VERSION ""

NS_ :

BS_:

BU_: CVC_B BCM_FL BCM_FR DUMMY_ECU DKCU BCM_R

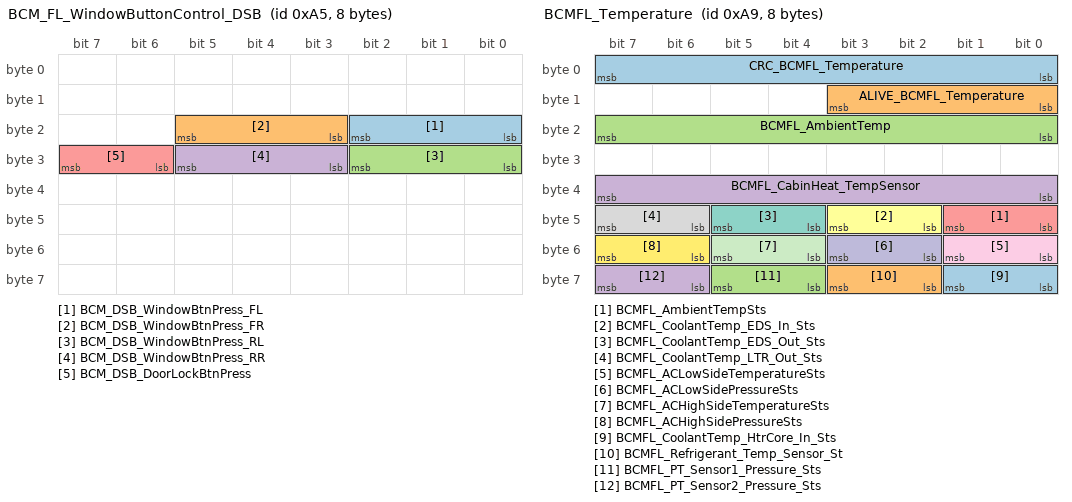
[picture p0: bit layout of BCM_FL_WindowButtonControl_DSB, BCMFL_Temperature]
BO_ 165 BCM_FL_WindowButtonControl_DSB: 8 BCM_FL
 SG_ BCM_DSB_WindowBtnPress_FL : 18|3@0+ (1,0) [0|7] ""  CVC_B
 SG_ BCM_DSB_WindowBtnPress_FR : 21|3@0+ (1,0) [0|7] ""  CVC_B
 SG_ BCM_DSB_WindowBtnPress_RL : 26|3@0+ (1,0) [0|7] ""  CVC_B
 SG_ BCM_DSB_WindowBtnPress_RR : 29|3@0+ (1,0) [0|7] ""  CVC_B
 SG_ BCM_DSB_DoorLockBtnPress : 31|2@0+ (1,0) [0|3] ""  CVC_B

BO_ 169 BCMFL_Temperature: 8 BCM_FL
 SG_ CRC_BCMFL_Temperature : 7|8@0+ (1,0) [0|255] ""  CVC_B,BCM_FR,DKCU,BCM_R
 SG_ ALIVE_BCMFL_Temperature : 11|4@0+ (1,0) [0|15] ""  CVC_B,BCM_FR,DKCU,BCM_R
 SG_ BCMFL_AmbientTemp : 23|8@0+ (0.5,-40) [-40|85] "Degree C"  CVC_B,BCM_FR,DKCU,BCM_R
 SG_ BCMFL_CabinHeat_TempSensor : 39|8@0+ (0.5,-40) [-40|85] "Degree C"  CVC_B,BCM_FR,DKCU,BCM_R
 SG_ BCMFL_AmbientTempSts : 41|2@0+ (1,0) [0|3] ""  CVC_B
 SG_ BCMFL_CoolantTemp_EDS_In_Sts : 43|2@0+ (1,0) [0|3] ""  CVC_B
 SG_ BCMFL_CoolantTemp_EDS_Out_Sts : 45|2@0+ (1,0) [0|3] ""  CVC_B
 SG_ BCMFL_CoolantTemp_LTR_Out_Sts : 47|2@0+ (1,0) [0|3] ""  CVC_B
 SG_ BCMFL_ACLowSideTemperatureSts : 49|2@0+ (1,0) [0|3] ""  CVC_B
 SG_ BCMFL_ACLowSidePressureSts : 51|2@0+ (1,0) [0|3] ""  CVC_B
 SG_ BCMFL_ACHighSideTemperatureSts : 53|2@0+ (1,0) [0|3] ""  CVC_B
 SG_ BCMFL_ACHighSidePressureSts : 55|2@0+ (1,0) [0|3] ""  CVC_B
 SG_ BCMFL_CoolantTemp_HtrCore_In_Sts : 57|2@0+ (1,0) [0|3] ""  CVC_B
 SG_ BCMFL_Refrigerant_Temp_Sensor_St : 59|2@0+ (1,0) [0|3] ""  CVC_B
 SG_ BCMFL_PT_Sensor1_Pressure_Sts : 61|2@0+ (1,0) [0|3] ""  CVC_B
 SG_ BCMFL_PT_Sensor2_Pressure_Sts : 63|2@0+ (1,0) [0|3] ""  CVC_B

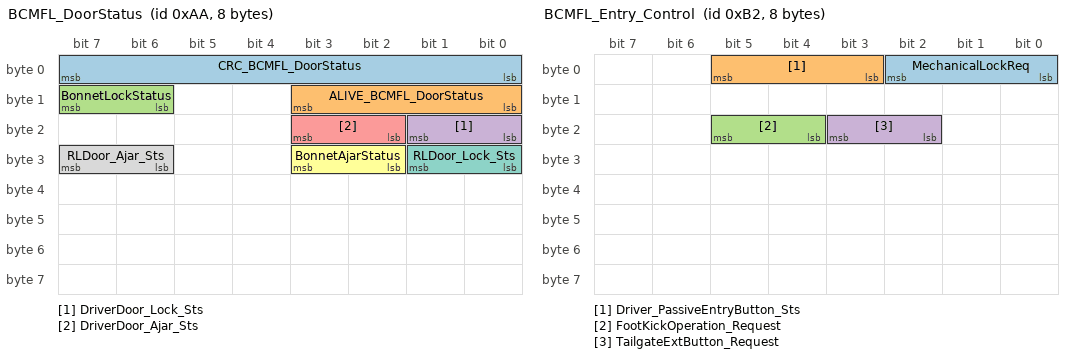
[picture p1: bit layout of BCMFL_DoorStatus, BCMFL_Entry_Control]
BO_ 170 BCMFL_DoorStatus: 8 BCM_FL
 SG_ CRC_BCMFL_DoorStatus : 7|8@0+ (1,0) [0|255] ""  CVC_B,DKCU
 SG_ ALIVE_BCMFL_DoorStatus : 11|4@0+ (1,0) [0|15] ""  CVC_B,DKCU
 SG_ BonnetLockStatus : 15|2@0+ (1,0) [0|3] ""  CVC_B,DKCU
 SG_ DriverDoor_Lock_Sts : 17|2@0+ (1,0) [0|3] ""  CVC_B,DKCU
 SG_ DriverDoor_Ajar_Sts : 19|2@0+ (1,0) [0|3] ""  CVC_B,DKCU
 SG_ BonnetAjarStatus : 27|2@0+ (1,0) [0|3] ""  CVC_B,DKCU
 SG_ RLDoor_Lock_Sts : 25|2@0+ (1,0) [0|3] ""  CVC_B,DKCU
 SG_ RLDoor_Ajar_Sts : 31|2@0+ (1,0) [0|3] ""  CVC_B,DKCU

BO_ 178 BCMFL_Entry_Control: 8 BCM_FL
 SG_ MechanicalLockReq : 2|3@0+ (1,0) [0|4] ""  CVC_B,DKCU
 SG_ Driver_PassiveEntryButton_Sts : 5|3@0+ (1,0) [0|4] ""  CVC_B,DKCU
 SG_ FootKickOperation_Request : 21|2@0+ (1,0) [0|3] ""  CVC_B,DKCU
 SG_ TailgateExtButton_Request : 19|2@0+ (1,0) [0|2] ""  CVC_B,DKCU

BO_ 180 BCM_WindowsFL_Status: 8 BCM_R
 SG_ CRC_BCM_WindowsFL_Status : 7|8@0+ (1,0) [0|255] ""  CVC_B
 SG_ ALIVE_BCM_WindowsFL_Status : 11|4@0+ (1,0) [0|15] ""  CVC_B
 SG_ BCMFL_WindowsFL_AntiPinch_Warn : 19|2@0+ (1,0) [0|3] ""  CVC_B
 SG_ BCMFL_WindowFL_Learning_Sts : 23|2@0+ (1,0) [0|3] ""  CVC_B
 SG_ BCMFL_WindowFL_Suppression_Warn : 25|2@0+ (1,0) [0|2] ""  CVC_B
 SG_ BCMFL_WindowFL_LockActive : 26|1@0+ (1,0) [0|1] ""  CVC_B
 SG_ BCMFL_WindowFL_ThermalProtect : 29|2@0+ (1,0) [0|2] ""  CVC_B
 SG_ BCMFL_WindowFL_Error : 27|1@0+ (1,0) [0|1] ""  CVC_B
 SG_ BCMFL_WindowsRL_AntiPinch_Warn : 33|2@0+ (1,0) [0|3] ""  CVC_B
 SG_ BCMFL_WindowRL_LockActive : 35|1@0+ (1,0) [0|1] ""  CVC_B
 SG_ BCMFL_WindowRL_Error : 34|1@0+ (1,0) [0|1] ""  CVC_B
 SG_ BCMFL_WindowRL_Learning_Sts : 37|2@0+ (1,0) [0|3] ""  CVC_B
 SG_ BCMFL_WindowRL_Suppression_Warn : 39|2@0+ (1,0) [0|2] ""  CVC_B
 SG_ BCMFL_WindowRL_ThermalProtect : 41|2@0+ (1,0) [0|2] ""  CVC_B
 SG_ Window_Position_FL : 51|4@0+ (1,0) [0|15] ""  CVC_B
 SG_ Window_Position_RL : 55|4@0+ (1,0) [0|15] ""  CVC_B
 SG_ BCMFL_WindowBtnPress_RL : 44|3@0+ (1,0) [0|4] ""  CVC_B
 SG_ BCMFL_WindowBtnPress_FL : 47|3@0+ (1,0) [0|4] ""  CVC_B
 SG_ BCMFL_WindowFL_Malfunction_Warn : 63|2@0+ (1,0) [0|3] ""  CVC_B
 SG_ BCMFL_WindowRL_Malfunction_Warn : 61|2@0+ (1,0) [0|3] ""  CVC_B

BO_ 198 BCMFL_ThermalComponents_Status_1: 32 BCM_FL
 SG_ CRC_BCMFL_ThermalComponents_Stat : 7|8@0+ (1,0) [0|255] ""  CVC_B
 SG_ ALIVE_BCMFL_ThermalComponents_St : 11|4@0+ (1,0) [0|15] ""  CVC_B
 SG_ BCMFL_CoolantLevel : 13|2@0+ (1,0) [0|3] ""  CVC_B
 SG_ BCMFL_CoolingFan_Status : 15|2@0+ (1,0) [0|3] ""  CVC_B
 SG_ BCMFL_FEDSPump_Status : 17|2@0+ (1,0) [0|3] ""  CVC_B
 SG_ BCMFL_BMSPump_Status : 19|2@0+ (1,0) [0|3] ""  CVC_B
 SG_ BCMFL_REDSPump_Status : 21|2@0+ (1,0) [0|3] ""  CVC_B
 SG_ BCMFL_HVMainRelay_Status : 23|2@0+ (1,0) [0|3] ""  CVC_B
 SG_ BCMFL_ACLowSidePressure : 31|7@0+ (0.1,0) [0|10.86] "Bar"  CVC_B
 SG_ BCMFL_ACHighSidePressure : 24|9@0+ (0.1,0) [0|37.27] "Bar"  CVC_B
 SG_ BCMFL_CoolantTemp_LTR_Out : 207|11@0+ (1,-40) [-40|130] "Degree C"  CVC_B
 SG_ BCMFL_CoolantTemp_EDS_In : 159|11@0+ (1,-40) [-40|130] "Degree C"  CVC_B
 SG_ BCMFL_CoolantTemp_EDS_Out : 191|11@0+ (1,-40) [-40|130] "Degree C"  CVC_B
 SG_ BCMFL_ACLowSideTemperature : 239|11@0+ (0.1,-40) [-40|150] "Degree C"  CVC_B
 SG_ BCMFL_ACHighSideTemperature : 223|11@0+ (0.1,-40) [-40|150] "Degree C"  CVC_B
 SG_ BCMFL_CoolantTemp_HtrCore_In : 175|11@0+ (1,-40) [-40|130] "Degree C"  CVC_B
 SG_ BCMFL_FEDSPump_Fault : 108|3@0+ (1,0) [0|7] ""  CVC_B
 SG_ BCMFL_BMSPump_Fault : 111|3@0+ (1,0) [0|7] ""  CVC_B
 SG_ BCMFL_SOV_Fault : 113|2@0+ (1,0) [0|3] ""  CVC_B
 SG_ BCMFL_CoolingFan_Fault : 116|3@0+ (1,0) [0|7] ""  CVC_B
 SG_ BCMFL_CoolantLevel2 : 118|2@0+ (1,0) [0|3] ""  CVC_B
 SG_ BCMFL_Refrigerant_Temp_Sensor : 55|8@0+ (1,-40) [-40|130] "Degree C"  CVC_B
 SG_ BCMFL_PT_Sensor1_Pressure : 151|8@0+ (1,0) [0|37.27] "Bar"  CVC_B
 SG_ BCMFL_PT_Sensor1_Temp : 135|8@0+ (1,-40) [-40|150] "Degree C"  CVC_B
 SG_ BCMFL_PT_Sensor2_Pressure : 143|8@0+ (1,0) [0|37.27] "Bar"  CVC_B
 SG_ BCMFL_PT_Sensor2_Temp : 127|8@0+ (1,-40) [-40|150] "Degree C"  CVC_B
 SG_ BCMFL_RearACLowSidePressureSts : 101|2@0+ (1,0) [0|3] ""  CVC_B
 SG_ BCMFL_RearACLowSideTemperatureSt : 99|2@0+ (1,0) [0|3] ""  CVC_B
 SG_ BCMFL_REDSPump_Fault : 105|3@0+ (1,0) [0|7] ""  CVC_B
 SG_ BCMFL_RearACLowSidePressure : 63|7@0+ (0.1,0) [0|10.86] "Bar"  CVC_B
 SG_ BCMFL_RearACLowSideTemperature : 56|11@0+ (0.1,-40) [-40|150] "Degree C"  CVC_B

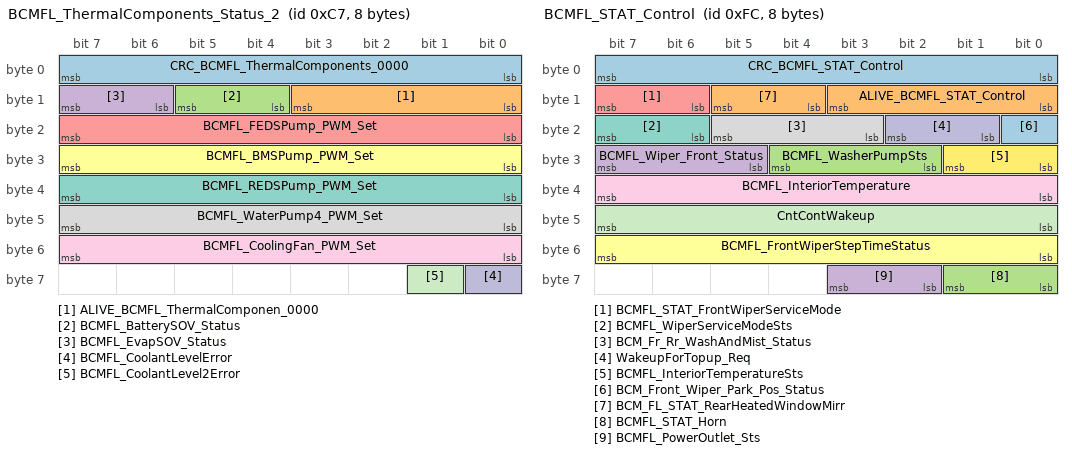
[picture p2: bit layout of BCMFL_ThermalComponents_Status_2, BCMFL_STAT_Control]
BO_ 199 BCMFL_ThermalComponents_Status_2: 8 BCM_FL
 SG_ CRC_BCMFL_ThermalComponents_0000 : 7|8@0+ (1,0) [0|255] ""  CVC_B
 SG_ ALIVE_BCMFL_ThermalComponen_0000 : 11|4@0+ (1,0) [0|15] ""  CVC_B
 SG_ BCMFL_BatterySOV_Status : 13|2@0+ (1,0) [0|3] ""  CVC_B
 SG_ BCMFL_EvapSOV_Status : 15|2@0+ (1,0) [0|3] ""  CVC_B
 SG_ BCMFL_FEDSPump_PWM_Set : 23|8@0+ (1,0) [0|100] "%"  CVC_B
 SG_ BCMFL_BMSPump_PWM_Set : 31|8@0+ (1,0) [0|100] "%"  CVC_B
 SG_ BCMFL_REDSPump_PWM_Set : 39|8@0+ (1,0) [0|100] "%"  CVC_B
 SG_ BCMFL_WaterPump4_PWM_Set : 47|8@0+ (1,0) [0|100] "%"  CVC_B
 SG_ BCMFL_CoolingFan_PWM_Set : 55|8@0+ (1,0) [0|100] "%"  CVC_B
 SG_ BCMFL_CoolantLevelError : 56|1@0+ (1,0) [0|1] ""  CVC_B
 SG_ BCMFL_CoolantLevel2Error : 57|1@0+ (1,0) [0|1] ""  CVC_B

BO_ 252 BCMFL_STAT_Control: 8 BCM_FL
 SG_ CRC_BCMFL_STAT_Control : 7|8@0+ (1,0) [0|255] ""  CVC_B
 SG_ ALIVE_BCMFL_STAT_Control : 11|4@0+ (1,0) [0|15] ""  CVC_B
 SG_ BCMFL_WasherPumpSts : 28|3@0+ (1,0) [0|3] ""  CVC_B
 SG_ BCMFL_Wiper_Front_Status : 31|3@0+ (1,0) [0|4] ""  CVC_B
 SG_ BCMFL_STAT_FrontWiperServiceMode : 15|2@0+ (1,0) [0|3] ""  CVC_B
 SG_ BCMFL_FrontWiperStepTimeStatus : 55|8@0+ (1,0) [0|255] "second"  CVC_B
 SG_ BCMFL_WiperServiceModeSts : 23|2@0+ (1,0) [0|2] ""  CVC_B
 SG_ BCM_Fr_Rr_WashAndMist_Status : 21|3@0+ (1,0) [0|7] ""  CVC_B
 SG_ BCMFL_InteriorTemperature : 39|8@0+ (1,-40) [-40|85] "Degree C"  CVC_B
 SG_ WakeupForTopup_Req : 18|2@0+ (1,0) [0|3] ""  CVC_B
 SG_ CntContWakeup : 47|8@0+ (1,0) [0|255] ""  CVC_B
 SG_ BCMFL_InteriorTemperatureSts : 25|2@0+ (1,0) [0|3] ""  CVC_B
 SG_ BCM_Front_Wiper_Park_Pos_Status : 16|1@0+ (1,0) [0|1] ""  CVC_B
 SG_ BCM_FL_STAT_RearHeatedWindowMirr : 13|2@0+ (1,0) [0|3] ""  CVC_B
 SG_ BCMFL_STAT_Horn : 57|2@0+ (1,0) [0|3] ""  CVC_B
 SG_ BCMFL_PowerOutlet_Sts : 59|2@0+ (1,0) [0|3] ""  CVC_B

BO_ 260 BCM_FL_Measured_Data: 12 BCM_FL
 SG_ CRC_BCM_FL_Measured_Data : 7|8@0+ (1,0) [0|255] ""  CVC_B
 SG_ ALIVE_BCM_FL_Measured_Data : 11|4@0+ (1,0) [0|15] ""  CVC_B
 SG_ SOH_SUL : 23|8@0+ (1,0) [0|100] "%"  CVC_B
 SG_ SOH_SUL_STATE : 29|2@0+ (1,0) [0|3] ""  CVC_B
 SG_ SOC_STATE : 31|2@0+ (1,0) [0|3] ""  CVC_B
 SG_ Resp_Error : 35|1@0+ (1,0) [0|1] ""  CVC_B
 SG_ FLAG_INCONSTENCY : 36|1@0+ (1,0) [0|1] ""  CVC_B
 SG_ EBS_error : 37|1@0+ (1,0) [0|1] ""  CVC_B
 SG_ FLAG_DISCONNECT : 38|1@0+ (1,0) [0|1] ""  CVC_B
 SG_ IBATT_QUIESCENT : 47|8@0+ (0.00390625,0) [0|0.984375] ""  CVC_B
 SG_ LV_TargetCurrent : 55|10@0+ (0.25,-128) [-128|127] "A"  CVC_B
 SG_ LV_TargetVoltage : 61|6@0+ (0.112903,9) [9|16] "V"  CVC_B
 SG_ LV_ContinuousWakeUpCnt : 71|8@0+ (1,0) [0|255] ""  CVC_B

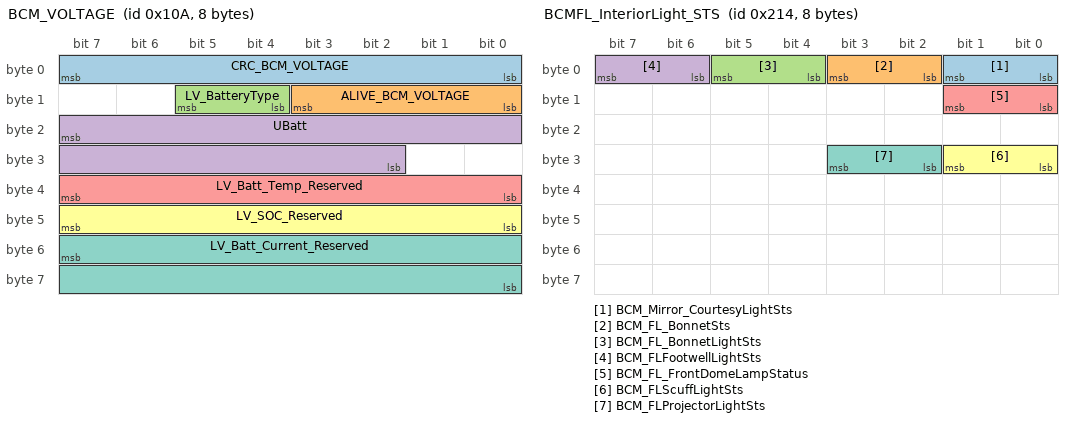
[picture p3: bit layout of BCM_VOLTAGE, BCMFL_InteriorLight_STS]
BO_ 266 BCM_VOLTAGE: 8 BCM_FL
 SG_ CRC_BCM_VOLTAGE : 7|8@0+ (1,0) [0|255] ""  CVC_B,BCM_FR,BCM_R
 SG_ ALIVE_BCM_VOLTAGE : 11|4@0+ (1,0) [0|15] ""  CVC_B,BCM_FR,BCM_R
 SG_ LV_BatteryType : 13|2@0+ (1,0) [0|3] ""  CVC_B,BCM_FR,BCM_R
 SG_ UBatt : 23|14@0+ (0.0009777,3) [3|18] "V"  CVC_B,BCM_FR,BCM_R
 SG_ LV_Batt_Temp_Reserved : 39|8@0+ (1,-40) [-40|105] "Degree C"  CVC_B,BCM_FR,BCM_R
 SG_ LV_SOC_Reserved : 47|8@0+ (1,0) [0|100] "%"  CVC_B,BCM_FR,BCM_R
 SG_ LV_Batt_Current_Reserved : 55|16@0+ (0.03125,-1536) [-1536|511.90625] "A"  CVC_B,BCM_FR,BCM_R

BO_ 277 BCM_Childlock: 8 BCM_FL
 SG_ BCM_ChildLock_Feedback : 7|2@0+ (1,0) [0|3] ""  CVC_B

BO_ 280 BCM_MHU_Ctrl_Fbk: 8 BCM_FL
 SG_ CRC_BCM_MHU_Ctrl_Fbk : 7|8@0+ (1,0) [0|255] ""  CVC_B
 SG_ ALIVE_BCM_MHU_Ctrl_Fbk : 11|4@0+ (1,0) [0|15] ""  CVC_B
 SG_ BCM_DrvInhibitStsFbk : 13|2@0+ (1,0) [0|3] ""  CVC_B

BO_ 529 BCMFL_ExteriorLight_STS: 16 BCM_FL
 SG_ CRC_BCMFL_ExteriorLight_STS : 7|8@0+ (1,0) [0|255] ""  CVC_B
 SG_ ALIVE_BCMFL_ExteriorLight_STS : 11|4@0+ (1,0) [0|15] ""  CVC_B
 SG_ BCM_LowBeam_FL_Sts : 102|3@0+ (1,0) [0|4] ""  CVC_B
 SG_ BCM_HighBeam_FL_Sts : 98|3@0+ (1,0) [0|4] ""  CVC_B
 SG_ BCM_TurnIndicator_FL_STS : 18|3@0+ (1,0) [0|4] ""  CVC_B
 SG_ BCM_PositionLight_FL_STS : 34|3@0+ (1,0) [0|4] ""  CVC_B
 SG_ BCM_RearFogLamp_FL_STS : 46|3@0+ (1,0) [0|4] ""  CVC_B
 SG_ BCM_HeightSensorSTS_Front : 71|2@0+ (1,0) [0|3] ""  CVC_B
 SG_ BCM_HeightSensorValue_Front : 69|14@0+ (0.5,0) [0|8191.5] ""  CVC_B
 SG_ BCM_MirrorLED_FL_STS : 82|3@0+ (1,0) [0|4] ""  CVC_B
 SG_ BCM_HazardButton_FL_STS : 86|3@0+ (1,0) [0|4] ""  CVC_B
 SG_ BCM_DaytimeRunningLight_FL_Sts : 90|3@0+ (1,0) [0|4] ""  CVC_B
 SG_ BCM_FrontFogLamp_FL_STS : 94|3@0+ (1,0) [0|4] ""  CVC_B

BO_ 532 BCMFL_InteriorLight_STS: 8 BCM_FL
 SG_ BCM_Mirror_CourtesyLightSts : 1|2@0+ (1,0) [0|3] ""  CVC_B
 SG_ BCM_FL_BonnetSts : 3|2@0+ (1,0) [0|3] ""  CVC_B
 SG_ BCM_FL_BonnetLightSts : 5|2@0+ (1,0) [0|3] ""  CVC_B
 SG_ BCM_FLFootwellLightSts : 7|2@0+ (1,0) [0|3] ""  CVC_B
 SG_ BCM_FL_FrontDomeLampStatus : 9|2@0+ (1,0) [0|3] ""  CVC_B
 SG_ BCM_FLScuffLightSts : 25|2@0+ (1,0) [0|3] ""  CVC_B
 SG_ BCM_FLProjectorLightSts : 27|2@0+ (1,0) [0|3] ""  CVC_B

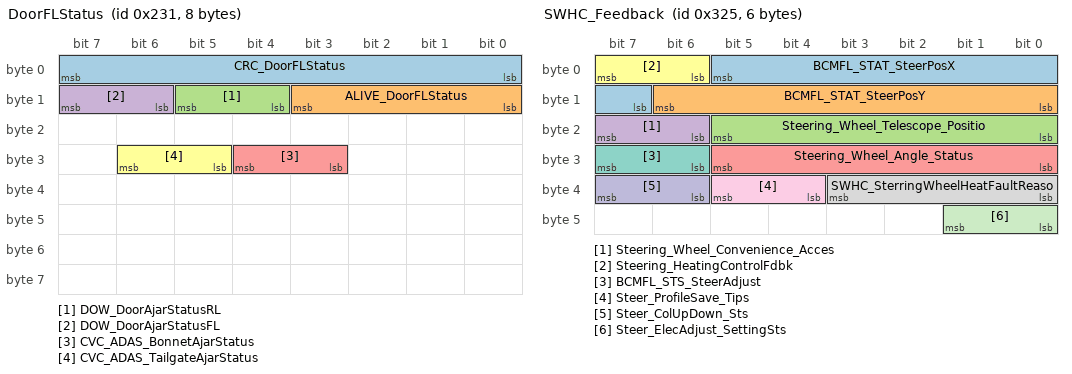
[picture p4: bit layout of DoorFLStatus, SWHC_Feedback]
BO_ 561 DoorFLStatus: 8 BCM_FL
 SG_ CRC_DoorFLStatus : 7|8@0+ (1,0) [0|255] ""  CVC_B
 SG_ ALIVE_DoorFLStatus : 11|4@0+ (1,0) [0|15] ""  CVC_B
 SG_ DOW_DoorAjarStatusRL : 13|2@0+ (1,0) [0|3] ""  CVC_B
 SG_ DOW_DoorAjarStatusFL : 15|2@0+ (1,0) [0|3] ""  CVC_B
 SG_ CVC_ADAS_BonnetAjarStatus : 28|2@0+ (1,0) [0|3] ""  CVC_B
 SG_ CVC_ADAS_TailgateAjarStatus : 30|2@0+ (1,0) [0|3] ""  CVC_B

BO_ 805 SWHC_Feedback: 6 BCM_FL
 SG_ BCMFL_STAT_SteerPosX : 5|7@0+ (1,-50) [-50|50] "mm"  CVC_B
 SG_ BCMFL_STAT_SteerPosY : 14|7@0+ (1,-50) [-50|50] "mm"  CVC_B
 SG_ Steering_Wheel_Telescope_Positio : 21|6@0+ (1,-20) [-20|20] "mm"  CVC_B
 SG_ Steering_Wheel_Convenience_Acces : 23|2@0+ (1,0) [0|3] ""  CVC_B
 SG_ Steering_Wheel_Angle_Status : 29|6@0+ (0.1,-2.1) [-2.1|2.1] "Degree"  CVC_B
 SG_ Steering_HeatingControlFdbk : 7|2@0+ (1,0) [0|3] ""  CVC_B
 SG_ BCMFL_STS_SteerAdjust : 31|2@0+ (1,0) [0|3] ""  CVC_B
 SG_ SWHC_SterringWheelHeatFaultReaso : 35|4@0+ (1,0) [0|15] ""  CVC_B
 SG_ Steer_ProfileSave_Tips : 37|2@0+ (1,0) [0|3] ""  CVC_B
 SG_ Steer_ColUpDown_Sts : 39|2@0+ (1,0) [0|3] ""  CVC_B
 SG_ Steer_ElecAdjust_SettingSts : 41|2@0+ (1,0) [0|3] ""  CVC_B

BO_ 1049 SHVU_FL_Confirm_Sts: 8 BCM_FL
 SG_ SHVU_STAT_SeatHeatingFrontL : 2|3@0+ (1,0) [0|7] ""  CVC_B
 SG_ SHVU_STAT_SeatCoolingFrontL : 10|3@0+ (1,0) [0|7] ""  CVC_B
 SG_ SHVU_STAT_FrontSeatVentSts : 15|2@0+ (1,0) [0|3] ""  CVC_B

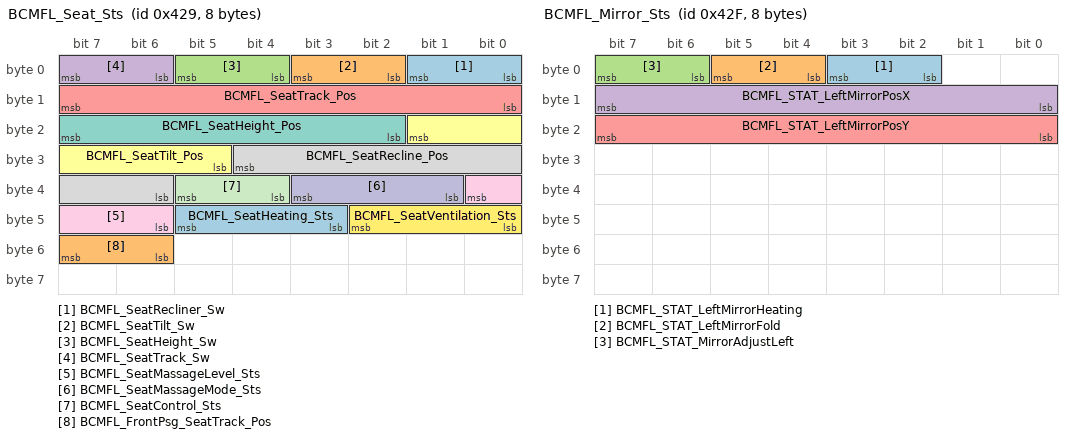
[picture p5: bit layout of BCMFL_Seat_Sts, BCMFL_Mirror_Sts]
BO_ 1065 BCMFL_Seat_Sts: 8 BCM_FL
 SG_ BCMFL_SeatRecliner_Sw : 1|2@0+ (1,0) [0|3] ""  CVC_B
 SG_ BCMFL_SeatTilt_Sw : 3|2@0+ (1,0) [0|3] ""  CVC_B
 SG_ BCMFL_SeatHeight_Sw : 5|2@0+ (1,0) [0|3] ""  CVC_B
 SG_ BCMFL_SeatTrack_Sw : 7|2@0+ (1,0) [0|3] ""  CVC_B
 SG_ BCMFL_SeatTrack_Pos : 15|8@0+ (1,0) [0|240] "mm"  CVC_B
 SG_ BCMFL_SeatTilt_Pos : 17|5@0+ (1,0) [0|18] "mm"  CVC_B
 SG_ BCMFL_SeatHeight_Pos : 23|6@0+ (1,0) [0|52] "mm"  CVC_B
 SG_ BCMFL_SeatRecline_Pos : 28|7@0+ (1,0) [0|70] "Degree"  CVC_B
 SG_ BCMFL_SeatMassageLevel_Sts : 32|3@0+ (1,0) [0|7] ""  CVC_B
 SG_ BCMFL_SeatMassageMode_Sts : 35|3@0+ (1,0) [0|7] ""  CVC_B
 SG_ BCMFL_SeatControl_Sts : 37|2@0+ (1,0) [0|3] ""  CVC_B
 SG_ BCMFL_SeatVentilation_Sts : 42|3@0+ (1,0) [0|7] ""  CVC_B
 SG_ BCMFL_SeatHeating_Sts : 45|3@0+ (1,0) [0|7] ""  CVC_B
 SG_ BCMFL_FrontPsg_SeatTrack_Pos : 55|2@0+ (1,0) [0|3] ""  CVC_B

BO_ 1071 BCMFL_Mirror_Sts: 8 BCM_FL
 SG_ BCMFL_STAT_LeftMirrorHeating : 3|2@0+ (1,0) [0|3] ""  CVC_B
 SG_ BCMFL_STAT_LeftMirrorFold : 5|2@0+ (1,0) [0|3] ""  CVC_B
 SG_ BCMFL_STAT_MirrorAdjustLeft : 7|2@0+ (1,0) [0|3] ""  CVC_B
 SG_ BCMFL_STAT_LeftMirrorPosX : 15|8@0+ (1,-15) [-15|15] "Degree"  CVC_B
 SG_ BCMFL_STAT_LeftMirrorPosY : 23|8@0+ (1,-15) [-15|15] "Degree"  CVC_B

BO_ 1111 BCM_FL_ALM_warning: 8 BCM_FL
 SG_ AmbLight_Error_Z3 : 0|1@0+ (1,0) [0|1] ""  CVC_B
 SG_ AmbLight_Linerror_Z3 : 1|1@0+ (1,0) [0|1] ""  CVC_B
 SG_ AmbLight_Error_Z3B : 2|1@0+ (1,0) [0|1] ""  CVC_B
 SG_ AmbLight_Linerror_Z3B : 3|1@0+ (1,0) [0|1] ""  CVC_B

BO_ 1118 BCM_Heater_Feedback: 4 BCM_FL
 SG_ CRC_BCM_Heater_Feedback : 7|8@0+ (1,0) [0|255] ""  CVC_B
 SG_ ALIVE_BCM_Heater_Feedback : 11|4@0+ (1,0) [0|15] ""  CVC_B
 SG_ BCM_HeaterActivation_Feedback : 16|1@0+ (1,0) [0|1] ""  CVC_B

BO_ 1153 BCM_FL_WarnMsg_FL: 8 BCM_FL
 SG_ CRC_BCM_FL_WarnMsg_FL : 7|8@0+ (1,0) [0|255] ""  CVC_B
 SG_ ALIVE_BCM_FL_WarnMsg_FL : 11|4@0+ (1,0) [0|15] ""  CVC_B
 SG_ BCM_FL_TurnOffPosLightRemindr : 17|1@0+ (1,0) [0|1] ""  CVC_B
 SG_ BCM_FL_StopLightDefect : 19|1@0+ (1,0) [0|1] ""  CVC_B
 SG_ BCM_FL_LowBeamDefect : 20|1@0+ (1,0) [0|1] ""  CVC_B
 SG_ BCM_FL_HighBeamDefect : 21|1@0+ (1,0) [0|1] ""  CVC_B
 SG_ BCM_FL_PositionLightDefect : 22|1@0+ (1,0) [0|1] ""  CVC_B
 SG_ BCM_FL_CHMLS_Defect : 23|1@0+ (1,0) [0|1] ""  CVC_B
 SG_ BCM_FL_LicencePlateLight_Defect : 24|1@0+ (1,0) [0|1] ""  CVC_B
 SG_ BCM_FL_FrontFog_Defect : 25|1@0+ (1,0) [0|1] ""  CVC_B
 SG_ BCM_FL_RearLeftDoorLockDefect : 26|1@0+ (1,0) [0|1] ""  CVC_B
 SG_ BCM_FL_ReverseLightDefect : 27|1@0+ (1,0) [0|1] ""  CVC_B
 SG_ BCM_FL_12VBattery_LowLevel : 29|1@0+ (1,0) [0|1] ""  CVC_B
 SG_ BCM_FL_12VBattery_Discharging : 31|1@0+ (1,0) [0|1] ""  CVC_B
 SG_ BCM_FL_TurnIndicatorDefect : 32|1@0+ (1,0) [0|1] ""  CVC_B
 SG_ BCM_FL_IDB_Brakelight_Malfunctio : 41|1@0+ (1,0) [0|1] ""  CVC_B
 SG_ BCM_FL_CVC_Brakelight_Malfunctio : 42|1@0+ (1,0) [0|1] ""  CVC_B
 SG_ BCM_FL_ADAS_Turnlight_Malfunctio : 43|1@0+ (1,0) [0|1] ""  CVC_B
 SG_ BCM_FL_ADAS_Highbeam_Malfunction : 44|1@0+ (1,0) [0|1] ""  CVC_B
 SG_ BCM_FL_ADAS_LowBeam_Malfunction : 45|1@0+ (1,0) [0|1] ""  CVC_B
 SG_ BCM_FL_CVC_B_Malfunction : 46|1@0+ (1,0) [0|1] ""  CVC_B
 SG_ BCM_FL_BCM_Malfunction : 47|1@0+ (1,0) [0|1] ""  CVC_B
 SG_ BCM_FL_CrashSignalDefect : 49|1@0+ (1,0) [0|1] ""  CVC_B
 SG_ BCM_FL_RearFog_Defect : 50|1@0+ (1,0) [0|1] ""  CVC_B
 SG_ BCM_FL_FrontWiperDefect : 51|1@0+ (1,0) [0|1] ""  CVC_B
 SG_ BCM_FL_FrontLeftDoorLockDefect : 55|1@0+ (1,0) [0|1] ""  CVC_B
 SG_ BCM_FL_RLT_Malfunction : 60|1@0+ (1,0) [0|1] ""  CVC_B
 SG_ BCM_FL_BCM_POWER_Malfunction : 61|1@0+ (1,0) [0|1] ""  CVC_B
 SG_ BCM_FL_LossCommGearStatus : 63|1@0+ (1,0) [0|1] ""  CVC_B

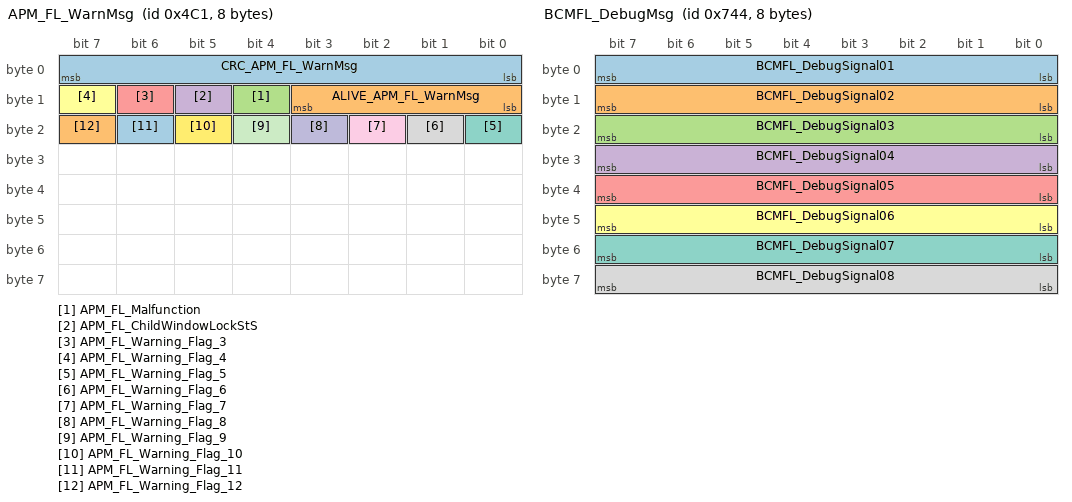
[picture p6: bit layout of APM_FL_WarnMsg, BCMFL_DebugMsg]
BO_ 1217 APM_FL_WarnMsg: 8 BCM_FL
 SG_ CRC_APM_FL_WarnMsg : 7|8@0+ (1,0) [0|255] ""  CVC_B
 SG_ ALIVE_APM_FL_WarnMsg : 11|4@0+ (1,0) [0|15] ""  CVC_B
 SG_ APM_FL_Malfunction : 12|1@0+ (1,0) [0|1] ""  CVC_B
 SG_ APM_FL_ChildWindowLockStS : 13|1@0+ (1,0) [0|1] ""  CVC_B
 SG_ APM_FL_Warning_Flag_3 : 14|1@0+ (1,0) [0|1] ""  CVC_B
 SG_ APM_FL_Warning_Flag_4 : 15|1@0+ (1,0) [0|1] ""  CVC_B
 SG_ APM_FL_Warning_Flag_5 : 16|1@0+ (1,0) [0|1] ""  CVC_B
 SG_ APM_FL_Warning_Flag_6 : 17|1@0+ (1,0) [0|1] ""  CVC_B
 SG_ APM_FL_Warning_Flag_7 : 18|1@0+ (1,0) [0|1] ""  CVC_B
 SG_ APM_FL_Warning_Flag_8 : 19|1@0+ (1,0) [0|1] ""  CVC_B
 SG_ APM_FL_Warning_Flag_9 : 20|1@0+ (1,0) [0|1] ""  CVC_B
 SG_ APM_FL_Warning_Flag_10 : 21|1@0+ (1,0) [0|1] ""  CVC_B
 SG_ APM_FL_Warning_Flag_11 : 22|1@0+ (1,0) [0|1] ""  CVC_B
 SG_ APM_FL_Warning_Flag_12 : 23|1@0+ (1,0) [0|1] ""  CVC_B

BO_ 1860 BCMFL_DebugMsg: 8 BCM_FL
 SG_ BCMFL_DebugSignal01 : 7|8@0+ (1,0) [0|255] ""  CVC_B
 SG_ BCMFL_DebugSignal02 : 15|8@0+ (1,0) [0|255] ""  CVC_B
 SG_ BCMFL_DebugSignal03 : 23|8@0+ (1,0) [0|255] ""  CVC_B
 SG_ BCMFL_DebugSignal04 : 31|8@0+ (1,0) [0|255] ""  CVC_B
 SG_ BCMFL_DebugSignal05 : 39|8@0+ (1,0) [0|255] ""  CVC_B
 SG_ BCMFL_DebugSignal06 : 47|8@0+ (1,0) [0|255] ""  CVC_B
 SG_ BCMFL_DebugSignal07 : 55|8@0+ (1,0) [0|255] ""  CVC_B
 SG_ BCMFL_DebugSignal08 : 63|8@0+ (1,0) [0|255] ""  CVC_B

BO_ 1973 BCM_FL_Synchronization_Req: 8 BCM_FL
 SG_ BCMFL_Req_RandomData : 7|24@0+ (1,0) [0|16777215] ""  CVC_B
 SG_ BCMFL_Req_MAC : 31|40@0+ (1,0) [0|1099511627775] ""  CVC_B

BO_ 160 BCMFR_KeyFOB_Status: 24 BCM_FR
 SG_ CRC_BCMFR_KeyFOB_Status : 7|8@0+ (1,0) [0|255] ""  CVC_B,BCM_FL
 SG_ ALIVE_BCMFR_KeyFOB_Status : 11|4@0+ (1,0) [0|15] ""  CVC_B,BCM_FL
 SG_ KeyFOBAuthenStatus : 19|4@0+ (1,0) [0|15] ""  CVC_B
 SG_ KeyFOBPosition : 23|4@0+ (1,0) [0|15] ""  CVC_B,BCM_FL
 SG_ FobId : 27|4@0+ (1,0) [0|15] ""  CVC_B
 SG_ BCMFR_KeyFob_LowBattery : 29|1@0+ (1,0) [0|1] ""  CVC_B
 SG_ BCMFR_KeyIgnoringStatus : 31|2@0+ (1,0) [0|3] ""  CVC_B
 SG_ KeyFOB_Authen_Process : 33|2@0+ (1,0) [0|3] ""  CVC_B
 SG_ BCM_KeyFob_WindowOpen_Sts : 28|1@0+ (1,0) [0|1] ""  CVC_B
 SG_ Secure_ResetCnt_0x0A0 : 135|16@0+ (1,0) [0|65535] ""  CVC_B
 SG_ Secure_MsgCnt_0x0A0 : 151|16@0+ (1,0) [0|65535] ""  CVC_B
 SG_ Secure_MAC_0x0A0 : 167|32@0+ (1,0) [0|4294967295] ""  CVC_B

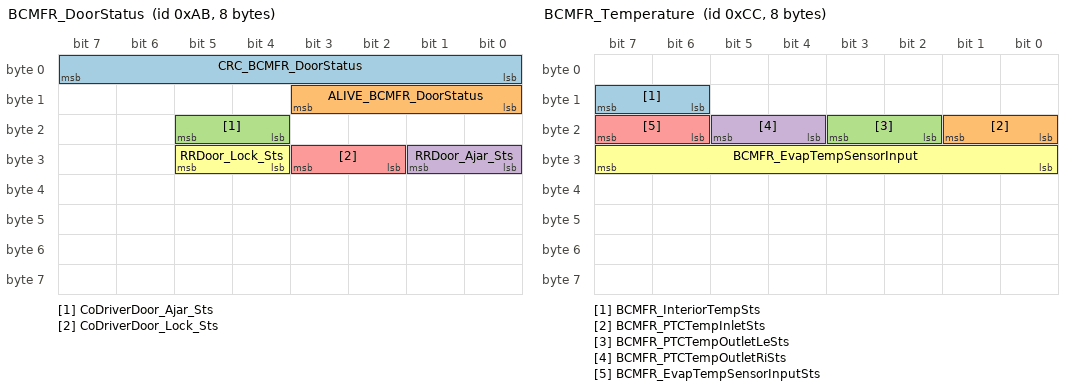
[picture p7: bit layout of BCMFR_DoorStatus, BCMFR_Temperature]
BO_ 171 BCMFR_DoorStatus: 8 BCM_FR
 SG_ CRC_BCMFR_DoorStatus : 7|8@0+ (1,0) [0|255] ""  CVC_B,DKCU
 SG_ ALIVE_BCMFR_DoorStatus : 11|4@0+ (1,0) [0|15] ""  CVC_B,DKCU
 SG_ CoDriverDoor_Ajar_Sts : 21|2@0+ (1,0) [0|3] ""  CVC_B,DKCU
 SG_ RRDoor_Ajar_Sts : 25|2@0+ (1,0) [0|3] ""  CVC_B,DKCU
 SG_ CoDriverDoor_Lock_Sts : 27|2@0+ (1,0) [0|3] ""  CVC_B,DKCU
 SG_ RRDoor_Lock_Sts : 29|2@0+ (1,0) [0|3] ""  CVC_B,DKCU

BO_ 177 BCMFR_Entry_Control: 24 BCM_FR
 SG_ KeyFOB_Request : 19|4@0+ (1,0) [0|15] ""  CVC_B
 SG_ CoDriver_PassiveEntryButton_Sts : 31|3@0+ (1,0) [0|4] ""  CVC_B
 SG_ Secure_ResetCnt_0x0B1 : 135|16@0+ (1,0) [0|65535] ""  CVC_B
 SG_ Secure_MsgCnt_0x0B1 : 151|16@0+ (1,0) [0|65535] ""  CVC_B
 SG_ Secure_MAC_0x0B1 : 167|32@0+ (1,0) [0|4294967295] ""  CVC_B

BO_ 181 BCM_WindowsFR_Status: 8 BCM_FR
 SG_ CRC_BCM_WindowsFR_Status : 7|8@0+ (1,0) [0|255] ""  CVC_B
 SG_ ALIVE_BCM_WindowsFR_Status : 11|4@0+ (1,0) [0|15] ""  CVC_B
 SG_ BCMFR_WindowsFR_AntiPinch_Warn : 19|2@0+ (1,0) [0|3] ""  CVC_B
 SG_ BCMFR_WindowFR_Learning_Sts : 23|2@0+ (1,0) [0|3] ""  CVC_B
 SG_ BCMFR_WindowFR_Suppression_Warn : 25|2@0+ (1,0) [0|2] ""  CVC_B
 SG_ BCMFR_WindowFR_LockActive : 26|1@0+ (1,0) [0|1] ""  CVC_B
 SG_ BCMFR_WindowFR_ThermalProtect : 29|2@0+ (1,0) [0|2] ""  CVC_B
 SG_ BCMFR_WindowFR_Error : 27|1@0+ (1,0) [0|1] ""  CVC_B
 SG_ BCMFR_WindowsRR_AntiPinch_Warn : 33|2@0+ (1,0) [0|3] ""  CVC_B
 SG_ BCMFR_WindowRR_LockActive : 35|1@0+ (1,0) [0|1] ""  CVC_B
 SG_ BCMFR_WindowRR_Error : 34|1@0+ (1,0) [0|1] ""  CVC_B
 SG_ BCMFR_WindowRR_Learning_Sts : 37|2@0+ (1,0) [0|3] ""  CVC_B
 SG_ BCMFR_WindowRR_Suppression_Warn : 39|2@0+ (1,0) [0|2] ""  CVC_B
 SG_ BCMFR_WindowRR_ThermalProtect : 41|2@0+ (1,0) [0|2] ""  CVC_B
 SG_ BCMFR_WindowBtnPress_FrontPass : 44|3@0+ (1,0) [0|4] ""  CVC_B
 SG_ Window_Position_FR : 51|4@0+ (1,0) [0|15] ""  CVC_B
 SG_ Window_Position_RR : 55|4@0+ (1,0) [0|15] ""  CVC_B
 SG_ BCMFR_WindowBtnPress_RR : 47|3@0+ (1,0) [0|4] ""  CVC_B
 SG_ BCMFR_WindowFR_Malfunction_Warn : 63|2@0+ (1,0) [0|3] ""  CVC_B
 SG_ BCMFR_WindowRR_Malfunction_Warn : 61|2@0+ (1,0) [0|3] ""  CVC_B

BO_ 194 BCMFR_AQS_Input: 8 BCM_FR
 SG_ BCMFR_AQS_NOx_Input : 23|9@0+ (0.1,55) [55|95] "%"  CVC_B
 SG_ BCMFR_AQS_COx_Input : 30|9@0+ (0.1,5) [5|45] "%"  CVC_B
 SG_ BCMFR_AQS_PreHeating_Input : 37|9@0+ (0.01,0) [0|5] "V"  CVC_B

BO_ 195 BCMFR_DuctTemperature: 24 BCM_FR
 SG_ BCMFR_DuctTempRightFace : 7|11@0+ (0.1,-30) [-30|100] "Degree C"  CVC_B
 SG_ BCMFR_DuctTempLeftFace : 12|11@0+ (0.1,-30) [-30|100] "Degree C"  CVC_B
 SG_ BCMFR_DuctTempRightFoot : 148|11@0+ (0.1,-30) [-30|100] "Degree C"  CVC_B
 SG_ BCMFR_DuctTempLeftFoot : 143|11@0+ (0.1,-30) [-30|100] "Degree C"  CVC_B
 SG_ BCMFR_DuctTempSensor5Input : 39|8@0+ (1,-40) [-40|85] "Degree C"  CVC_B
 SG_ BCMFR_DuctTempSensor6Input : 47|8@0+ (1,-40) [-40|85] "Degree C"  CVC_B
 SG_ BCMFR_DuctTempSensor7Input : 55|8@0+ (1,-40) [-40|85] "Degree C"  CVC_B
 SG_ BCMFR_DuctTempSensor8Input : 63|8@0+ (1,-40) [-40|85] "Degree C"  CVC_B
 SG_ BCMFR_PTCTempInlet : 71|8@0+ (1,-40) [-40|100] "Degree C"  CVC_B
 SG_ BCMFR_PTCTempOutletLe : 79|8@0+ (1,-40) [-40|125] "Degree C"  CVC_B
 SG_ BCMFR_PTCTempOutletRi : 87|8@0+ (1,-40) [-40|125] "Degree C"  CVC_B
 SG_ BCMFR_InteriorTemp : 95|8@0+ (1,-40) [-40|85] "Degree C"  CVC_B
 SG_ BCMFR_Humidity : 103|8@0+ (1,0) [0|100] "%"  CVC_B
 SG_ BCMFR_HumiditySts : 117|2@0+ (1,0) [0|3] ""  CVC_B
 SG_ BCMFR_PM25 : 111|10@0+ (1,0) [0|1000] "ug/m3"  CVC_B
 SG_ BCMFR_PM25Sts : 115|2@0+ (1,0) [0|3] ""  CVC_B
 SG_ BCMFR_CO2 : 127|8@0+ (100,0) [0|10000] "ppm"  CVC_B
 SG_ BCMFR_CO2Sts : 113|2@0+ (1,0) [0|3] ""  CVC_B
 SG_ BCMFR_DucTempRightFaceSts : 129|2@0+ (1,0) [0|3] ""  CVC_B
 SG_ BCMFR_DucTempLeftFaceSts : 131|2@0+ (1,0) [0|3] ""  CVC_B
 SG_ BCMFR_DucTempRightFootSts : 133|2@0+ (1,0) [0|3] ""  CVC_B
 SG_ BCMFR_DucTempLeftFootSts : 135|2@0+ (1,0) [0|3] ""  CVC_B
 SG_ BCMFR_RearEvapTempSensorInput : 31|8@0+ (1,-40) [-40|85] "Degree C"  CVC_B
 SG_ BCMFR_RearEvapTempSensorInputSts : 153|2@0+ (1,0) [0|3] ""  CVC_B
 SG_ BCMFR_RearVentDuctTemp : 167|11@0+ (0.1,-30) [-30|100] "Degree C"  CVC_B
 SG_ BCMFR_RearFootDuctTemp : 172|11@0+ (0.1,-30) [-30|100] "Degree C"  CVC_B
 SG_ BCMFR_RearVentDuctTempSts : 177|2@0+ (1,0) [0|3] ""  CVC_B
 SG_ BCMFR_RearFootDuctTempSts : 17|2@0+ (1,0) [0|3] ""  CVC_B

BO_ 200 BCMFR_Climate_Feedback: 12 BCM_FR
 SG_ BCMFR_Climate_IonizerSts : 7|2@0+ (1,0) [0|3] ""  CVC_B
 SG_ BCMFR_Climate_AirDistFlapPos : 23|8@0+ (1,0) [0|100] "%"  CVC_B
 SG_ BCMFR_Climate_RHTempFlapPos : 31|8@0+ (1,0) [0|100] "%"  CVC_B
 SG_ BCMFR_Climate_LHTempFlapPos : 39|8@0+ (1,0) [0|100] "%"  CVC_B
 SG_ BCMFR_Climate_BlowerRelay : 47|2@0+ (1,0) [0|3] ""  CVC_B
 SG_ BCMFR_Climate_BlowerStatus : 52|1@0+ (1,0) [0|1] ""  CVC_B
 SG_ BCMFR_Climate_LHTempFlapSts : 53|1@0+ (1,0) [0|1] ""  CVC_B
 SG_ BCMFR_Climate_RHTempFlapSts : 54|1@0+ (1,0) [0|1] ""  CVC_B
 SG_ BCMFR_Climate_AirDistFlapSts : 55|1@0+ (1,0) [0|1] ""  CVC_B
 SG_ BCMFR_Climate_AirRecirculationPo : 63|8@0+ (1,0) [0|100] "%"  CVC_B
 SG_ BCMFR_Climate_AirDistFlapLHPos : 15|8@0+ (1,0) [0|100] "%"  CVC_B
 SG_ BCMFR_Climate_AirDistFlapLHSts : 51|1@0+ (1,0) [0|1] ""  CVC_B
 SG_ BCMFR_Climate_AirRecirSts : 5|1@0+ (1,0) [0|1] ""  CVC_B

BO_ 204 BCMFR_Temperature: 8 BCM_FR
 SG_ BCMFR_InteriorTempSts : 15|2@0+ (1,0) [0|3] ""  CVC_B
 SG_ BCMFR_PTCTempInletSts : 17|2@0+ (1,0) [0|3] ""  CVC_B
 SG_ BCMFR_PTCTempOutletLeSts : 19|2@0+ (1,0) [0|3] ""  CVC_B
 SG_ BCMFR_PTCTempOutletRiSts : 21|2@0+ (1,0) [0|3] ""  CVC_B
 SG_ BCMFR_EvapTempSensorInputSts : 23|2@0+ (1,0) [0|3] ""  CVC_B
 SG_ BCMFR_EvapTempSensorInput : 31|8@0+ (1,-40) [-40|85] "Degree C"  CVC_B

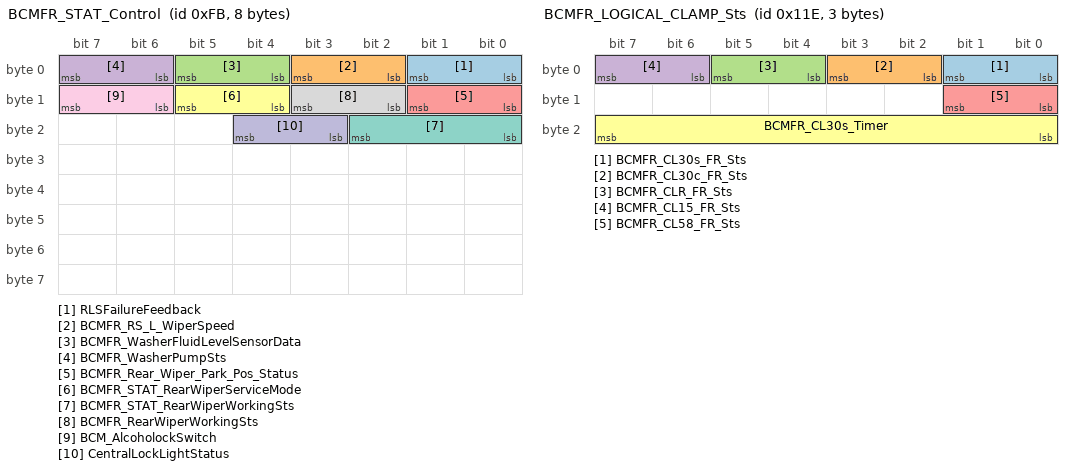
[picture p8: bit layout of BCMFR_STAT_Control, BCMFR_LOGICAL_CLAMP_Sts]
BO_ 251 BCMFR_STAT_Control: 8 BCM_FR
 SG_ RLSFailureFeedback : 1|2@0+ (1,0) [0|3] ""  CVC_B
 SG_ BCMFR_RS_L_WiperSpeed : 3|2@0+ (1,0) [0|3] ""  CVC_B
 SG_ BCMFR_WasherFluidLevelSensorData : 5|2@0+ (1,0) [0|3] ""  CVC_B
 SG_ BCMFR_WasherPumpSts : 7|2@0+ (1,0) [0|3] ""  CVC_B
 SG_ BCMFR_Rear_Wiper_Park_Pos_Status : 9|2@0+ (1,0) [0|3] ""  CVC_B
 SG_ BCMFR_STAT_RearWiperServiceMode : 13|2@0+ (1,0) [0|3] ""  CVC_B
 SG_ BCMFR_STAT_RearWiperWorkingSts : 18|3@0+ (1,0) [0|7] ""  CVC_B
 SG_ BCMFR_RearWiperWorkingSts : 11|2@0+ (1,0) [0|2] ""  CVC_B
 SG_ BCM_AlcoholockSwitch : 15|2@0+ (1,0) [0|3] ""  CVC_B
 SG_ CentralLockLightStatus : 20|2@0+ (1,0) [0|3] ""  CVC_B

BO_ 279 BCM_FR_Stat_SwtLightBrightness: 8 BCM_FR
 SG_ BCM_Stat_SwitchLightBrightness : 7|8@0+ (0.4,0) [0|100] "%"  CVC_B

BO_ 286 BCMFR_LOGICAL_CLAMP_Sts: 3 BCM_FR
 SG_ BCMFR_CL30s_FR_Sts : 1|2@0+ (1,0) [0|3] ""  CVC_B
 SG_ BCMFR_CL30c_FR_Sts : 3|2@0+ (1,0) [0|3] ""  CVC_B
 SG_ BCMFR_CLR_FR_Sts : 5|2@0+ (1,0) [0|3] ""  CVC_B
 SG_ BCMFR_CL15_FR_Sts : 7|2@0+ (1,0) [0|3] ""  CVC_B
 SG_ BCMFR_CL58_FR_Sts : 9|2@0+ (1,0) [0|3] ""  CVC_B
 SG_ BCMFR_CL30s_Timer : 23|8@0+ (1,0) [0|255] "s"  CVC_B

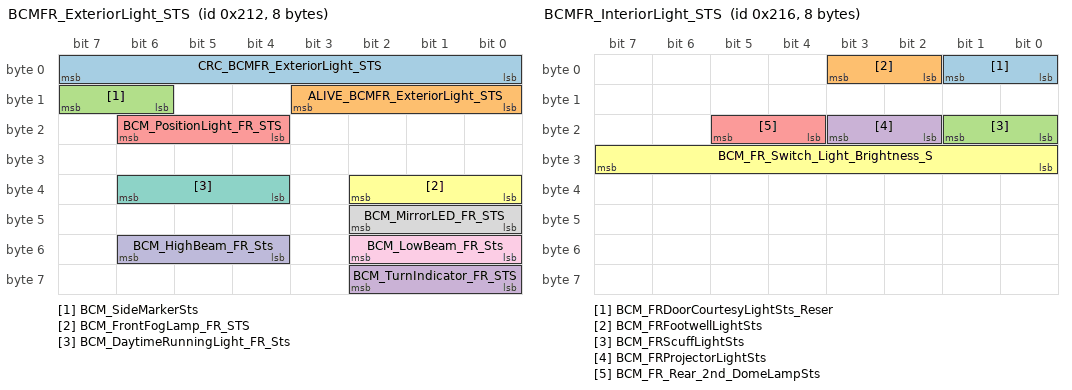
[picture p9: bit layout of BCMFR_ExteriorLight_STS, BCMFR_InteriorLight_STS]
BO_ 530 BCMFR_ExteriorLight_STS: 8 BCM_FR
 SG_ CRC_BCMFR_ExteriorLight_STS : 7|8@0+ (1,0) [0|255] ""  CVC_B
 SG_ ALIVE_BCMFR_ExteriorLight_STS : 11|4@0+ (1,0) [0|15] ""  CVC_B
 SG_ BCM_SideMarkerSts : 15|2@0+ (1,0) [0|3] ""  CVC_B
 SG_ BCM_TurnIndicator_FR_STS : 58|3@0+ (1,0) [0|4] ""  CVC_B
 SG_ BCM_PositionLight_FR_STS : 22|3@0+ (1,0) [0|4] ""  CVC_B
 SG_ BCM_FrontFogLamp_FR_STS : 34|3@0+ (1,0) [0|4] ""  CVC_B
 SG_ BCM_DaytimeRunningLight_FR_Sts : 38|3@0+ (1,0) [0|4] ""  CVC_B
 SG_ BCM_MirrorLED_FR_STS : 42|3@0+ (1,0) [0|4] ""  CVC_B
 SG_ BCM_LowBeam_FR_Sts : 50|3@0+ (1,0) [0|4] ""  CVC_B
 SG_ BCM_HighBeam_FR_Sts : 54|3@0+ (1,0) [0|4] ""  CVC_B

BO_ 534 BCMFR_InteriorLight_STS: 8 BCM_FR
 SG_ BCM_FRDoorCourtesyLightSts_Reser : 1|2@0+ (1,0) [0|3] ""  CVC_B
 SG_ BCM_FRFootwellLightSts : 3|2@0+ (1,0) [0|3] ""  CVC_B
 SG_ BCM_FRScuffLightSts : 17|2@0+ (1,0) [0|3] ""  CVC_B
 SG_ BCM_FRProjectorLightSts : 19|2@0+ (1,0) [0|3] ""  CVC_B
 SG_ BCM_FR_Rear_2nd_DomeLampSts : 21|2@0+ (1,0) [0|3] ""  CVC_B
 SG_ BCM_FR_Switch_Light_Brightness_S : 31|8@0+ (0.4,0) [0|100] "%"  CVC_B

BO_ 584 DoorFRStatus: 8 BCM_FR
 SG_ CRC_DoorFRStatus : 7|8@0+ (1,0) [0|255] ""  CVC_B
 SG_ ALIVE_DoorFRStatus : 11|4@0+ (1,0) [0|15] ""  CVC_B
 SG_ DOW_DoorAjarStatusRR : 13|2@0+ (1,0) [0|3] ""  CVC_B
 SG_ DOW_DoorAjarStatusFR : 15|2@0+ (1,0) [0|3] ""  CVC_B

BO_ 809 BCM_ODO: 8 BCM_FR
 SG_ CRC_BCM_ODO : 7|8@0+ (1,0) [0|255] ""  CVC_B
 SG_ ALIVE_BCM_ODO : 11|4@0+ (1,0) [0|15] ""  CVC_B
 SG_ Odometer_BCM : 23|20@0+ (1,0) [0|999999] "km"  CVC_B

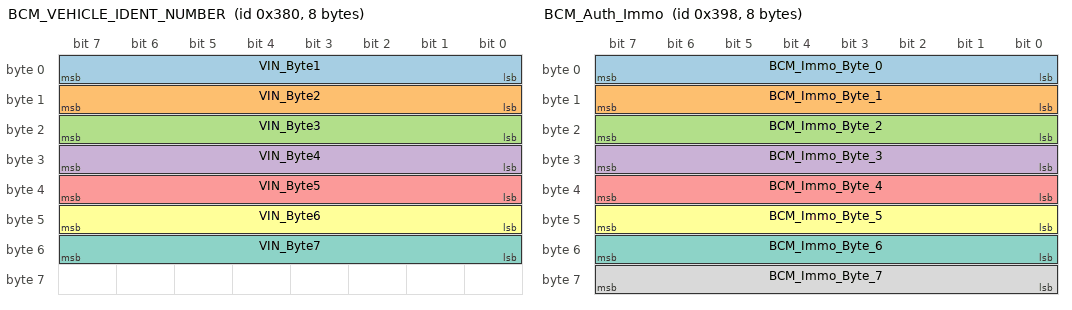
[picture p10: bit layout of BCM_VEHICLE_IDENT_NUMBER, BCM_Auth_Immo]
BO_ 896 BCM_VEHICLE_IDENT_NUMBER: 8 BCM_FR
 SG_ VIN_Byte1 : 7|8@0+ (1,0) [0|255] ""  CVC_B
 SG_ VIN_Byte2 : 15|8@0+ (1,0) [0|255] ""  CVC_B
 SG_ VIN_Byte3 : 23|8@0+ (1,0) [0|255] ""  CVC_B
 SG_ VIN_Byte4 : 31|8@0+ (1,0) [0|255] ""  CVC_B
 SG_ VIN_Byte5 : 39|8@0+ (1,0) [0|255] ""  CVC_B
 SG_ VIN_Byte6 : 47|8@0+ (1,0) [0|255] ""  CVC_B
 SG_ VIN_Byte7 : 55|8@0+ (1,0) [0|255] ""  CVC_B

BO_ 920 BCM_Auth_Immo: 8 BCM_FR
 SG_ BCM_Immo_Byte_0 : 7|8@0+ (1,0) [0|255] ""  CVC_B
 SG_ BCM_Immo_Byte_1 : 15|8@0+ (1,0) [0|255] ""  CVC_B
 SG_ BCM_Immo_Byte_2 : 23|8@0+ (1,0) [0|255] ""  CVC_B
 SG_ BCM_Immo_Byte_3 : 31|8@0+ (1,0) [0|255] ""  CVC_B
 SG_ BCM_Immo_Byte_4 : 39|8@0+ (1,0) [0|255] ""  CVC_B
 SG_ BCM_Immo_Byte_5 : 47|8@0+ (1,0) [0|255] ""  CVC_B
 SG_ BCM_Immo_Byte_6 : 55|8@0+ (1,0) [0|255] ""  CVC_B
 SG_ BCM_Immo_Byte_7 : 63|8@0+ (1,0) [0|255] ""  CVC_B

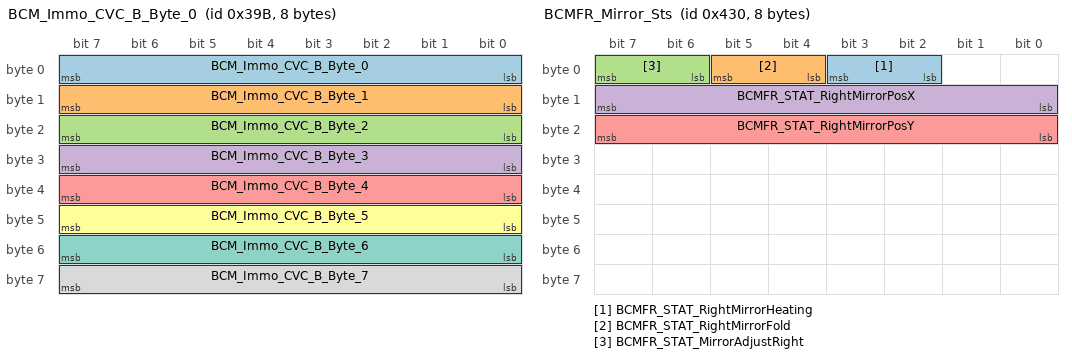
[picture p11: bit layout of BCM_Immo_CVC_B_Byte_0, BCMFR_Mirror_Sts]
BO_ 923 BCM_Immo_CVC_B_Byte_0: 8 BCM_FR
 SG_ BCM_Immo_CVC_B_Byte_0 : 7|8@0+ (1,0) [0|255] ""  CVC_B
 SG_ BCM_Immo_CVC_B_Byte_1 : 15|8@0+ (1,0) [0|255] ""  CVC_B
 SG_ BCM_Immo_CVC_B_Byte_2 : 23|8@0+ (1,0) [0|255] ""  CVC_B
 SG_ BCM_Immo_CVC_B_Byte_3 : 31|8@0+ (1,0) [0|255] ""  CVC_B
 SG_ BCM_Immo_CVC_B_Byte_4 : 39|8@0+ (1,0) [0|255] ""  CVC_B
 SG_ BCM_Immo_CVC_B_Byte_5 : 47|8@0+ (1,0) [0|255] ""  CVC_B
 SG_ BCM_Immo_CVC_B_Byte_6 : 55|8@0+ (1,0) [0|255] ""  CVC_B
 SG_ BCM_Immo_CVC_B_Byte_7 : 63|8@0+ (1,0) [0|255] ""  CVC_B

BO_ 1051 SHVU_FR_Confirm_Sts: 8 BCM_FR
 SG_ SHVU_STAT_SeatHeatingFrontR : 5|3@0+ (1,0) [0|7] ""  CVC_B
 SG_ SHVU_STAT_SeatCoolingFrontR : 13|3@0+ (1,0) [0|7] ""  CVC_B
 SG_ SHVU_STAT_FrontSeatVentSts : 15|2@0+ (1,0) [0|3] ""  CVC_B

BO_ 1072 BCMFR_Mirror_Sts: 8 BCM_FR
 SG_ BCMFR_STAT_RightMirrorHeating : 3|2@0+ (1,0) [0|3] ""  CVC_B
 SG_ BCMFR_STAT_RightMirrorFold : 5|2@0+ (1,0) [0|3] ""  CVC_B
 SG_ BCMFR_STAT_MirrorAdjustRight : 7|2@0+ (1,0) [0|3] ""  CVC_B
 SG_ BCMFR_STAT_RightMirrorPosX : 15|8@0+ (1,-15) [-15|15] "Degree"  CVC_B
 SG_ BCMFR_STAT_RightMirrorPosY : 23|8@0+ (1,-15) [-15|15] "Degree"  CVC_B

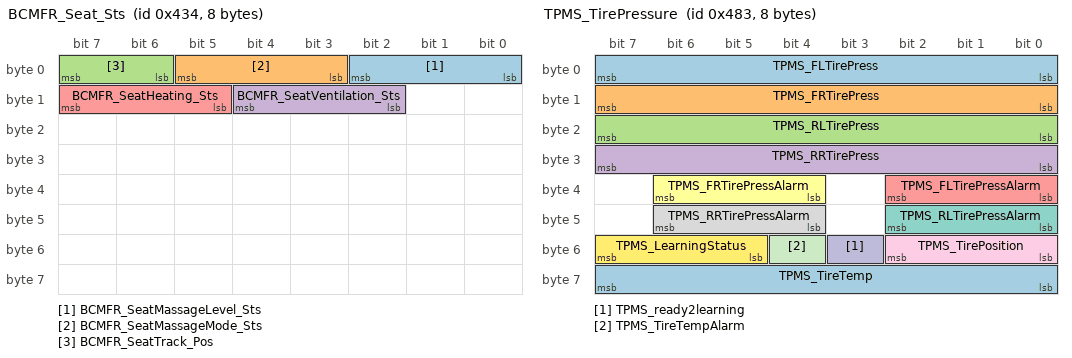
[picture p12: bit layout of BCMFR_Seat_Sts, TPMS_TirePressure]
BO_ 1076 BCMFR_Seat_Sts: 8 BCM_FR
 SG_ BCMFR_SeatMassageLevel_Sts : 2|3@0+ (1,0) [0|7] ""  CVC_B
 SG_ BCMFR_SeatMassageMode_Sts : 5|3@0+ (1,0) [0|7] ""  CVC_B
 SG_ BCMFR_SeatTrack_Pos : 7|2@0+ (1,0) [0|3] ""  CVC_B
 SG_ BCMFR_SeatVentilation_Sts : 12|3@0+ (1,0) [0|7] ""  CVC_B
 SG_ BCMFR_SeatHeating_Sts : 15|3@0+ (1,0) [0|7] ""  CVC_B

BO_ 1151 TPMS_Warning_Sts: 8 BCM_FR
 SG_ TPMS_RRTireSignalLost : 4|1@0+ (1,0) [0|1] ""  CVC_B
 SG_ TPMS_RLTireSignalLost : 5|1@0+ (1,0) [0|1] ""  CVC_B
 SG_ TPMS_FRTireSignalLost : 6|1@0+ (1,0) [0|1] ""  CVC_B
 SG_ TPMS_FLTireSignalLost : 7|1@0+ (1,0) [0|1] ""  CVC_B

BO_ 1155 TPMS_TirePressure: 8 BCM_FR
 SG_ TPMS_FLTirePress : 7|8@0+ (1.373,0) [0|350] "kPa"  CVC_B
 SG_ TPMS_FRTirePress : 15|8@0+ (1.373,0) [0|350] "kPa"  CVC_B
 SG_ TPMS_RLTirePress : 23|8@0+ (1.373,0) [0|350] "kPa"  CVC_B
 SG_ TPMS_RRTirePress : 31|8@0+ (1.373,0) [0|350] "kPa"  CVC_B
 SG_ TPMS_FLTirePressAlarm : 34|3@0+ (1,0) [0|7] ""  CVC_B
 SG_ TPMS_FRTirePressAlarm : 38|3@0+ (1,0) [0|7] ""  CVC_B
 SG_ TPMS_RLTirePressAlarm : 42|3@0+ (1,0) [0|7] ""  CVC_B
 SG_ TPMS_RRTirePressAlarm : 46|3@0+ (1,0) [0|7] ""  CVC_B
 SG_ TPMS_TirePosition : 50|3@0+ (1,0) [0|7] ""  CVC_B
 SG_ TPMS_ready2learning : 51|1@0+ (1,0) [0|1] ""  CVC_B
 SG_ TPMS_TireTempAlarm : 52|1@0+ (1,0) [0|1] ""  CVC_B
 SG_ TPMS_LearningStatus : 55|3@0+ (1,0) [0|7] ""  CVC_B
 SG_ TPMS_TireTemp : 63|8@0+ (1,-40) [-40|215] "Degree C"  CVC_B

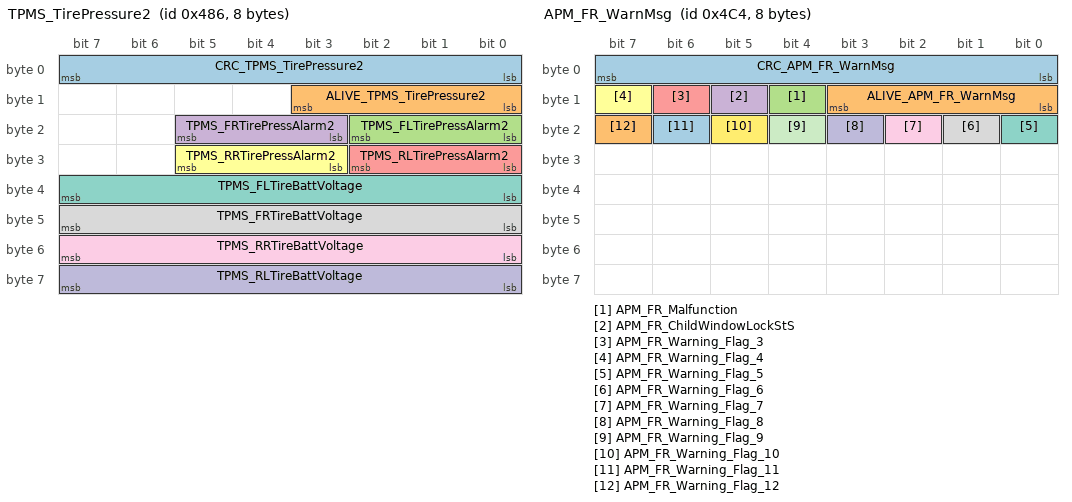
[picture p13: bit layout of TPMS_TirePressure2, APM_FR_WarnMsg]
BO_ 1158 TPMS_TirePressure2: 8 BCM_FR
 SG_ CRC_TPMS_TirePressure2 : 7|8@0+ (1,0) [0|255] ""  CVC_B
 SG_ ALIVE_TPMS_TirePressure2 : 11|4@0+ (1,0) [0|15] ""  CVC_B
 SG_ TPMS_FLTirePressAlarm2 : 18|3@0+ (1,0) [0|7] ""  CVC_B
 SG_ TPMS_FRTirePressAlarm2 : 21|3@0+ (1,0) [0|7] ""  CVC_B
 SG_ TPMS_RLTirePressAlarm2 : 26|3@0+ (1,0) [0|7] ""  CVC_B
 SG_ TPMS_RRTirePressAlarm2 : 29|3@0+ (1,0) [0|7] ""  CVC_B
 SG_ TPMS_FLTireBattVoltage : 39|8@0+ (0.1,0) [0|12] "Voltage"  CVC_B
 SG_ TPMS_FRTireBattVoltage : 47|8@0+ (0.1,0) [0|12] "Voltage"  CVC_B
 SG_ TPMS_RRTireBattVoltage : 55|8@0+ (0.1,0) [0|12] "Voltage"  CVC_B
 SG_ TPMS_RLTireBattVoltage : 63|8@0+ (0.1,0) [0|12] "Voltage"  CVC_B

BO_ 1169 BCM_FR_ALM_warning: 8 BCM_FR
 SG_ AmbLight_Error_Z1 : 0|1@0+ (1,0) [0|1] ""  CVC_B
 SG_ AmbLight_Linerror_Z1 : 1|1@0+ (1,0) [0|1] ""  CVC_B
 SG_ AmbLight_Error_Z2 : 2|1@0+ (1,0) [0|1] ""  CVC_B
 SG_ AmbLight_Linerror_Z2 : 3|1@0+ (1,0) [0|1] ""  CVC_B
 SG_ AmbLight_Error_Z6 : 4|1@0+ (1,0) [0|1] ""  CVC_B
 SG_ AmbLight_LinError_Z6 : 5|1@0+ (1,0) [0|1] ""  CVC_B
 SG_ AmbLight_Error_Z6B : 6|1@0+ (1,0) [0|1] ""  CVC_B
 SG_ AmbLight_LinError_Z6B : 7|1@0+ (1,0) [0|1] ""  CVC_B
 SG_ AmbLight_Error_Z7 : 8|1@0+ (1,0) [0|1] ""  CVC_B
 SG_ AmbLight_LinError_Z7 : 9|1@0+ (1,0) [0|1] ""  CVC_B
 SG_ AmbLight_Error_Z8 : 10|1@0+ (1,0) [0|1] ""  CVC_B
 SG_ AmbLight_LinError_Z8 : 11|1@0+ (1,0) [0|1] ""  CVC_B
 SG_ AmbLight_Error_Z7B : 12|1@0+ (1,0) [0|1] ""  CVC_B
 SG_ AmbLight_LinError_Z7B : 13|1@0+ (1,0) [0|1] ""  CVC_B
 SG_ AmbLight_Error_Z8B : 14|1@0+ (1,0) [0|1] ""  CVC_B
 SG_ AmbLight_LinError_Z8B : 15|1@0+ (1,0) [0|1] ""  CVC_B
 SG_ AmbLight_Error_Z2B : 16|1@0+ (1,0) [0|1] ""  CVC_B
 SG_ AmbLight_LinError_Z2B : 17|1@0+ (1,0) [0|1] ""  CVC_B

BO_ 1220 APM_FR_WarnMsg: 8 BCM_FR
 SG_ CRC_APM_FR_WarnMsg : 7|8@0+ (1,0) [0|255] ""  CVC_B
 SG_ ALIVE_APM_FR_WarnMsg : 11|4@0+ (1,0) [0|15] ""  CVC_B
 SG_ APM_FR_Malfunction : 12|1@0+ (1,0) [0|1] ""  CVC_B
 SG_ APM_FR_ChildWindowLockStS : 13|1@0+ (1,0) [0|1] ""  CVC_B
 SG_ APM_FR_Warning_Flag_3 : 14|1@0+ (1,0) [0|1] ""  CVC_B
 SG_ APM_FR_Warning_Flag_4 : 15|1@0+ (1,0) [0|1] ""  CVC_B
 SG_ APM_FR_Warning_Flag_5 : 16|1@0+ (1,0) [0|1] ""  CVC_B
 SG_ APM_FR_Warning_Flag_6 : 17|1@0+ (1,0) [0|1] ""  CVC_B
 SG_ APM_FR_Warning_Flag_7 : 18|1@0+ (1,0) [0|1] ""  CVC_B
 SG_ APM_FR_Warning_Flag_8 : 19|1@0+ (1,0) [0|1] ""  CVC_B
 SG_ APM_FR_Warning_Flag_9 : 20|1@0+ (1,0) [0|1] ""  CVC_B
 SG_ APM_FR_Warning_Flag_10 : 21|1@0+ (1,0) [0|1] ""  CVC_B
 SG_ APM_FR_Warning_Flag_11 : 22|1@0+ (1,0) [0|1] ""  CVC_B
 SG_ APM_FR_Warning_Flag_12 : 23|1@0+ (1,0) [0|1] ""  CVC_B

BO_ 1241 BCM_FR_WarnMsg_FR: 8 BCM_FR
 SG_ CRC_BCM_FR_WarnMsg_FR : 7|8@0+ (1,0) [0|255] ""  CVC_B
 SG_ ALIVE_BCM_FR_WarnMsg_FR : 11|4@0+ (1,0) [0|15] ""  CVC_B
 SG_ BCM_FR_NoValidKey_1 : 12|1@0+ (1,0) [0|1] ""  CVC_B
 SG_ BCM_FR_NoValidKey_2 : 15|1@0+ (1,0) [0|1] ""  CVC_B
 SG_ BCM_FR_TurnOffPosLightRemindr : 17|1@0+ (1,0) [0|1] ""  CVC_B
 SG_ BCM_FR_KeyFob_LowBattery : 18|1@0+ (1,0) [0|1] ""  CVC_B
 SG_ BCM_FR_StopLightDefect : 19|1@0+ (1,0) [0|1] ""  CVC_B
 SG_ BCM_FR_LowBeamDefect : 20|1@0+ (1,0) [0|1] ""  CVC_B
 SG_ BCM_FR_HighBeamDefect : 21|1@0+ (1,0) [0|1] ""  CVC_B
 SG_ BCM_FR_PositionLightDefect : 22|1@0+ (1,0) [0|1] ""  CVC_B
 SG_ BCM_FR_CHMLS_Defect : 23|1@0+ (1,0) [0|1] ""  CVC_B
 SG_ BCM_FR_LicencePlateLight_Defect : 24|1@0+ (1,0) [0|1] ""  CVC_B
 SG_ BCM_FR_FrontFog_Defect : 25|1@0+ (1,0) [0|1] ""  CVC_B
 SG_ BCM_FR_RearFog_Defect : 26|1@0+ (1,0) [0|1] ""  CVC_B
 SG_ BCM_FR_ReverseLightDefect : 27|1@0+ (1,0) [0|1] ""  CVC_B
 SG_ BCM_FR_ForgetKeyFOBInCar : 30|1@0+ (1,0) [0|1] ""  CVC_B
 SG_ BCM_FR_TurnIndicatorDefect : 32|1@0+ (1,0) [0|1] ""  CVC_B
 SG_ BCM_FR_dTPMS_Malfunc : 33|1@0+ (1,0) [0|1] ""  CVC_B
 SG_ BCM_FR_dTPMS_Malfunc_LostSensor : 34|1@0+ (1,0) [0|1] ""  CVC_B
 SG_ BCM_FR_dTPMS_LowPressure : 35|1@0+ (1,0) [0|1] ""  CVC_B
 SG_ BCM_FR_dTPMS_RapidLeak : 36|1@0+ (1,0) [0|1] ""  CVC_B
 SG_ BCM_FR_dTPMS_HighTemperature : 37|1@0+ (1,0) [0|1] ""  CVC_B
 SG_ BCM_FR_dTPMS_HighPressure : 38|1@0+ (1,0) [0|1] ""  CVC_B
 SG_ BCM_FR_dTPMS_LowBattery : 39|1@0+ (1,0) [0|1] ""  CVC_B
 SG_ BCM_Keyfob_Leftcar : 40|1@0+ (1,0) [0|1] ""  CVC_B
 SG_ BCM_FR_IDB_Brakelight_Malfunctio : 41|1@0+ (1,0) [0|1] ""  CVC_B
 SG_ BCM_FR_CVC_Brakelight_Malfunctio : 42|1@0+ (1,0) [0|1] ""  CVC_B
 SG_ BCM_FR_Turnlight_Malfunction : 43|1@0+ (1,0) [0|1] ""  CVC_B
 SG_ BCM_FR_Highbeam_Malfunction : 44|1@0+ (1,0) [0|1] ""  CVC_B
 SG_ BCM_FR_LowBeam_Malfunction : 45|1@0+ (1,0) [0|1] ""  CVC_B
 SG_ BCM_FR_Malfunction : 46|1@0+ (1,0) [0|1] ""  CVC_B
 SG_ BCM_FR_BCM_Malfunction : 47|1@0+ (1,0) [0|1] ""  CVC_B
 SG_ BCM_FR_SCM_Malfunction : 48|1@0+ (1,0) [0|1] ""  CVC_B
 SG_ BCM_FR_CrashSignalDefect : 49|1@0+ (1,0) [0|1] ""  CVC_B
 SG_ BCM_FR_FrontWiperDefect : 51|1@0+ (1,0) [0|1] ""  CVC_B
 SG_ BCM_FR_Front_RightDoorLockDefect : 54|1@0+ (1,0) [0|1] ""  CVC_B
 SG_ BCM_FR_LossCommGearStatus : 58|1@0+ (1,0) [0|1] ""  CVC_B
 SG_ BCM_FR_RLT_Malfunction : 60|1@0+ (1,0) [0|1] ""  CVC_B
 SG_ BCM_FR_BCM_POWER_Malfunction : 61|1@0+ (1,0) [0|1] ""  CVC_B
 SG_ BCM_FR_RRDoorLockDefect : 63|1@0+ (1,0) [0|1] ""  CVC_B

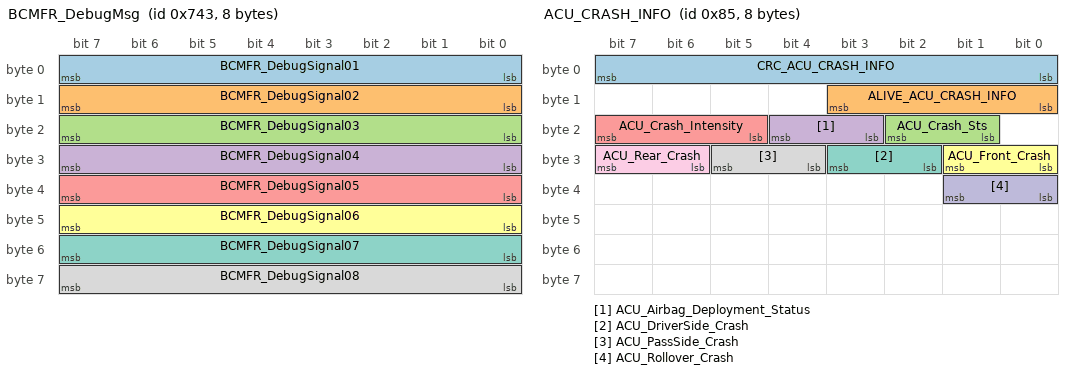
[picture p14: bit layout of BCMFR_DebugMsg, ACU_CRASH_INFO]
BO_ 1859 BCMFR_DebugMsg: 8 BCM_FR
 SG_ BCMFR_DebugSignal01 : 7|8@0+ (1,0) [0|255] ""  CVC_B
 SG_ BCMFR_DebugSignal02 : 15|8@0+ (1,0) [0|255] ""  CVC_B
 SG_ BCMFR_DebugSignal03 : 23|8@0+ (1,0) [0|255] ""  CVC_B
 SG_ BCMFR_DebugSignal04 : 31|8@0+ (1,0) [0|255] ""  CVC_B
 SG_ BCMFR_DebugSignal05 : 39|8@0+ (1,0) [0|255] ""  CVC_B
 SG_ BCMFR_DebugSignal06 : 47|8@0+ (1,0) [0|255] ""  CVC_B
 SG_ BCMFR_DebugSignal07 : 55|8@0+ (1,0) [0|255] ""  CVC_B
 SG_ BCMFR_DebugSignal08 : 63|8@0+ (1,0) [0|255] ""  CVC_B

BO_ 1972 BCM_FR_Synchronization_Req: 8 BCM_FR
 SG_ BCMFR_Req_RandomData : 7|24@0+ (1,0) [0|16777215] ""  CVC_B
 SG_ BCMFR_Req_MAC : 31|40@0+ (1,0) [0|1099511627775] ""  CVC_B

BO_ 133 ACU_CRASH_INFO: 8 CVC_B
 SG_ CRC_ACU_CRASH_INFO : 7|8@0+ (1,0) [0|255] ""  BCM_FL,BCM_FR,BCM_R
 SG_ ALIVE_ACU_CRASH_INFO : 11|4@0+ (1,0) [0|15] ""  BCM_FL,BCM_FR,BCM_R
 SG_ ACU_Crash_Sts : 18|2@0+ (1,0) [0|3] ""  BCM_FL,BCM_FR,BCM_R
 SG_ ACU_Airbag_Deployment_Status : 20|2@0+ (1,0) [0|3] ""  BCM_FL,BCM_FR,BCM_R
 SG_ ACU_Crash_Intensity : 23|3@0+ (1,0) [0|7] ""  BCM_FL,BCM_FR,BCM_R
 SG_ ACU_Front_Crash : 25|2@0+ (1,0) [0|3] ""  BCM_FL,BCM_FR,BCM_R
 SG_ ACU_DriverSide_Crash : 27|2@0+ (1,0) [0|3] ""  BCM_FL,BCM_FR,BCM_R
 SG_ ACU_PassSide_Crash : 29|2@0+ (1,0) [0|3] ""  BCM_FL,BCM_FR,BCM_R
 SG_ ACU_Rear_Crash : 31|2@0+ (1,0) [0|3] ""  BCM_FL,BCM_FR,BCM_R
 SG_ ACU_Rollover_Crash : 33|2@0+ (1,0) [0|3] ""  BCM_FL,BCM_FR,BCM_R

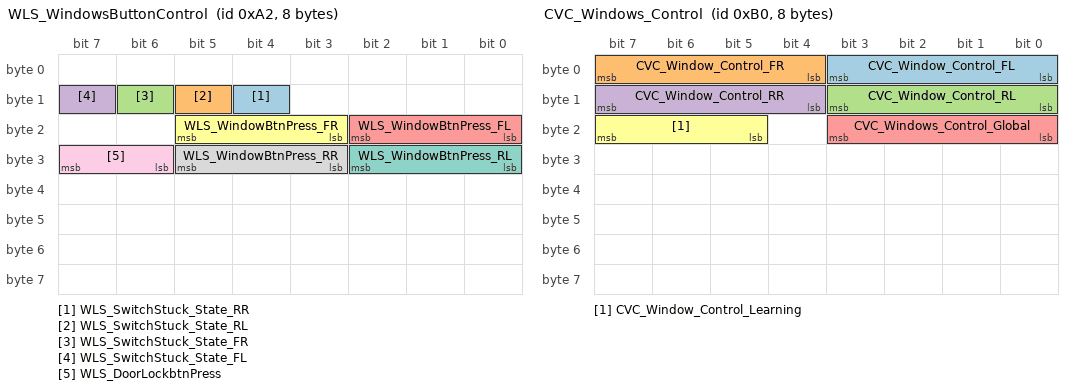
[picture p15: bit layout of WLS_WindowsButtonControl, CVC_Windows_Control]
BO_ 162 WLS_WindowsButtonControl: 8 CVC_B
 SG_ WLS_SwitchStuck_State_RR : 12|1@0+ (1,0) [0|1] ""  DUMMY_ECU
 SG_ WLS_SwitchStuck_State_RL : 13|1@0+ (1,0) [0|1] ""  DUMMY_ECU
 SG_ WLS_SwitchStuck_State_FR : 14|1@0+ (1,0) [0|1] ""  DUMMY_ECU
 SG_ WLS_SwitchStuck_State_FL : 15|1@0+ (1,0) [0|1] ""  DUMMY_ECU
 SG_ WLS_WindowBtnPress_FL : 18|3@0+ (1,0) [0|7] ""  DUMMY_ECU
 SG_ WLS_WindowBtnPress_FR : 21|3@0+ (1,0) [0|7] ""  DUMMY_ECU
 SG_ WLS_WindowBtnPress_RL : 26|3@0+ (1,0) [0|7] ""  DUMMY_ECU
 SG_ WLS_WindowBtnPress_RR : 29|3@0+ (1,0) [0|7] ""  DUMMY_ECU
 SG_ WLS_DoorLockbtnPress : 31|2@0+ (1,0) [0|3] ""  DUMMY_ECU

BO_ 176 CVC_Windows_Control: 8 CVC_B
 SG_ CVC_Window_Control_FL : 3|4@0+ (1,0) [0|15] ""  BCM_R
 SG_ CVC_Window_Control_FR : 7|4@0+ (1,0) [0|15] ""  BCM_FR
 SG_ CVC_Window_Control_RL : 11|4@0+ (1,0) [0|15] ""  BCM_R
 SG_ CVC_Window_Control_RR : 15|4@0+ (1,0) [0|15] ""  BCM_FR
 SG_ CVC_Windows_Control_Global : 19|4@0+ (1,0) [0|15] ""  BCM_FL,BCM_FR
 SG_ CVC_Window_Control_Learning : 23|3@0+ (1,0) [0|6] ""  BCM_FL,BCM_FR

BO_ 193 CVC_FrontHVAC_Control: 12 CVC_B
 SG_ Ionizer_Set : 13|2@0+ (1,0) [0|3] ""  BCM_FL,BCM_FR,BCM_R
 SG_ RecirculationFlap_Set : 23|8@0+ (1,0) [0|100] "%"  BCM_FL,BCM_FR,BCM_R
 SG_ AirDistributionMode_Set : 31|8@0+ (1,0) [0|100] "%"  BCM_FL,BCM_FR,BCM_R
 SG_ RHTempFlap_Set : 39|8@0+ (1,0) [0|100] "%"  BCM_FL,BCM_FR,BCM_R
 SG_ LHTempFlap_Set : 47|8@0+ (1,0) [0|100] "%"  BCM_FL,BCM_FR,BCM_R
 SG_ FrontBlowerRelay_Set : 55|2@0+ (1,0) [0|3] ""  BCM_FL,BCM_FR,BCM_R
 SG_ CVC_EvapTempSet : 63|8@0+ (0.1,-5) [-5|20.5] "Degree C"  BCM_FL,BCM_FR,BCM_R
 SG_ AirDistributionModeLH_Set : 71|8@0+ (1,0) [0|100] "%"  BCM_FR
 SG_ AirDistributionModeRH_Set : 79|8@0+ (1,0) [0|100] "%"  BCM_R
 SG_ BypassFlap_Set : 87|8@0+ (1,0) [0|100] "%"  BCM_R
 SG_ AirDistributionModeRear_Set : 95|8@0+ (1,0) [0|100] "%"  BCM_R

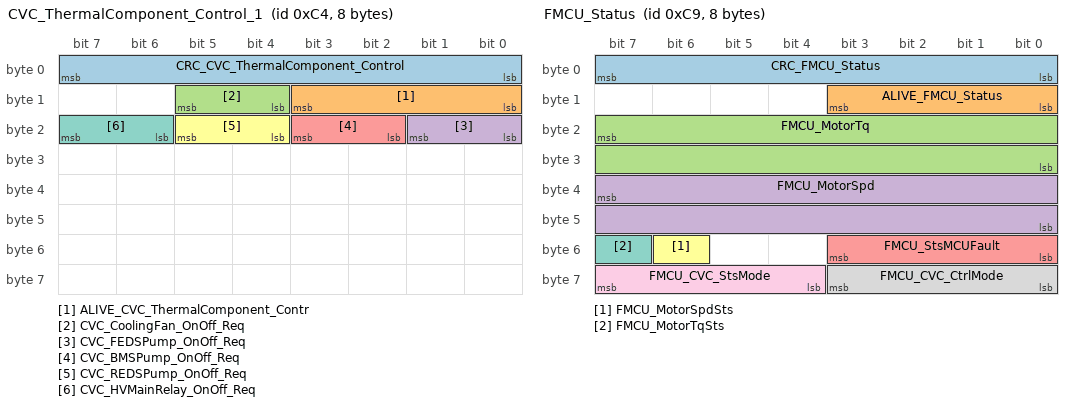
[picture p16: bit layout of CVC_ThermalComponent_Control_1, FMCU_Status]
BO_ 196 CVC_ThermalComponent_Control_1: 8 CVC_B
 SG_ CRC_CVC_ThermalComponent_Control : 7|8@0+ (1,0) [0|255] ""  BCM_FL,BCM_FR,BCM_R
 SG_ ALIVE_CVC_ThermalComponent_Contr : 11|4@0+ (1,0) [0|15] ""  BCM_FL,BCM_FR,BCM_R
 SG_ CVC_CoolingFan_OnOff_Req : 13|2@0+ (1,0) [0|3] ""  BCM_FL,BCM_FR,BCM_R
 SG_ CVC_FEDSPump_OnOff_Req : 17|2@0+ (1,0) [0|3] ""  BCM_FL,BCM_FR,BCM_R
 SG_ CVC_BMSPump_OnOff_Req : 19|2@0+ (1,0) [0|3] ""  BCM_FL,BCM_FR,BCM_R
 SG_ CVC_REDSPump_OnOff_Req : 21|2@0+ (1,0) [0|3] ""  BCM_FL,BCM_FR,BCM_R
 SG_ CVC_HVMainRelay_OnOff_Req : 23|2@0+ (1,0) [0|3] ""  BCM_FL,BCM_FR,BCM_R

BO_ 197 CVC_ThermalComponent_Control_2: 16 CVC_B
 SG_ CRC_CVC_ThermalComponent_Co_0000 : 7|8@0+ (1,0) [0|255] ""  BCM_FL,BCM_FR,BCM_R
 SG_ ALIVE_CVC_ThermalComponent__0000 : 11|4@0+ (1,0) [0|15] ""  BCM_FL,BCM_FR,BCM_R
 SG_ CVC_BatteryChillerSOV_Req : 13|2@0+ (1,0) [0|3] ""  BCM_FL,BCM_FR,BCM_R
 SG_ CVC_EvapSOV_Req : 15|2@0+ (1,0) [0|3] ""  BCM_FL,BCM_FR,BCM_R
 SG_ CVC_CoolingFan_PWM_Req : 23|8@0+ (1,0) [0|100] "%"  BCM_FL,BCM_FR,BCM_R
 SG_ CVC_FEDSPump_PWM_Req : 31|8@0+ (1,0) [0|100] "%"  BCM_FL,BCM_FR,BCM_R
 SG_ CVC_BMSPump_PWM_Req : 39|8@0+ (1,0) [0|100] "%"  BCM_FL,BCM_FR,BCM_R
 SG_ CVC_REDSPump_PWM_Req : 47|8@0+ (1,0) [0|100] "%"  BCM_FL,BCM_FR,BCM_R
 SG_ CVC_WaterPump4_PWM_Req : 55|8@0+ (1,0) [0|100] "%"  BCM_FL,BCM_FR,BCM_R
 SG_ CVC_EvapSOV2_Req : 57|2@0+ (1,0) [0|3] ""  BCM_R
 SG_ RearDuctFlap_Set : 71|7@0+ (1,0) [0|100] "%"  BCM_R
 SG_ CVC_RearBlwSpeed_Req : 79|8@0+ (20,0) [0|5100] "RPM"  BCM_R
 SG_ CVC_RearBlwRamp_Req : 63|4@0+ (100,100) [100|1600] "RPM/s"  BCM_R
 SG_ CVC_RearBlwSafetySpeed_Req : 87|8@0+ (20,0) [0|5100] "RPM"  BCM_R
 SG_ CVC_RearBlwCodeVehicle_Req : 64|1@0+ (1,0) [0|1] ""  BCM_R
 SG_ CVC_RearAPTC_HeatingRequest : 95|8@0+ (1,0) [0|100] "%"  BCM_R
 SG_ CVC_RearAPTC_OnOffRequest : 59|2@0+ (1,0) [0|3] ""  BCM_R
 SG_ CVC_RearEXV_Set_Req : 103|10@0+ (1,0) [0|576] ""  BCM_R
 SG_ CVC_RearEXV_Move_Enbl_Req : 109|1@0+ (1,0) [0|1] ""  BCM_R
 SG_ CVC_RearEXV_Init_Req : 108|3@0+ (1,0) [0|7] ""  BCM_R
 SG_ CVC_RearEvapTempSet : 119|8@0+ (0.1,-5) [-5|20.5] "degC"  BCM_FR

BO_ 201 FMCU_Status: 8 CVC_B
 SG_ CRC_FMCU_Status : 7|8@0+ (1,0) [0|255] ""  BCM_FL,BCM_FR,BCM_R
 SG_ ALIVE_FMCU_Status : 11|4@0+ (1,0) [0|15] ""  BCM_FL,BCM_FR,BCM_R
 SG_ FMCU_MotorTq : 23|16@0+ (0.1,-400) [-400|400] "Nm"  BCM_FL,BCM_FR,BCM_R
 SG_ FMCU_MotorSpd : 39|16@0+ (1,-20000) [-20000|45531] "rpm"  BCM_FL,BCM_FR,BCM_R
 SG_ FMCU_StsMCUFault : 51|4@0+ (1,0) [0|15] ""  BCM_FL,BCM_FR,BCM_R
 SG_ FMCU_MotorSpdSts : 54|1@0+ (1,0) [0|1] ""  BCM_FL,BCM_FR,BCM_R
 SG_ FMCU_MotorTqSts : 55|1@0+ (1,0) [0|1] ""  BCM_FL,BCM_FR,BCM_R
 SG_ FMCU_CVC_CtrlMode : 59|4@0+ (1,0) [0|15] ""  BCM_FL,BCM_FR,BCM_R
 SG_ FMCU_CVC_StsMode : 63|4@0+ (1,0) [0|15] ""  BCM_FL,BCM_FR,BCM_R

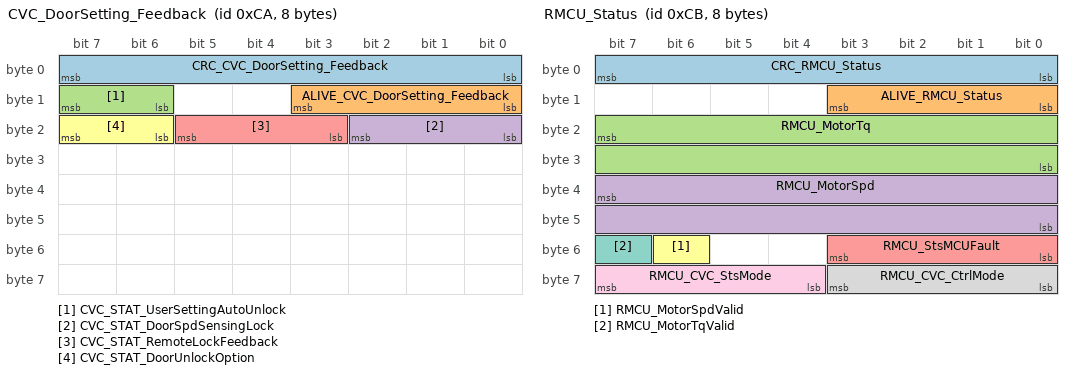
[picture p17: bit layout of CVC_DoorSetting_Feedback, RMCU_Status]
BO_ 202 CVC_DoorSetting_Feedback: 8 CVC_B
 SG_ CRC_CVC_DoorSetting_Feedback : 7|8@0+ (1,0) [0|255] ""  BCM_FL,BCM_FR,BCM_R
 SG_ ALIVE_CVC_DoorSetting_Feedback : 11|4@0+ (1,0) [0|15] ""  BCM_FL,BCM_FR,BCM_R
 SG_ CVC_STAT_UserSettingAutoUnlock : 15|2@0+ (1,0) [0|3] ""  BCM_FL,BCM_FR,BCM_R
 SG_ CVC_STAT_DoorSpdSensingLock : 18|3@0+ (1,0) [0|6] ""  BCM_FL,BCM_FR,BCM_R
 SG_ CVC_STAT_RemoteLockFeedback : 21|3@0+ (1,0) [0|4] ""  BCM_FL,BCM_FR,BCM_R
 SG_ CVC_STAT_DoorUnlockOption : 23|2@0+ (1,0) [0|3] ""  BCM_FL,BCM_FR,BCM_R

BO_ 203 RMCU_Status: 8 CVC_B
 SG_ CRC_RMCU_Status : 7|8@0+ (1,0) [0|255] ""  BCM_FL,BCM_FR,BCM_R
 SG_ ALIVE_RMCU_Status : 11|4@0+ (1,0) [0|15] ""  BCM_FL,BCM_FR,BCM_R
 SG_ RMCU_MotorTq : 23|16@0+ (0.1,-400) [-400|400] "Nm"  BCM_FL,BCM_FR,BCM_R
 SG_ RMCU_MotorSpd : 39|16@0+ (1,-20000) [-20000|45531] "rpm"  BCM_FL,BCM_FR,BCM_R
 SG_ RMCU_StsMCUFault : 51|4@0+ (1,0) [0|15] ""  BCM_FL,BCM_FR,BCM_R
 SG_ RMCU_MotorSpdValid : 54|1@0+ (1,0) [0|1] ""  BCM_FL,BCM_FR,BCM_R
 SG_ RMCU_MotorTqValid : 55|1@0+ (1,0) [0|1] ""  BCM_FL,BCM_FR,BCM_R
 SG_ RMCU_CVC_CtrlMode : 59|4@0+ (1,0) [0|15] ""  BCM_FL,BCM_FR,BCM_R
 SG_ RMCU_CVC_StsMode : 63|4@0+ (1,0) [0|15] ""  BCM_FL,BCM_FR,BCM_R

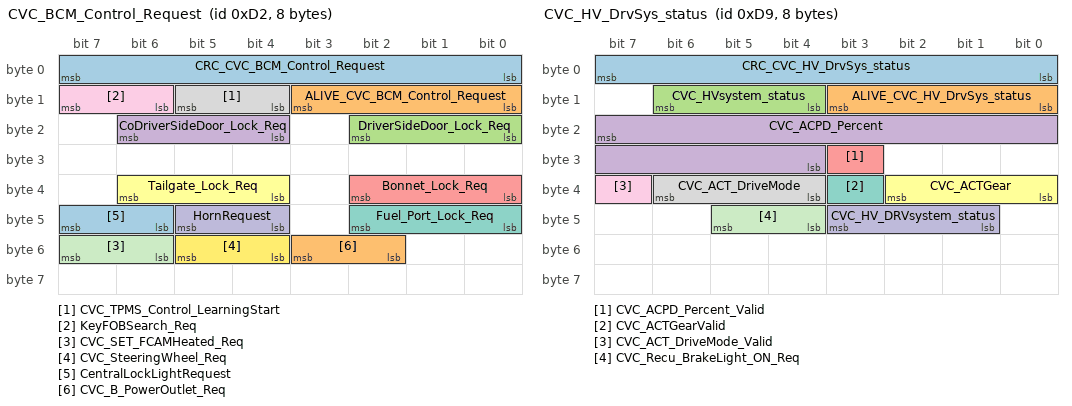
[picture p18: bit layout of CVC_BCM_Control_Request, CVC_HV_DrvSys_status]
BO_ 210 CVC_BCM_Control_Request: 8 CVC_B
 SG_ CRC_CVC_BCM_Control_Request : 7|8@0+ (1,0) [0|255] ""  BCM_FL,BCM_FR,BCM_R
 SG_ ALIVE_CVC_BCM_Control_Request : 11|4@0+ (1,0) [0|15] ""  BCM_FL,BCM_FR,BCM_R
 SG_ DriverSideDoor_Lock_Req : 18|3@0+ (1,0) [0|5] ""  BCM_FL,BCM_FR,BCM_R
 SG_ CoDriverSideDoor_Lock_Req : 22|3@0+ (1,0) [0|5] ""  BCM_FL,BCM_FR,BCM_R
 SG_ Bonnet_Lock_Req : 34|3@0+ (1,0) [0|4] ""  BCM_FL,BCM_FR,BCM_R
 SG_ Tailgate_Lock_Req : 38|3@0+ (1,0) [0|4] ""  BCM_FL,BCM_FR,BCM_R
 SG_ Fuel_Port_Lock_Req : 42|3@0+ (1,0) [0|4] ""  BCM_FL,BCM_FR,BCM_R
 SG_ CVC_TPMS_Control_LearningStart : 13|2@0+ (1,0) [0|3] ""  BCM_FR
 SG_ KeyFOBSearch_Req : 15|2@0+ (1,0) [0|3] ""  BCM_FR
 SG_ HornRequest : 45|2@0+ (1,0) [0|2] ""  BCM_FL
 SG_ CVC_SET_FCAMHeated_Req : 55|2@0+ (1,0) [0|3] ""  BCM_FL
 SG_ CVC_SteeringWheel_Req : 53|2@0+ (1,0) [0|3] ""  BCM_FL
 SG_ CentralLockLightRequest : 47|2@0+ (1,0) [0|3] ""  BCM_FR
 SG_ CVC_B_PowerOutlet_Req : 51|2@0+ (1,0) [0|3] ""  BCM_FL

BO_ 217 CVC_HV_DrvSys_status: 8 CVC_B
 SG_ CRC_CVC_HV_DrvSys_status : 7|8@0+ (1,0) [0|255] ""  BCM_FL,BCM_FR,DKCU,BCM_R
 SG_ ALIVE_CVC_HV_DrvSys_status : 11|4@0+ (1,0) [0|15] ""  BCM_FL,BCM_FR,DKCU,BCM_R
 SG_ CVC_HVsystem_status : 14|3@0+ (1,0) [0|7] ""  BCM_FL,BCM_FR,DKCU,BCM_R
 SG_ CVC_ACPD_Percent : 23|12@0+ (0.0625,0) [0|100] "%"  BCM_FL,BCM_FR,DKCU,BCM_R
 SG_ CVC_ACPD_Percent_Valid : 27|1@0+ (1,0) [0|1] ""  BCM_FL,BCM_FR,DKCU,BCM_R
 SG_ CVC_ACTGear : 34|3@0+ (1,0) [0|7] ""  BCM_FL,BCM_FR,DKCU,BCM_R
 SG_ CVC_ACTGearValid : 35|1@0+ (1,0) [0|1] ""  BCM_FL,BCM_FR,DKCU,BCM_R
 SG_ CVC_ACT_DriveMode : 38|3@0+ (1,0) [0|7] ""  BCM_FL,BCM_FR,DKCU,BCM_R
 SG_ CVC_ACT_DriveMode_Valid : 39|1@0+ (1,0) [0|1] ""  BCM_FL,BCM_FR,DKCU,BCM_R
 SG_ CVC_HV_DRVsystem_status : 43|3@0+ (1,0) [0|7] ""  BCM_FL,BCM_FR,DKCU,BCM_R
 SG_ CVC_Recu_BrakeLight_ON_Req : 45|2@0+ (1,0) [0|3] ""  BCM_FL,BCM_FR,DKCU,BCM_R

BO_ 256 CVC_B_Vehicle_Info: 8 CVC_B
 SG_ CRC_CVC_B_Vehicle_Info : 7|8@0+ (1,0) [0|255] ""  BCM_FL,BCM_FR,BCM_R
 SG_ ALIVE_CVC_B_Vehicle_Info : 11|4@0+ (1,0) [0|15] ""  BCM_FL,BCM_FR,BCM_R
 SG_ CVC_B_UserProfileId : 23|4@0+ (1,0) [0|15] ""  BCM_FL,BCM_FR,BCM_R
 SG_ CVC_B_Connectivity_Status : 47|3@0+ (1,0) [0|7] ""  BCM_FL,BCM_FR,BCM_R

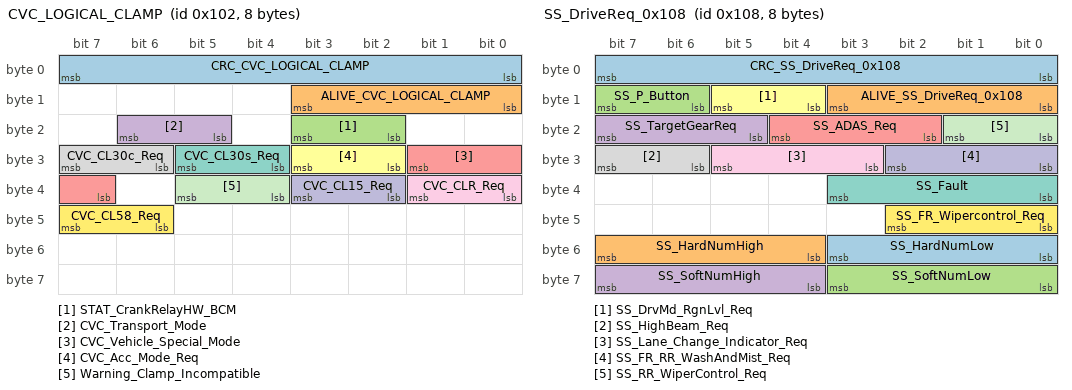
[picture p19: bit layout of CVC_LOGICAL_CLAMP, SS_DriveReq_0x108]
BO_ 258 CVC_LOGICAL_CLAMP: 8 CVC_B
 SG_ CRC_CVC_LOGICAL_CLAMP : 7|8@0+ (1,0) [0|255] ""  BCM_FL,BCM_FR,BCM_R
 SG_ ALIVE_CVC_LOGICAL_CLAMP : 11|4@0+ (1,0) [0|15] ""  BCM_FL,BCM_FR,BCM_R
 SG_ STAT_CrankRelayHW_BCM : 19|2@0+ (1,0) [0|3] ""  BCM_FL,BCM_FR,BCM_R
 SG_ CVC_Transport_Mode : 22|2@0+ (1,0) [0|3] ""  BCM_FL,BCM_FR,BCM_R
 SG_ CVC_Vehicle_Special_Mode : 25|3@0+ (1,0) [0|7] ""  BCM_FL,BCM_FR,BCM_R
 SG_ CVC_Acc_Mode_Req : 27|2@0+ (1,0) [0|3] ""  BCM_FL,BCM_FR,BCM_R
 SG_ CVC_CL30s_Req : 29|2@0+ (1,0) [0|3] ""  BCM_FL,BCM_FR,BCM_R
 SG_ CVC_CL30c_Req : 31|2@0+ (1,0) [0|3] ""  BCM_FL,BCM_FR,BCM_R
 SG_ CVC_CLR_Req : 33|2@0+ (1,0) [0|3] ""  BCM_FL,BCM_FR,BCM_R
 SG_ CVC_CL15_Req : 35|2@0+ (1,0) [0|3] ""  BCM_FL,BCM_FR,BCM_R
 SG_ Warning_Clamp_Incompatible : 37|2@0+ (1,0) [0|3] ""  BCM_FL,BCM_FR,BCM_R
 SG_ CVC_CL58_Req : 47|2@0+ (1,0) [0|3] ""  BCM_FL,BCM_FR,BCM_R

BO_ 264 SS_DriveReq_0x108: 8 CVC_B
 SG_ CRC_SS_DriveReq_0x108 : 7|8@0+ (1,0) [0|255] ""  BCM_FL,BCM_FR,BCM_R
 SG_ ALIVE_SS_DriveReq_0x108 : 11|4@0+ (1,0) [0|15] ""  BCM_FL,BCM_FR,BCM_R
 SG_ SS_P_Button : 15|2@0+ (1,0) [0|3] ""  BCM_FL,BCM_FR,BCM_R
 SG_ SS_TargetGearReq : 23|3@0+ (1,0) [0|7] ""  BCM_FL,BCM_FR,BCM_R
 SG_ SS_ADAS_Req : 20|3@0+ (1,0) [0|7] ""  BCM_FL,BCM_FR,BCM_R
 SG_ SS_DrvMd_RgnLvl_Req : 13|2@0+ (1,0) [0|3] ""  BCM_FL,BCM_FR,BCM_R
 SG_ SS_Fault : 35|4@0+ (1,0) [0|15] ""  BCM_FL,BCM_FR,BCM_R
 SG_ SS_HighBeam_Req : 31|2@0+ (1,0) [0|3] ""  BCM_FL,BCM_FR,BCM_R
 SG_ SS_Lane_Change_Indicator_Req : 29|3@0+ (1,0) [0|7] ""  BCM_FL,BCM_FR,BCM_R
 SG_ SS_FR_RR_WashAndMist_Req : 26|3@0+ (1,0) [0|7] ""  BCM_FL,BCM_FR,BCM_R
 SG_ SS_RR_WiperControl_Req : 17|2@0+ (1,0) [0|3] ""  BCM_FL,BCM_FR,BCM_R
 SG_ SS_FR_Wipercontrol_Req : 42|3@0+ (1,0) [0|7] ""  BCM_FL,BCM_FR,BCM_R
 SG_ SS_HardNumLow : 51|4@0+ (1,0) [0|15] ""  BCM_FL,BCM_FR,BCM_R
 SG_ SS_HardNumHigh : 55|4@0+ (1,0) [0|15] ""  BCM_FL,BCM_FR,BCM_R
 SG_ SS_SoftNumLow : 59|4@0+ (1,0) [0|15] ""  BCM_FL,BCM_FR,BCM_R
 SG_ SS_SoftNumHigh : 63|4@0+ (1,0) [0|15] ""  BCM_FL,BCM_FR,BCM_R

CM_ SG_ 169 BCMFL_AmbientTemp "Ambient temperature";
CM_ SG_ 169 BCMFL_CabinHeat_TempSensor "the Interior Temperature with Celcius Degree";
CM_ SG_ 169 BCMFL_AmbientTempSts "Environmental temperature sensor input value";
CM_ SG_ 169 BCMFL_CoolantTemp_EDS_In_Sts "Front EDS Inlet Coolant Temperature Sensor Status";
CM_ SG_ 169 BCMFL_CoolantTemp_EDS_Out_Sts "Front EDS Outlet Coolant Temperature";
CM_ SG_ 169 BCMFL_CoolantTemp_LTR_Out_Sts "LTR Outlet Coolant Temperature Sensor Status";
CM_ SG_ 169 BCMFL_ACLowSideTemperatureSts "Temperature status on the low-pressure side of the air conditioner";
CM_ SG_ 169 BCMFL_ACLowSidePressureSts "Pressure state on the low-pressure side of the air conditioner";
CM_ SG_ 169 BCMFL_ACHighSideTemperatureSts "Temperature status on the high-pressure side of the air conditioner";
CM_ SG_ 169 BCMFL_ACHighSidePressureSts "Pressure status on the high-pressure side of the air conditioner";
CM_ SG_ 169 BCMFL_CoolantTemp_HtrCore_In_Sts "Heater Core Inlet Coolant Temperature Sensor Status";
CM_ SG_ 169 BCMFL_Refrigerant_Temp_Sensor_St "Refrigerant temperature sensor status";
CM_ SG_ 169 BCMFL_PT_Sensor1_Pressure_Sts "Pressure state of pressure and temperature sensor [1]";
CM_ SG_ 169 BCMFL_PT_Sensor2_Pressure_Sts "Pressure state of pressure and temperature sensor [2]";
CM_ SG_ 170 CRC_BCMFL_DoorStatus "Checksum";
CM_ SG_ 170 ALIVE_BCMFL_DoorStatus "Alive counter";
CM_ SG_ 170 BonnetLockStatus "Engine hood locked state";
CM_ SG_ 170 DriverDoor_Lock_Sts "Left front door locked status";
CM_ SG_ 170 DriverDoor_Ajar_Sts "Left front door not tightly closed";
CM_ SG_ 170 BonnetAjarStatus "The engine hood is not tightly closed";
CM_ SG_ 170 RLDoor_Lock_Sts "Right front door locked status";
CM_ SG_ 170 RLDoor_Ajar_Sts "Right front door not tightly closed";
CM_ SG_ 178 MechanicalLockReq "Feedback mechanical lock/unlock method";
CM_ SG_ 178 Driver_PassiveEntryButton_Sts "Passive Entry Button status request by user";
CM_ SG_ 178 FootKickOperation_Request "Feedback footkick event to CVC";
CM_ SG_ 178 TailgateExtButton_Request "Send tailgate Exterior Switch press event to CVC";
CM_ SG_ 180 BCMFL_WindowsFL_AntiPinch_Warn "Feedback anti-pinch status to CVC for HMI warning";
CM_ SG_ 180 BCMFL_WindowFL_Learning_Sts "Feedback learning status to CVC";
CM_ SG_ 180 BCMFL_WindowFL_Suppression_Warn "Feedback the lifter suppression status";
CM_ SG_ 180 BCMFL_WindowFL_LockActive "Feedback current window lock status";
CM_ SG_ 180 BCMFL_WindowFL_ThermalProtect "Feedback thermal protection status";
CM_ SG_ 180 BCMFL_WindowFL_Error "Feedback front left window error position to CVC for corresponding warning on HMI";
CM_ SG_ 180 BCMFL_WindowsRL_AntiPinch_Warn "Feedback anti-pinch status to CVC for HMI warning";
CM_ SG_ 180 BCMFL_WindowRL_LockActive "Feedback current window lock status";
CM_ SG_ 180 BCMFL_WindowRL_Error "Feedback rear left window error position to CVC for corresponding warning on HMI";
CM_ SG_ 180 BCMFL_WindowRL_Learning_Sts "Feedback learning status to CVC";
CM_ SG_ 180 BCMFL_WindowRL_Suppression_Warn "Feedback the lifter suppression status";
CM_ SG_ 180 BCMFL_WindowRL_ThermalProtect "Feedback thermal protection status";
CM_ SG_ 180 Window_Position_FL "Feedback the current front left window position to CVC";
CM_ SG_ 180 Window_Position_RL "Feedback the current rear left window position to CVC";
CM_ SG_ 180 BCMFL_WindowBtnPress_RL "Rear Left Window Button status";
CM_ SG_ 180 BCMFL_WindowBtnPress_FL "Front Left Window Button status";
CM_ SG_ 198 BCMFL_CoolantLevel "actual level of coolant";
CM_ SG_ 198 BCMFL_CoolingFan_Status "Cooling Fan ON/OFF status";
CM_ SG_ 198 BCMFL_FEDSPump_Status "Front EDS Pump Actual Status";
CM_ SG_ 198 BCMFL_BMSPump_Status "BMS Pump Actual Status";
CM_ SG_ 198 BCMFL_REDSPump_Status "Rear EDS Pump Actual Status";
CM_ SG_ 198 BCMFL_HVMainRelay_Status "HV Main relay ON/OFF status";
CM_ SG_ 198 BCMFL_ACLowSidePressure "Refrigerant - L-PT  (Inlet)sensor pressor value";
CM_ SG_ 198 BCMFL_ACHighSidePressure "Refrigerant - H-PT (Outlet)sensor pressor value";
CM_ SG_ 198 BCMFL_CoolantTemp_LTR_Out "LTR Outlet Coolant Temperature";
CM_ SG_ 198 BCMFL_CoolantTemp_EDS_In "Front EDS Inlet Coolant Temperature Sensor Status";
CM_ SG_ 198 BCMFL_CoolantTemp_EDS_Out "Front EDS Outlet Coolant Temperature Sensor Status";
CM_ SG_ 198 BCMFL_ACLowSideTemperature "Low pressure side temperature of air conditioning";
CM_ SG_ 198 BCMFL_ACHighSideTemperature "Temperature on the high-pressure side of the air conditioner.";
CM_ SG_ 198 BCMFL_CoolantTemp_HtrCore_In "Heater Core Inlet Coolant Temperature";
CM_ SG_ 198 BCMFL_FEDSPump_Fault "Front EDS Fault Status";
CM_ SG_ 198 BCMFL_BMSPump_Fault "BMS Pump Fault Status";
CM_ SG_ 198 BCMFL_SOV_Fault "Identify SOV error";
CM_ SG_ 198 BCMFL_CoolingFan_Fault "Identify Cooling Fan error";
CM_ SG_ 198 BCMFL_CoolantLevel2 "Coolant level 2 status";
CM_ SG_ 198 BCMFL_Refrigerant_Temp_Sensor "Refrigerant temperature sensor signal";
CM_ SG_ 198 BCMFL_PT_Sensor1_Pressure "The pressure value of pressure temperature integrated sensor 1";
CM_ SG_ 198 BCMFL_PT_Sensor1_Temp "Temperature value of pressure temperature integrated sensor 1";
CM_ SG_ 198 BCMFL_PT_Sensor2_Pressure "The pressure value of pressure temperature integrated sensor 2";
CM_ SG_ 198 BCMFL_PT_Sensor2_Temp "Temperature value of pressure temperature integrated sensor 2";
CM_ SG_ 198 BCMFL_RearACLowSidePressureSts "Rear Evaporator refrigerant pressure sensor status";
CM_ SG_ 198 BCMFL_RearACLowSideTemperatureSt "Rear Evaporator refrigerant temperature sensor status";
CM_ SG_ 198 BCMFL_REDSPump_Fault "Rear EDS Fault Status";
CM_ SG_ 198 BCMFL_RearACLowSidePressure "Rear Evaporator actual refrigerant pressure";
CM_ SG_ 198 BCMFL_RearACLowSideTemperature "Rear Evaporator actual refrigerant temperature";
CM_ SG_ 199 BCMFL_BatterySOV_Status "Battery Chiller SOV ON/OFF status";
CM_ SG_ 199 BCMFL_EvapSOV_Status "Evap SOV ON/OFF status";
CM_ SG_ 199 BCMFL_FEDSPump_PWM_Set "Front EDS Pump Set PWM";
CM_ SG_ 199 BCMFL_BMSPump_PWM_Set "BMS Pump Set PWM";
CM_ SG_ 199 BCMFL_REDSPump_PWM_Set "Rear EDS Pump Set PWM";
CM_ SG_ 199 BCMFL_WaterPump4_PWM_Set "set value of Water Pump4";
CM_ SG_ 199 BCMFL_CoolingFan_PWM_Set "set value of Cooling Fan";
CM_ SG_ 252 BCMFL_WasherPumpSts "The status of the left front washing pump";
CM_ SG_ 252 BCMFL_Wiper_Front_Status "Feedback the front wiper working status";
CM_ SG_ 252 BCMFL_STAT_FrontWiperServiceMode "Feedback the front wiper service mode";
CM_ SG_ 252 BCMFL_FrontWiperStepTimeStatus "Operate wiper with delay time between each cycle and feedback to CVC";
CM_ SG_ 252 BCMFL_WiperServiceModeSts "Enable front wiper to service position and feedback to CVC";
CM_ SG_ 252 BCM_Fr_Rr_WashAndMist_Status "Front and Rear Washer and Mist function status from BCM_FL to CVC";
CM_ SG_ 252 BCMFL_InteriorTemperature "Real time temperature inside the car";
CM_ SG_ 252 WakeupForTopup_Req "Request for power replenishment";
CM_ SG_ 252 CntContWakeup "Number of awakenings";
CM_ SG_ 252 BCMFL_InteriorTemperatureSts "Real time temperature status inside the car";
CM_ SG_ 252 BCM_Front_Wiper_Park_Pos_Status "Front Wiper Park Position Status";
CM_ SG_ 252 BCM_FL_STAT_RearHeatedWindowMirr "The relevant status of the rear window heating function and the rearview mirror heating function";
CM_ SG_ 252 BCMFL_STAT_Horn "Horn output Status";
CM_ SG_ 252 BCMFL_PowerOutlet_Sts "Status Power outlet";
CM_ SG_ 260 CRC_BCM_FL_Measured_Data "Checksum";
CM_ SG_ 260 ALIVE_BCM_FL_Measured_Data "Alive counter";
CM_ SG_ 260 SOH_SUL "Actual name LV_SOH (State of Health)";
CM_ SG_ 260 SOH_SUL_STATE "Actual name LV_SOH_Sts (SOH Status)";
CM_ SG_ 260 SOC_STATE "SOC Status";
CM_ SG_ 260 Resp_Error "Resp_Error";
CM_ SG_ 260 FLAG_INCONSTENCY "Battery inconsistency flag";
CM_ SG_ 260 EBS_error "EBS error";
CM_ SG_ 260 FLAG_DISCONNECT "Battery disconnection flag";
CM_ SG_ 260 IBATT_QUIESCENT "IBATT_QUIESCENT";
CM_ SG_ 260 LV_TargetCurrent "Target battery current from LV BMS";
CM_ SG_ 260 LV_TargetVoltage "LV BMS sends out expected target voltage";
CM_ SG_ 260 LV_ContinuousWakeUpCnt "Continuous wake-up count of low-voltage system";
CM_ SG_ 266 CRC_BCM_VOLTAGE "Checksum";
CM_ SG_ 266 ALIVE_BCM_VOLTAGE "Alive counter";
CM_ SG_ 266 LV_BatteryType "LV Battery Type (Lead Acid or Lithium)";
CM_ SG_ 266 UBatt "Battery Voltage";
CM_ SG_ 266 LV_Batt_Temp_Reserved "Low voltage Battery Temperature";
CM_ SG_ 266 LV_SOC_Reserved "State Of charge for Low Voltage Battery";
CM_ SG_ 266 LV_Batt_Current_Reserved "Current of Low Voltage Battery";
CM_ SG_ 277 BCM_ChildLock_Feedback "Response for Childlock Status";
CM_ SG_ 280 CRC_BCM_MHU_Ctrl_Fbk "Checksum";
CM_ SG_ 280 ALIVE_BCM_MHU_Ctrl_Fbk "Alive Counter";
CM_ SG_ 280 BCM_DrvInhibitStsFbk "BCM Feedback status for Driving Inhibition";
CM_ SG_ 529 BCM_LowBeam_FL_Sts "Low beam headlight left front status";
CM_ SG_ 529 BCM_HighBeam_FL_Sts "High beam left front status";
CM_ SG_ 529 BCM_TurnIndicator_FL_STS "Feedback status of left front indicator";
CM_ SG_ 529 BCM_PositionLight_FL_STS "Left front position light feedback status";
CM_ SG_ 529 BCM_RearFogLamp_FL_STS "Feedback front left fog lamp";
CM_ SG_ 529 BCM_HeightSensorSTS_Front "The working status of the front height sensor";
CM_ SG_ 529 BCM_HeightSensorValue_Front "Voltage value of front height sensor";
CM_ SG_ 529 BCM_MirrorLED_FL_STS "The status of the left front and rear mirror LED lights, such as the switch or fault status of the lights";
CM_ SG_ 529 BCM_HazardButton_FL_STS "The status of the left front (or specific position) hazard warning light button";
CM_ SG_ 529 BCM_DaytimeRunningLight_FL_Sts "Working status of left front daytime running light";
CM_ SG_ 529 BCM_FrontFogLamp_FL_STS "Working status of left front fog lamp";
CM_ SG_ 532 BCM_Mirror_CourtesyLightSts "Left front door courtesy light status";
CM_ SG_ 532 BCM_FL_BonnetSts "Engine hood condition";
CM_ SG_ 532 BCM_FL_BonnetLightSts "Engine hood light status";
CM_ SG_ 532 BCM_FLFootwellLightSts "Foot lighting lamp status";
CM_ SG_ 532 BCM_FL_FrontDomeLampStatus "Front roof light status";
CM_ SG_ 532 BCM_FLScuffLightSts "Left front threshold light status";
CM_ SG_ 532 BCM_FLProjectorLightSts "Left front projection lamp status";
CM_ SG_ 561 CRC_DoorFLStatus "Checksum";
CM_ SG_ 561 ALIVE_DoorFLStatus "Alive counter";
CM_ SG_ 561 DOW_DoorAjarStatusRL "Left rear door slightly open state";
CM_ SG_ 561 DOW_DoorAjarStatusFL "Left front door slightly open state";
CM_ SG_ 805 BCMFL_STAT_SteerPosX "Adjustment of the X position of the steering wheel";
CM_ SG_ 805 BCMFL_STAT_SteerPosY "Adjustment of the Y position of the steering wheel";
CM_ SG_ 805 Steering_Wheel_Telescope_Positio "Adjustment of the telescopic position of the steering wheel";
CM_ SG_ 805 Steering_Wheel_Convenience_Acces "Convenient access status of steering wheel";
CM_ SG_ 805 Steering_Wheel_Angle_Status "Steering wheel angle adjustment";
CM_ SG_ 805 Steering_HeatingControlFdbk "Steering wheel heating status";
CM_ SG_ 805 BCMFL_STS_SteerAdjust "Steering wheel adjustment state";
CM_ SG_ 805 SWHC_SterringWheelHeatFaultReaso "Reason for steering wheel heating malfunction";
CM_ SG_ 805 Steer_ProfileSave_Tips "Prompt for successful saving of current steering wheel posture";
CM_ SG_ 805 Steer_ColUpDown_Sts "Comfortable steering wheel up and down movement state";
CM_ SG_ 805 Steer_ElecAdjust_SettingSts "Steering wheel electric adjustment setting status";
CM_ SG_ 1049 SHVU_STAT_SeatHeatingFrontL "Change Seat heating with 3 level";
CM_ SG_ 1049 SHVU_STAT_SeatCoolingFrontL "Change Seat cooling with 3 level";
CM_ SG_ 1049 SHVU_STAT_FrontSeatVentSts "Indicate current status of front seat ventilation system";
CM_ SG_ 1065 BCMFL_SeatRecliner_Sw "The switch to control recliner position of the Seat front left";
CM_ SG_ 1065 BCMFL_SeatTilt_Sw "The switch to control tilt position of the Seat front left";
CM_ SG_ 1065 BCMFL_SeatHeight_Sw "The switch to control height position of the Seat front left";
CM_ SG_ 1065 BCMFL_SeatTrack_Sw "The switch to control track position of the Seat front left";
CM_ SG_ 1065 BCMFL_SeatTrack_Pos "The track position of the Seat front left sent by BCM_FL";
CM_ SG_ 1065 BCMFL_SeatTilt_Pos "The tilt position of the Seat front left sent by BCM_FL";
CM_ SG_ 1065 BCMFL_SeatHeight_Pos "The height position of the Seat front left sent by BCM_FL";
CM_ SG_ 1065 BCMFL_SeatRecline_Pos "The recline position of the Seat front left sent by BCM_FL";
CM_ SG_ 1065 BCMFL_SeatMassageLevel_Sts "The actual status of front left seat massage mode";
CM_ SG_ 1065 BCMFL_SeatMassageMode_Sts "The actual status of front left seat massage mode";
CM_ SG_ 1065 BCMFL_SeatControl_Sts "The information from BCM FL to CVC to indicate the front left seat is moving by CVC_B or switch.";
CM_ SG_ 1065 BCMFL_SeatVentilation_Sts "BCM_FL send feedback of Front Left Seat Ventilation Status";
CM_ SG_ 1065 BCMFL_SeatHeating_Sts "BCM_FL send feedback of Front Left Seat Heating Status";
CM_ SG_ 1065 BCMFL_FrontPsg_SeatTrack_Pos "The track position of the Seat front passenger sent by BCM_FL";
CM_ SG_ 1071 BCMFL_STAT_LeftMirrorHeating "Feedback Left mirror heating status";
CM_ SG_ 1071 BCMFL_STAT_LeftMirrorFold "Control the mirror fold/unfold and feedback mirror status";
CM_ SG_ 1071 BCMFL_STAT_MirrorAdjustLeft "Feedback actual left mirror position";
CM_ SG_ 1071 BCMFL_STAT_LeftMirrorPosX "Feedback actual left mirror left right position";
CM_ SG_ 1071 BCMFL_STAT_LeftMirrorPosY "Feedback actual left mirror up down position";
CM_ SG_ 1111 AmbLight_Error_Z3 "Status of Ambient Light ColorZone 3";
CM_ SG_ 1111 AmbLight_Linerror_Z3 "Status of Ambient Light ColorZone 3";
CM_ SG_ 1111 AmbLight_Error_Z3B "Status of Ambient Light ColorZone 3";
CM_ SG_ 1111 AmbLight_Linerror_Z3B "Status of Ambient Light ColorZone 3";
CM_ SG_ 1118 CRC_BCM_Heater_Feedback "Checksum";
CM_ SG_ 1118 ALIVE_BCM_Heater_Feedback "Alive Counter";
CM_ SG_ 1118 BCM_HeaterActivation_Feedback "Windshield Heater Feedback from BCM";
CM_ SG_ 1153 CRC_BCM_FL_WarnMsg_FL "Checksum BCM Warning Message";
CM_ SG_ 1153 ALIVE_BCM_FL_WarnMsg_FL "Alive counter";
CM_ SG_ 1153 BCM_FL_TurnOffPosLightRemindr "Driver forget to turn off Position Lights during leaving car";
CM_ SG_ 1153 BCM_FL_StopLightDefect "Stop light defect";
CM_ SG_ 1153 BCM_FL_LowBeamDefect "Low beam defect";
CM_ SG_ 1153 BCM_FL_HighBeamDefect "High beam defect";
CM_ SG_ 1153 BCM_FL_PositionLightDefect "Position light defect";
CM_ SG_ 1153 BCM_FL_CHMLS_Defect "CHMSL defect";
CM_ SG_ 1153 BCM_FL_LicencePlateLight_Defect "License plate light defect";
CM_ SG_ 1153 BCM_FL_FrontFog_Defect "Front fog lamp defect";
CM_ SG_ 1153 BCM_FL_RearLeftDoorLockDefect "Defects or malfunctions in the left rear door lock";
CM_ SG_ 1153 BCM_FL_ReverseLightDefect "Reverse lamp defect";
CM_ SG_ 1153 BCM_FL_12VBattery_LowLevel "Low level 12V Battery";
CM_ SG_ 1153 BCM_FL_12VBattery_Discharging "12V battery discharging";
CM_ SG_ 1153 BCM_FL_TurnIndicatorDefect "Turn indicator defect";
CM_ SG_ 1153 BCM_FL_IDB_Brakelight_Malfunctio "BCM detects brake light malfunction through internal data bus";
CM_ SG_ 1153 BCM_FL_CVC_Brakelight_Malfunctio "When BCM communicates with CVC, it is found that there is a fault with the brake light";
CM_ SG_ 1153 BCM_FL_ADAS_Turnlight_Malfunctio "BCM detects a malfunction in the turn signal during ADAS interaction";
CM_ SG_ 1153 BCM_FL_ADAS_Highbeam_Malfunction "BCM and ADAS have discovered a malfunction in the high beam headlights";
CM_ SG_ 1153 BCM_FL_ADAS_LowBeam_Malfunction "BCM and ADAS have discovered a malfunction in the low beam headlights";
CM_ SG_ 1153 BCM_FL_CVC_B_Malfunction "BCM detects CVC-B fault";
CM_ SG_ 1153 BCM_FL_BCM_Malfunction "Left front BCM detected internal malfunction";
CM_ SG_ 1153 BCM_FL_CrashSignalDefect "Crash Unlcokxa0Signalxa0error";
CM_ SG_ 1153 BCM_FL_RearFog_Defect "Rear fog lamp defect";
CM_ SG_ 1153 BCM_FL_FrontWiperDefect "Front wiper Fail";
CM_ SG_ 1153 BCM_FL_FrontLeftDoorLockDefect "FrontLeftDoorLock Fail";
CM_ SG_ 1153 BCM_FL_RLT_Malfunction "Tailgate ligth driver module Malfunction";
CM_ SG_ 1153 BCM_FL_BCM_POWER_Malfunction "BCM detects a malfunction in its own power system";
CM_ SG_ 1217 CRC_APM_FL_WarnMsg "Checksum";
CM_ SG_ 1217 ALIVE_APM_FL_WarnMsg "Alive Counter";
CM_ SG_ 1217 APM_FL_Malfunction "Anti-pinch module malfunction";
CM_ SG_ 1217 APM_FL_ChildWindowLockStS "Child window lock status";
CM_ SG_ 1217 APM_FL_Warning_Flag_3 "Warning Message Flag, Component owner, Supplier align and define for this signal";
CM_ SG_ 1217 APM_FL_Warning_Flag_4 "Warning Message Flag, Component owner, Supplier align and define for this signal";
CM_ SG_ 1217 APM_FL_Warning_Flag_5 "Warning Message Flag, Component owner, Supplier align and define for this signal";
CM_ SG_ 1217 APM_FL_Warning_Flag_6 "Warning Message Flag, Component owner, Supplier align and define for this signal";
CM_ SG_ 1217 APM_FL_Warning_Flag_7 "Warning Message Flag, Component owner, Supplier align and define for this signal";
CM_ SG_ 1217 APM_FL_Warning_Flag_8 "Warning Message Flag, Component owner, Supplier align and define for this signal";
CM_ SG_ 1217 APM_FL_Warning_Flag_9 "Warning Message Flag, Component owner, Supplier align and define for this signal";
CM_ SG_ 1217 APM_FL_Warning_Flag_10 "Warning Message Flag, Component owner, Supplier align and define for this signal";
CM_ SG_ 1217 APM_FL_Warning_Flag_11 "Warning Message Flag, Component owner, Supplier align and define for this signal";
CM_ SG_ 1217 APM_FL_Warning_Flag_12 "Warning Message Flag, Component owner, Supplier align and define for this signal";
CM_ SG_ 160 CRC_BCMFR_KeyFOB_Status "Check sum";
CM_ SG_ 160 ALIVE_BCMFR_KeyFOB_Status "Rolling Counter";
CM_ SG_ 160 KeyFOBAuthenStatus "Feedback  Key FOB authentication status to CVC";
CM_ SG_ 160 KeyFOBPosition "Feedback Key FOB position";
CM_ SG_ 160 FobId "Information of FOB ID.";
CM_ SG_ 160 BCMFR_KeyFob_LowBattery "Feedback Key FOB low battery information to CVC for user warning";
CM_ SG_ 160 BCMFR_KeyIgnoringStatus "Feedback Key FOB allow status to CVC";
CM_ SG_ 171 CRC_BCMFR_DoorStatus "Checksum";
CM_ SG_ 171 ALIVE_BCMFR_DoorStatus "Alive counter";
CM_ SG_ 171 CoDriverDoor_Ajar_Sts "Ajar Door Front Right Status";
CM_ SG_ 171 RRDoor_Ajar_Sts "Ajar Door Rear Right Status";
CM_ SG_ 171 CoDriverDoor_Lock_Sts "Right front door lock status";
CM_ SG_ 171 RRDoor_Lock_Sts "Right rear door lock status";
CM_ SG_ 177 KeyFOB_Request "Key FOB request status";
CM_ SG_ 181 BCMFR_WindowsFR_AntiPinch_Warn "Feedback anti-pinch status to CVC for HMI warning";
CM_ SG_ 181 BCMFR_WindowFR_Learning_Sts "Feedback learning status to CVC";
CM_ SG_ 181 BCMFR_WindowFR_Suppression_Warn "Feedback the lifter suppression status";
CM_ SG_ 181 BCMFR_WindowFR_LockActive "Feedback current window lock status";
CM_ SG_ 181 BCMFR_WindowFR_ThermalProtect "Feedback thermal protection status";
CM_ SG_ 181 BCMFR_WindowFR_Error "Feedback front right  window error position to CVC for corresponding warning on HMI";
CM_ SG_ 181 BCMFR_WindowsRR_AntiPinch_Warn "Feedback anti-pinch status to CVC for HMI warning";
CM_ SG_ 181 BCMFR_WindowRR_LockActive "Feedback current window lock status";
CM_ SG_ 181 BCMFR_WindowRR_Error "Feedback rear right window error position to CVC for corresponding warning on HMI";
CM_ SG_ 181 BCMFR_WindowRR_Learning_Sts "Feedback learning status to CVC";
CM_ SG_ 181 BCMFR_WindowRR_Suppression_Warn "Feedback the lifter suppression status";
CM_ SG_ 181 BCMFR_WindowRR_ThermalProtect "Feedback thermal protection status";
CM_ SG_ 181 BCMFR_WindowBtnPress_FrontPass "Front Right Window button status";
CM_ SG_ 181 Window_Position_FR "Feedback the current front right window position to CVC";
CM_ SG_ 181 Window_Position_RR "Feedback the current rear right window position to CVC";
CM_ SG_ 181 BCMFR_WindowBtnPress_RR "Rear Right Window Button status";
CM_ SG_ 194 BCMFR_AQS_NOx_Input "Air Quality Sensor - NOx Input";
CM_ SG_ 194 BCMFR_AQS_COx_Input "Air Quality Sensor - COx Input";
CM_ SG_ 194 BCMFR_AQS_PreHeating_Input "Air Quality Sensor - PreHeating Input";
CM_ SG_ 195 BCMFR_DuctTempRightFace "Right Face Duct Temperature Sensor real-time value";
CM_ SG_ 195 BCMFR_DuctTempLeftFace "Left Face Duct Temperature Sensor  real-time value";
CM_ SG_ 195 BCMFR_DuctTempRightFoot "Right Foot Duct Temperature Sensor  real-time value";
CM_ SG_ 195 BCMFR_DuctTempLeftFoot "Left Foot Duct Temperature Sensor  real-time value";
CM_ SG_ 195 BCMFR_DuctTempSensor5Input "Discharge Air Temperature Sensor5";
CM_ SG_ 195 BCMFR_DuctTempSensor6Input "Discharge Air Temperature Sensor6";
CM_ SG_ 195 BCMFR_DuctTempSensor7Input "Discharge Air Temperature Sensor7";
CM_ SG_ 195 BCMFR_DuctTempSensor8Input "Discharge Air Temperature Sensor8";
CM_ SG_ 195 BCMFR_PTCTempInlet "Front PTC heater inlet temperature";
CM_ SG_ 195 BCMFR_PTCTempOutletLe "Left outlet temperature of front PTC heater";
CM_ SG_ 195 BCMFR_PTCTempOutletRi "Right outlet temperature of front PTC heater";
CM_ SG_ 195 BCMFR_InteriorTemp "Front interior temperature";
CM_ SG_ 195 BCMFR_Humidity "Front interior humidity";
CM_ SG_ 195 BCMFR_HumiditySts "Working status of dehumidification system";
CM_ SG_ 195 BCMFR_PM25 "PM2.5 concentration value inside the front of the car";
CM_ SG_ 195 BCMFR_PM25Sts "PM2.5 monitoring status";
CM_ SG_ 195 BCMFR_CO2 "Carbon dioxide concentration value inside the front of the car";
CM_ SG_ 195 BCMFR_CO2Sts "CO ₂ monitoring status";
CM_ SG_ 195 BCMFR_DucTempRightFaceSts "Temperature status of the right facial air outlet";
CM_ SG_ 195 BCMFR_DucTempLeftFaceSts "Temperature status of the left facial air outlet";
CM_ SG_ 195 BCMFR_DucTempRightFootSts "Temperature status of the right foot air outlet";
CM_ SG_ 195 BCMFR_DucTempLeftFootSts "Temperature status of the left foot air outlet";
CM_ SG_ 195 BCMFR_RearEvapTempSensorInput "Rear Evaporator Air Outlet Temperature";
CM_ SG_ 195 BCMFR_RearEvapTempSensorInputSts "Rear evaporator temperature sensor status";
CM_ SG_ 195 BCMFR_RearVentDuctTemp "Rear Face Duct Actual Temperature";
CM_ SG_ 195 BCMFR_RearFootDuctTemp "Rear Foot Duct Actual Temperature";
CM_ SG_ 195 BCMFR_RearVentDuctTempSts "Rear Face Duct Temperature Sensor Status";
CM_ SG_ 195 BCMFR_RearFootDuctTempSts "Rear Foot Duct Temperature Sensor Status";
CM_ SG_ 200 BCMFR_Climate_IonizerSts "current Ionizer ON/OFF status";
CM_ SG_ 200 BCMFR_Climate_AirDistFlapPos "actual air distribution position";
CM_ SG_ 200 BCMFR_Climate_RHTempFlapPos "actual Right temperature Flap position";
CM_ SG_ 200 BCMFR_Climate_LHTempFlapPos "actual Left temperature Flap position";
CM_ SG_ 200 BCMFR_Climate_BlowerRelay "Blower relay status";
CM_ SG_ 200 BCMFR_Climate_BlowerStatus "current Blower status";
CM_ SG_ 200 BCMFR_Climate_LHTempFlapSts "current Temperature Flap (left-hand flap) status";
CM_ SG_ 200 BCMFR_Climate_RHTempFlapSts "current Temperature Flap (right-hand flap) status";
CM_ SG_ 200 BCMFR_Climate_AirDistFlapSts "current  air distribution status";
CM_ SG_ 200 BCMFR_Climate_AirRecirculationPo "actual Recirculation Flap position";
CM_ SG_ 200 BCMFR_Climate_AirDistFlapLHPos "Mode Flap LH Actual Position";
CM_ SG_ 200 BCMFR_Climate_AirDistFlapLHSts "Mode Flap LH Status";
CM_ SG_ 204 BCMFR_InteriorTempSts "Interior (INCAR )Temperature Sensor Error";
CM_ SG_ 204 BCMFR_PTCTempInletSts "PTC Air Inlet Temperature Sensor Error";
CM_ SG_ 204 BCMFR_PTCTempOutletLeSts "Left PTC Air Outlet Temperature Sensor Error";
CM_ SG_ 204 BCMFR_PTCTempOutletRiSts "Right PTC Air Outlet Temperature Sensor Error";
CM_ SG_ 204 BCMFR_EvapTempSensorInputSts "Evaporator Temperature Sensor Error";
CM_ SG_ 204 BCMFR_EvapTempSensorInput "the Evaporator Temperature with Celcius Degree";
CM_ SG_ 251 RLSFailureFeedback "Feedback the rain sensor error status to CVC";
CM_ SG_ 251 BCMFR_RS_L_WiperSpeed "Send the wiper speed request by Rain Sensor to CVC";
CM_ SG_ 251 BCMFR_WasherFluidLevelSensorData "Feedback the washer fluid level to CVC";
CM_ SG_ 251 BCMFR_WasherPumpSts "Feedback the washer pump working status to CVC";
CM_ SG_ 251 BCMFR_Rear_Wiper_Park_Pos_Status "Feedback the rear wiper status at parking position";
CM_ SG_ 251 BCMFR_STAT_RearWiperServiceMode "Feedback the rear wiper service mode";
CM_ SG_ 251 BCMFR_STAT_RearWiperWorkingSts "Feedback the rear wiper working status";
CM_ SG_ 251 BCMFR_RearWiperWorkingSts "Feedback the rear wiper working status";
CM_ SG_ 251 BCM_AlcoholockSwitch "AlcoholockSwithDetect";
CM_ SG_ 251 CentralLockLightStatus "Central Locking Light status";
CM_ SG_ 279 BCM_Stat_SwitchLightBrightness "BCM_Stat_SwitchLightBrightness";
CM_ SG_ 286 BCMFR_CL30s_FR_Sts "Feedback status of clamp 30s FR side";
CM_ SG_ 286 BCMFR_CL30c_FR_Sts "Feedback status of clamp 30c FR side";
CM_ SG_ 286 BCMFR_CLR_FR_Sts "Feedback status of clamp_R FR side";
CM_ SG_ 286 BCMFR_CL15_FR_Sts "Feedback status of clamp 15 FR side";
CM_ SG_ 286 BCMFR_CL58_FR_Sts "Feedback status of clamp 58 FR side";
CM_ SG_ 286 BCMFR_CL30s_Timer "CL30s Idle timer";
CM_ SG_ 530 BCM_TurnIndicator_FR_STS "Feedback status of FR indicator";
CM_ SG_ 530 BCM_PositionLight_FR_STS "Feedback on the status of the right reversing light";
CM_ SG_ 530 BCM_FrontFogLamp_FR_STS "Front right daytime running light status";
CM_ SG_ 530 BCM_DaytimeRunningLight_FR_Sts "Front right rearview mirror LED status";
CM_ SG_ 530 BCM_MirrorLED_FR_STS "Front right low beam status";
CM_ SG_ 530 BCM_LowBeam_FR_Sts "Front right high beam status";
CM_ SG_ 530 BCM_HighBeam_FR_Sts "Feedback right brake light status";
CM_ SG_ 534 BCM_FRDoorCourtesyLightSts_Reser "Front right door welcome light status";
CM_ SG_ 534 BCM_FRFootwellLightSts "Front right foot light status";
CM_ SG_ 534 BCM_FRScuffLightSts "Front right threshold light status";
CM_ SG_ 534 BCM_FRProjectorLightSts "Front right projection lamp status";
CM_ SG_ 584 DOW_DoorAjarStatusRR "Ajar Door Rear Right Status";
CM_ SG_ 584 DOW_DoorAjarStatusFR "Ajar Door Front Right Status";
CM_ SG_ 809 CRC_BCM_ODO "Checksum";
CM_ SG_ 809 ALIVE_BCM_ODO "Alive counter";
CM_ SG_ 809 Odometer_BCM "Odometer infomation for IPC.";
CM_ SG_ 896 VIN_Byte1 "This signal contains the seventh last digit of the chassis number. (The individual digits are encoded in ASCII characters.)";
CM_ SG_ 896 VIN_Byte2 "This signal contains the sixth last digit of the chassis number. (The individual digits are encoded in ASCII characters.)";
CM_ SG_ 896 VIN_Byte3 "This signal contains the fifth last digit of the chassis number. (The individual digits are encoded in ASCII characters.)";
CM_ SG_ 896 VIN_Byte4 "This signal contains the fourth last digit of the chassis number. (The individual digits are encoded in ASCII characters.)";
CM_ SG_ 896 VIN_Byte5 "This signal contains the third last digit of the chassis number. (The individual digits are encoded in ASCII characters.)";
CM_ SG_ 896 VIN_Byte6 "This signal contains the penultimate digit of the chassis number. (The individual digits are encoded in ASCII characters.)";
CM_ SG_ 896 VIN_Byte7 "This signal contains the last digit of the chassis number. (The individual digits are encoded in ASCII characters.)";
CM_ SG_ 920 BCM_Immo_Byte_0 "BCM Authentication signal byte 0";
CM_ SG_ 920 BCM_Immo_Byte_1 "BCM Authentication signal byte 1";
CM_ SG_ 920 BCM_Immo_Byte_2 "BCM Authentication signal byte 2";
CM_ SG_ 920 BCM_Immo_Byte_3 "BCM Authentication signal byte 3";
CM_ SG_ 920 BCM_Immo_Byte_4 "BCM Authentication signal byte 4";
CM_ SG_ 920 BCM_Immo_Byte_5 "BCM Authentication signal byte 5";
CM_ SG_ 920 BCM_Immo_Byte_6 "BCM Authentication signal byte 6";
CM_ SG_ 920 BCM_Immo_Byte_7 "BCM Authentication signal byte 7";
CM_ SG_ 923 BCM_Immo_CVC_B_Byte_0 "BCM Authentication signal byte 0 with CVC_B";
CM_ SG_ 923 BCM_Immo_CVC_B_Byte_1 "BCM Authentication signal byte 1 with CVC_B";
CM_ SG_ 923 BCM_Immo_CVC_B_Byte_2 "BCM Authentication signal byte 2 with CVC_B";
CM_ SG_ 923 BCM_Immo_CVC_B_Byte_3 "BCM Authentication signal byte 3 with CVC_B";
CM_ SG_ 923 BCM_Immo_CVC_B_Byte_4 "BCM Authentication signal byte 4 with CVC_B";
CM_ SG_ 923 BCM_Immo_CVC_B_Byte_5 "BCM Authentication signal byte 5 with CVC_B";
CM_ SG_ 923 BCM_Immo_CVC_B_Byte_6 "BCM Authentication signal byte 6 with CVC_B";
CM_ SG_ 923 BCM_Immo_CVC_B_Byte_7 "BCM Authentication signal byte 7 with CVC_B";
CM_ SG_ 1051 SHVU_STAT_SeatHeatingFrontR "Change Seat heating with 3 level";
CM_ SG_ 1051 SHVU_STAT_SeatCoolingFrontR "Change Seat cooling with 3 level";
CM_ SG_ 1051 SHVU_STAT_FrontSeatVentSts "Indicate current status of front seat ventilation system";
CM_ SG_ 1072 BCMFR_STAT_RightMirrorHeating "Feedback right mirror heating status";
CM_ SG_ 1072 BCMFR_STAT_RightMirrorFold "Control right mirror fold/unfold and feedback mirror status";
CM_ SG_ 1072 BCMFR_STAT_MirrorAdjustRight "Feedback actual right mirror position";
CM_ SG_ 1072 BCMFR_STAT_RightMirrorPosX "Feedback actual right mirror left right position";
CM_ SG_ 1072 BCMFR_STAT_RightMirrorPosY "Feedback actual right mirror up down position";
CM_ SG_ 1076 BCMFR_SeatMassageLevel_Sts "The actual status of front right seat massage level";
CM_ SG_ 1076 BCMFR_SeatMassageMode_Sts "The actual status of front right seat massage mode";
CM_ SG_ 1076 BCMFR_SeatTrack_Pos "The information of Seat Track Position of front right seat from BCM_FR send to CVC";
CM_ SG_ 1076 BCMFR_SeatVentilation_Sts "BCM_FR send feedback of Front Right Seat Ventilation Status";
CM_ SG_ 1076 BCMFR_SeatHeating_Sts "BCM_FR send feedback of Front Right Seat Heating Status";
CM_ SG_ 1151 TPMS_RRTireSignalLost "Send the lost rear right sensor alert to CVC";
CM_ SG_ 1151 TPMS_RLTireSignalLost "Send the lost rear left sensor alert to CVC";
CM_ SG_ 1151 TPMS_FRTireSignalLost "Send the lost front right sensor alert to CVC";
CM_ SG_ 1151 TPMS_FLTireSignalLost "Send the lost front left sensor alert to CVC";
CM_ SG_ 1155 TPMS_FLTirePress "Front left tire pressure signal";
CM_ SG_ 1155 TPMS_FRTirePress "Front right tire pressure signal";
CM_ SG_ 1155 TPMS_RLTirePress "Rear left tire pressure signal";
CM_ SG_ 1155 TPMS_RRTirePress "Rear right tire pressure signal";
CM_ SG_ 1155 TPMS_FLTirePressAlarm "Front left tire pressure alarm  signal";
CM_ SG_ 1155 TPMS_FRTirePressAlarm "Front right tire pressure alarm signal";
CM_ SG_ 1155 TPMS_RLTirePressAlarm "Rear left tire pressure alarm signal";
CM_ SG_ 1155 TPMS_RRTirePressAlarm "Rear right tire pressure alarm signal";
CM_ SG_ 1155 TPMS_TirePosition "Tire position signal";
CM_ SG_ 1155 TPMS_ready2learning "BCM feedback signal ready to learning";
CM_ SG_ 1155 TPMS_TireTempAlarm "Tire temperature alarm signal";
CM_ SG_ 1155 TPMS_LearningStatus "BCM feedback signal for learning status";
CM_ SG_ 1155 TPMS_TireTemp "Tire temperature signal";
CM_ SG_ 1158 CRC_TPMS_TirePressure2 "Checksum";
CM_ SG_ 1158 ALIVE_TPMS_TirePressure2 "Alive Counter";
CM_ SG_ 1158 TPMS_FLTirePressAlarm2 "Front left tire pressure alarm  signal";
CM_ SG_ 1158 TPMS_FRTirePressAlarm2 "Front right tire pressure alarm signal";
CM_ SG_ 1158 TPMS_RLTirePressAlarm2 "Rear left tire pressure alarm signal";
CM_ SG_ 1158 TPMS_RRTirePressAlarm2 "Rear right tire pressure alarm signal";
CM_ SG_ 1158 TPMS_FLTireBattVoltage "Send front left tire pressure Battery Voltage status to CVC";
CM_ SG_ 1158 TPMS_FRTireBattVoltage "Send front right tire pressure Battery Voltage status to CVC";
CM_ SG_ 1158 TPMS_RRTireBattVoltage "Send rear right tire pressure Battery Voltage status to CVC";
CM_ SG_ 1158 TPMS_RLTireBattVoltage "Send rear left tire pressure Battery Voltage status to CVC";
CM_ SG_ 1169 AmbLight_Error_Z1 "Status of ambient light color area 1";
CM_ SG_ 1169 AmbLight_Linerror_Z1 "LIN error status of ambient light color area 1";
CM_ SG_ 1169 AmbLight_Error_Z2 "Status of ambient light color area 2";
CM_ SG_ 1169 AmbLight_Linerror_Z2 "LIN error status of ambient light color area 2";
CM_ SG_ 1169 AmbLight_Error_Z6 "Status of ambient light color zone 6";
CM_ SG_ 1169 AmbLight_LinError_Z6 "LIN error status for ambient light color zone 6";
CM_ SG_ 1169 AmbLight_Error_Z6B "Status of ambient light color zone 6B";
CM_ SG_ 1169 AmbLight_LinError_Z6B "LIN error status in ambient light color zone 6B";
CM_ SG_ 1169 AmbLight_Error_Z7 "Status of ambient light color area 7";
CM_ SG_ 1169 AmbLight_LinError_Z7 "LIN error status for ambient light color area 7";
CM_ SG_ 1169 AmbLight_Error_Z8 "Status of ambient light color area 8";
CM_ SG_ 1169 AmbLight_LinError_Z8 "LIN error status for ambient light color area 8";
CM_ SG_ 1169 AmbLight_Error_Z7B "Status of ambient light color area 7B";
CM_ SG_ 1169 AmbLight_LinError_Z7B "LIN error status in ambient light color area 7B";
CM_ SG_ 1169 AmbLight_Error_Z8B "Status of ambient light color area 8B";
CM_ SG_ 1169 AmbLight_LinError_Z8B "LIN error status in ambient light color area 8B";
CM_ SG_ 1169 AmbLight_Error_Z2B "Status of ambient light color area 2B";
CM_ SG_ 1169 AmbLight_LinError_Z2B "LIN error status in ambient light color area 2B";
CM_ SG_ 1220 CRC_APM_FR_WarnMsg "Checksum";
CM_ SG_ 1220 ALIVE_APM_FR_WarnMsg "Alive Counter";
CM_ SG_ 1220 APM_FR_Malfunction "Anti-pinch module malfunction";
CM_ SG_ 1220 APM_FR_ChildWindowLockStS "Child window lock status";
CM_ SG_ 1220 APM_FR_Warning_Flag_3 "Warning Message Flag, Component owner, Supplier align and define for this signal";
CM_ SG_ 1220 APM_FR_Warning_Flag_4 "Warning Message Flag, Component owner, Supplier align and define for this signal";
CM_ SG_ 1220 APM_FR_Warning_Flag_5 "Warning Message Flag, Component owner, Supplier align and define for this signal";
CM_ SG_ 1220 APM_FR_Warning_Flag_6 "Warning Message Flag, Component owner, Supplier align and define for this signal";
CM_ SG_ 1220 APM_FR_Warning_Flag_7 "Warning Message Flag, Component owner, Supplier align and define for this signal";
CM_ SG_ 1220 APM_FR_Warning_Flag_8 "Warning Message Flag, Component owner, Supplier align and define for this signal";
CM_ SG_ 1220 APM_FR_Warning_Flag_9 "Warning Message Flag, Component owner, Supplier align and define for this signal";
CM_ SG_ 1220 APM_FR_Warning_Flag_10 "Warning Message Flag, Component owner, Supplier align and define for this signal";
CM_ SG_ 1220 APM_FR_Warning_Flag_11 "Warning Message Flag, Component owner, Supplier align and define for this signal";
CM_ SG_ 1220 APM_FR_Warning_Flag_12 "Warning Message Flag, Component owner, Supplier align and define for this signal";
CM_ SG_ 1241 CRC_BCM_FR_WarnMsg_FR "Checksum BCM Warning Message";
CM_ SG_ 1241 ALIVE_BCM_FR_WarnMsg_FR "Alive counter";
CM_ SG_ 1241 BCM_FR_NoValidKey_1 "Illegal key in the car";
CM_ SG_ 1241 BCM_FR_NoValidKey_2 "Key FOBs are not in the car";
CM_ SG_ 1241 BCM_FR_TurnOffPosLightRemindr "Driver forget to turn off Position Lights during leaving car";
CM_ SG_ 1241 BCM_FR_KeyFob_LowBattery "Keyfob battery low";
CM_ SG_ 1241 BCM_FR_StopLightDefect "Stop light defect";
CM_ SG_ 1241 BCM_FR_LowBeamDefect "Low beam defect";
CM_ SG_ 1241 BCM_FR_HighBeamDefect "High beam defect";
CM_ SG_ 1241 BCM_FR_PositionLightDefect "Position light defect";
CM_ SG_ 1241 BCM_FR_CHMLS_Defect "CHMSL defect";
CM_ SG_ 1241 BCM_FR_LicencePlateLight_Defect "License plate light defect";
CM_ SG_ 1241 BCM_FR_FrontFog_Defect "Front fog lamp defect";
CM_ SG_ 1241 BCM_FR_RearFog_Defect "Rear fog lamp defect";
CM_ SG_ 1241 BCM_FR_ReverseLightDefect "Reverse lamp defect";
CM_ SG_ 1241 BCM_FR_ForgetKeyFOBInCar "Locking the car when the key in the car";
CM_ SG_ 1241 BCM_FR_TurnIndicatorDefect "Turn indicator defect";
CM_ SG_ 1241 BCM_FR_dTPMS_Malfunc "TPMS malfunction";
CM_ SG_ 1241 BCM_FR_dTPMS_Malfunc_LostSensor "TPMS Malfunction, Lost sensor alarm";
CM_ SG_ 1241 BCM_FR_dTPMS_LowPressure "Low tire pressure";
CM_ SG_ 1241 BCM_FR_dTPMS_RapidLeak "Rapid air leak alarm";
CM_ SG_ 1241 BCM_FR_dTPMS_HighTemperature "High tire temperature";
CM_ SG_ 1241 BCM_FR_dTPMS_HighPressure "High tire pressure";
CM_ SG_ 1241 BCM_FR_dTPMS_LowBattery "TPMS sensor Low battery";
CM_ SG_ 1241 BCM_Keyfob_Leftcar "Keyfob left the car warning";
CM_ SG_ 1241 BCM_FR_IDB_Brakelight_Malfunctio "BCM detects brake light malfunction through internal data bus";
CM_ SG_ 1241 BCM_FR_CVC_Brakelight_Malfunctio "When BCM communicates with VCU, it is found that there is a fault with the brake light";
CM_ SG_ 1241 BCM_FR_Turnlight_Malfunction "BCM detects a malfunction in the turn signal during ADAS interaction";
CM_ SG_ 1241 BCM_FR_Highbeam_Malfunction "BCM and ADAS have discovered a malfunction in the high beam headlights";
CM_ SG_ 1241 BCM_FR_LowBeam_Malfunction "BCM and ADAS have discovered a malfunction in the low beam headlights";
CM_ SG_ 1241 BCM_FR_Malfunction "BCMFR detects CVC-B fault";
CM_ SG_ 1241 BCM_FR_BCM_Malfunction "Right front BCM detected internal malfunction";
CM_ SG_ 1241 BCM_FR_SCM_Malfunction "SCM Malfunction";
CM_ SG_ 1241 BCM_FR_CrashSignalDefect "Crash Unlcokxa0Signalxa0error";
CM_ SG_ 1241 BCM_FR_FrontWiperDefect "Front wiper Fail";
CM_ SG_ 1241 BCM_FR_Front_RightDoorLockDefect "FrontRightDoorLock Fail";
CM_ SG_ 1241 BCM_FR_RLT_Malfunction "Tailgate ligth driver module Malfunction";
CM_ SG_ 1241 BCM_FR_BCM_POWER_Malfunction "BCM detects a malfunction in its own power system";
CM_ SG_ 1241 BCM_FR_RRDoorLockDefect "BCM detects a fault in the right rear door lock";
CM_ SG_ 133 CRC_ACU_CRASH_INFO "Checksum";
CM_ SG_ 133 ALIVE_ACU_CRASH_INFO "Alive Counter";
CM_ SG_ 133 ACU_Crash_Sts "Crash status";
CM_ SG_ 133 ACU_Airbag_Deployment_Status "Signal to indicate if airbag pretensioner pyrofuse is deployed";
CM_ SG_ 133 ACU_Crash_Intensity "Indicate crash intensity level";
CM_ SG_ 133 ACU_Front_Crash "Frontal collision";
CM_ SG_ 133 ACU_DriverSide_Crash "Driver's side collision";
CM_ SG_ 133 ACU_PassSide_Crash "Passenger side collision";
CM_ SG_ 133 ACU_Rear_Crash "Rear collision";
CM_ SG_ 133 ACU_Rollover_Crash "Has the vehicle experienced a rollover collision";
CM_ SG_ 162 WLS_SwitchStuck_State_RR "Right rear window switch stuck state";
CM_ SG_ 162 WLS_SwitchStuck_State_RL "Left rear window switch stuck state";
CM_ SG_ 162 WLS_SwitchStuck_State_FR "Right front window switch stuck state";
CM_ SG_ 162 WLS_SwitchStuck_State_FL "Left front window switch stuck state";
CM_ SG_ 162 WLS_WindowBtnPress_FL "Front Left Windows button status";
CM_ SG_ 162 WLS_WindowBtnPress_FR "Front Right Windows button status";
CM_ SG_ 162 WLS_WindowBtnPress_RL "Rear Left Windows button status";
CM_ SG_ 162 WLS_WindowBtnPress_RR "Rear Right Windows button status";
CM_ SG_ 162 WLS_DoorLockbtnPress "Windows Lock button status";
CM_ SG_ 176 CVC_Window_Control_FL "Request to front left windows according to user action";
CM_ SG_ 176 CVC_Window_Control_FR "Request to front right windows according to user action";
CM_ SG_ 176 CVC_Window_Control_RL "Request to rear left windows according to user action";
CM_ SG_ 176 CVC_Window_Control_RR "Request to rear right windows according to user action";
CM_ SG_ 176 CVC_Windows_Control_Global "Request control to all windows or specific window";
CM_ SG_ 176 CVC_Window_Control_Learning "Routine command for Anti-Pinch seft-learning";
CM_ SG_ 193 Ionizer_Set "Control the Ionizer ON/OFF";
CM_ SG_ 193 RecirculationFlap_Set "Control the DC-actuator for recirculation flap position change from 0 - 100%";
CM_ SG_ 193 AirDistributionMode_Set "Control the Air Distributor motor/flap";
CM_ SG_ 193 RHTempFlap_Set "Control Temperature Flap (right-hand flap)";
CM_ SG_ 193 LHTempFlap_Set "Control Temperature Flap (left-hand flap)";
CM_ SG_ 193 FrontBlowerRelay_Set "Control the Blower relay";
CM_ SG_ 193 AirDistributionModeLH_Set "Mode Flap LH Target Position";
CM_ SG_ 193 AirDistributionModeRH_Set "Mode Flap RH Target Position";
CM_ SG_ 193 BypassFlap_Set "Bypass Flap Target Position";
CM_ SG_ 193 AirDistributionModeRear_Set "Rear Mode Flap Target Position";
CM_ SG_ 196 CVC_CoolingFan_OnOff_Req "request to ON/OFF Cooling FAN relay";
CM_ SG_ 196 CVC_FEDSPump_OnOff_Req "Front EDS Pump On/Off Request";
CM_ SG_ 196 CVC_BMSPump_OnOff_Req "BMS Pump On/Off Request";
CM_ SG_ 196 CVC_REDSPump_OnOff_Req "Rear EDS Pump On/Off Request";
CM_ SG_ 196 CVC_HVMainRelay_OnOff_Req "request to ON/OFF water pump 4 relay";
CM_ SG_ 197 CVC_BatteryChillerSOV_Req "request to ON/OFF the Battery Chiller SOV";
CM_ SG_ 197 CVC_EvapSOV_Req "request to ON/OFF the Evap SOV";
CM_ SG_ 197 CVC_CoolingFan_PWM_Req "request to control the Cooling Fan";
CM_ SG_ 197 CVC_FEDSPump_PWM_Req "Front EDS Pump PWM Request";
CM_ SG_ 197 CVC_BMSPump_PWM_Req "BMS Pump PWM Request";
CM_ SG_ 197 CVC_REDSPump_PWM_Req "Rear EDS Pump PWM Request";
CM_ SG_ 197 CVC_WaterPump4_PWM_Req "request control water pump speed";
CM_ SG_ 197 CVC_EvapSOV2_Req "Rear HVAC SOV On/Off request";
CM_ SG_ 201 CRC_FMCU_Status "Checksum of this message";
CM_ SG_ 201 ALIVE_FMCU_Status "Signal counting the times of this message";
CM_ SG_ 201 FMCU_MotorTq "Front Motor torque";
CM_ SG_ 201 FMCU_MotorSpd "Front Motor rotating speed";
CM_ SG_ 201 FMCU_StsMCUFault "FMCU Fault Status";
CM_ SG_ 201 FMCU_MotorSpdSts "Front Motor rotating speed Invalid";
CM_ SG_ 201 FMCU_MotorTqSts "Front Motor torque Invalid";
CM_ SG_ 201 FMCU_CVC_CtrlMode "FMCU control mode";
CM_ SG_ 201 FMCU_CVC_StsMode "FMCU Operating Mode";
CM_ SG_ 202 CRC_CVC_DoorSetting_Feedback "checksum";
CM_ SG_ 202 ALIVE_CVC_DoorSetting_Feedback "counter";
CM_ SG_ 202 CVC_STAT_UserSettingAutoUnlock "User settings for automatic unlocking feedback";
CM_ SG_ 202 CVC_STAT_DoorSpdSensingLock "Feedback on door speed sensing lock setting";
CM_ SG_ 202 CVC_STAT_RemoteLockFeedback "Remote locking feedback";
CM_ SG_ 202 CVC_STAT_DoorUnlockOption "Door unlock status feedback";
CM_ SG_ 203 CRC_RMCU_Status "Checksum of this message";
CM_ SG_ 203 ALIVE_RMCU_Status "Signal counting the times of this message";
CM_ SG_ 203 RMCU_MotorTq "Rear Motor torque";
CM_ SG_ 203 RMCU_MotorSpd "Rear Motor rotating speed";
CM_ SG_ 203 RMCU_StsMCUFault "RMCU Fault Status";
CM_ SG_ 203 RMCU_MotorSpdValid "Rear Motor rotating speed Invalid";
CM_ SG_ 203 RMCU_MotorTqValid "Rear Motor torque Invalid";
CM_ SG_ 203 RMCU_CVC_CtrlMode "RMCU control mode";
CM_ SG_ 203 RMCU_CVC_StsMode "RMCU Operating Mode";
CM_ SG_ 210 CRC_CVC_BCM_Control_Request "Checksum";
CM_ SG_ 210 ALIVE_CVC_BCM_Control_Request "Alive counter";
CM_ SG_ 210 DriverSideDoor_Lock_Req "Left front door lock request";
CM_ SG_ 210 CoDriverSideDoor_Lock_Req "Right front door lock request";
CM_ SG_ 210 Bonnet_Lock_Req "Engine hood lock request";
CM_ SG_ 210 Tailgate_Lock_Req "Tailgate lock request";
CM_ SG_ 210 Fuel_Port_Lock_Req "Fuel Filler Flap Lock request";
CM_ SG_ 210 CVC_TPMS_Control_LearningStart "Request to start learning process";
CM_ SG_ 210 KeyFOBSearch_Req "Request Key FOB searching to find valid key FOB is outside";
CM_ SG_ 210 HornRequest "Horn request by user";
CM_ SG_ 210 CVC_SET_FCAMHeated_Req "front windshield Heat";
CM_ SG_ 210 CVC_SteeringWheel_Req "CVC_SteeringWheel_Req";
CM_ SG_ 210 CentralLockLightRequest "Central Locking Light Request";
CM_ SG_ 210 CVC_B_PowerOutlet_Req "control power outlet";
CM_ SG_ 217 CRC_CVC_HV_DrvSys_status "Checksum";
CM_ SG_ 217 ALIVE_CVC_HV_DrvSys_status "Alive counter";
CM_ SG_ 217 CVC_HVsystem_status "High Voltage system status";
CM_ SG_ 217 CVC_ACPD_Percent "The signal contains the actual angle of the acceleration pedal100% acceleration pedal position shall only provided in case of kick down.Without kickdown the maximum value shall be 99.";
CM_ SG_ 217 CVC_ACPD_Percent_Valid "Qualifier for corresponding signal.  In value table not defined values are reserved";
CM_ SG_ 217 CVC_ACTGear "actual gear,Provide gear shift signal";
CM_ SG_ 217 CVC_ACTGearValid "Indicate the current gear position";
CM_ SG_ 217 CVC_ACT_DriveMode "Vehicle drive mode";
CM_ SG_ 217 CVC_ACT_DriveMode_Valid "Vehicle drive mode status";
CM_ SG_ 217 CVC_HV_DRVsystem_status "Status of driving system ( Highvoltage )";
CM_ SG_ 217 CVC_Recu_BrakeLight_ON_Req "CVC request brake light ON when regen";
CM_ SG_ 256 CRC_CVC_B_Vehicle_Info "Checksum";
CM_ SG_ 256 ALIVE_CVC_B_Vehicle_Info "Alive Counter";
CM_ SG_ 256 CVC_B_UserProfileId "User profile ID, support 10 user profiles in maxinum, 0xF is invalid signal";
CM_ SG_ 256 CVC_B_Connectivity_Status "Internet Connection Connectivity Status";
CM_ SG_ 258 CRC_CVC_LOGICAL_CLAMP "Checksum";
CM_ SG_ 258 ALIVE_CVC_LOGICAL_CLAMP "Alive counter";
CM_ SG_ 258 STAT_CrankRelayHW_BCM "Represents the status of the starter relais";
CM_ SG_ 258 CVC_Transport_Mode "Transport mode shall be enable during storage or transportation with long-distance travel.";
CM_ SG_ 258 CVC_Vehicle_Special_Mode "Accessory mode of the vehicle";
CM_ SG_ 258 CVC_Acc_Mode_Req "Request vehicle into ACC state to activate HV on in some special mode/function of vehicle";
CM_ SG_ 258 CVC_CL30s_Req "Request to control ON/OFF CL30s relay";
CM_ SG_ 258 CVC_CL30c_Req "Request to control ON/OFF CL30c relay";
CM_ SG_ 258 CVC_CLR_Req "Request to control ON/OFF CLR relay";
CM_ SG_ 258 CVC_CL15_Req "Request to control ON/OFF CL15 relay";
CM_ SG_ 258 Warning_Clamp_Incompatible "Send alert to CAN in case of clamp status not the same as request";
CM_ SG_ 258 CVC_CL58_Req "Request to control ON/OFF CL58 relay";
CM_ SG_ 264 CRC_SS_DriveReq_0x108 "Check sum";
CM_ SG_ 264 ALIVE_SS_DriveReq_0x108 "Rolling Counter";
CM_ SG_ 264 SS_P_Button "The button for the P (parking) gear position";
CM_ SG_ 264 SS_TargetGearReq "Target gear request";
CM_ SG_ 264 SS_ADAS_Req "ADAS request";
CM_ SG_ 264 SS_DrvMd_RgnLvl_Req "Driving mode request";
CM_ SG_ 264 SS_Fault "Fault status";
CM_ SG_ 264 SS_HighBeam_Req "High beam Control Request";
CM_ SG_ 264 SS_Lane_Change_Indicator_Req "Lane Change Indicator Request";
CM_ SG_ 264 SS_FR_RR_WashAndMist_Req "Front and Rear Washer and Mist function control request";
CM_ SG_ 264 SS_RR_WiperControl_Req "Rear Wiper Control Request";
CM_ SG_ 264 SS_FR_Wipercontrol_Req "Front Wiper control Request";
BA_DEF_ BO_  "DiagRequest" ENUM  "No","Yes";
BA_DEF_ BO_  "DiagResponse" ENUM  "No","Yes";
BA_DEF_ BO_  "DiagState" ENUM  "No","Yes";
BA_DEF_ BO_  "GenMsgCycleTime" INT 0 65535;
BA_DEF_ BO_  "GenMsgCycleTimeFast" INT 0 65535;
BA_DEF_ BO_  "GenMsgDelayTime" INT 0 65535;
BA_DEF_ BO_  "GenMsgILSupport" ENUM  "No","Yes";
BA_DEF_ BO_  "GenMsgNrOfRepetition" INT 0 65535;
BA_DEF_ BO_  "GenMsgSendType" ENUM  "Cyclic","NoMsgSendType","NotUsed","NotUsed","NotUsed","NotUsed","NotUsed","IfActive","NoMsgSendType","NotUsed";
BA_DEF_ BO_  "NmAsrMessage" ENUM  "No","Yes";
BA_DEF_ BO_  "NmMessage" ENUM  "No","Yes";
BA_DEF_ SG_  "GenSigSendType" ENUM  "Cyclic","NoSigSendType","OnWriteWithRepetition","OnChange","OnChangeWithRepetition","IfActive","IfActiveWithRepetition","OnWrite","NotUsed","NotUsed","NotUsed","NotUsed","NotUsed";
BA_DEF_ SG_  "GenSigStartValue" INT 0 2147483647;
BA_DEF_ SG_  "GenSigTimeoutTime_ALL" INT 0 65535;
BA_DEF_ SG_  "InvalidValue" STRING ;
BA_DEF_ SG_  "GenSigInactiveValue" INT 0 2147483647;
BA_DEF_ BU_  "ILUsed" ENUM  "No","Yes";
BA_DEF_ BU_  "NmStationAddress" HEX 0 0;
BA_DEF_ BU_  "Address" HEX 0 255;
BA_DEF_ BU_  "NmAsrCanMsgReducedTime" INT 320 640;
BA_DEF_ BU_  "NmAsrNode" ENUM  "No","Yes";
BA_DEF_ BU_  "NmAsrNodeIdentifier" HEX 0 255;
BA_DEF_ BU_  "TpSTMin" INT 0 255;
BA_DEF_  "Baudrate" INT 1000 1000000;
BA_DEF_  "BaudRateCANFD" FLOAT 1000 10000000;
BA_DEF_ BO_  "VFrameFormat" ENUM  "StandardCAN","ExtendedCAN","reserved","J1939PG","reserved","reserved","reserved","reserved","reserved","reserved","reserved","reserved","reserved","reserved","StandardCAN_FD","ExtendedCAN_FD";
BA_DEF_ BO_  "CANFD_BRS" ENUM  "0","1";
BA_DEF_  "DBName" STRING ;
BA_DEF_  "BusType" STRING ;
BA_DEF_  "Manufacturer" STRING ;
BA_DEF_  "NmAsrBaseAddress" HEX 0 2047;
BA_DEF_  "NmAsrCanMsgCycleTime" INT 0 65535;
BA_DEF_  "NmAsrMessageCount" INT 1 256;
BA_DEF_  "NmAsrRepeatMessageTime" INT 0 65535;
BA_DEF_  "NmAsrTimeoutTime" INT 0 65535;
BA_DEF_  "NmAsrWaitBusSleepTime" INT 0 65535;
BA_DEF_  "NmType" STRING ;
BA_DEF_ SG_  "SystemSignalLongSymbol" STRING ;
BA_DEF_DEF_  "DiagRequest" "No";
BA_DEF_DEF_  "DiagResponse" "No";
BA_DEF_DEF_  "DiagState" "No";
BA_DEF_DEF_  "GenMsgCycleTime" 0;
BA_DEF_DEF_  "GenMsgCycleTimeFast" 0;
BA_DEF_DEF_  "GenMsgDelayTime" 0;
BA_DEF_DEF_  "GenMsgILSupport" "Yes";
BA_DEF_DEF_  "GenMsgNrOfRepetition" 0;
BA_DEF_DEF_  "GenMsgSendType" "Cyclic";
BA_DEF_DEF_  "NmAsrMessage" "No";
BA_DEF_DEF_  "NmMessage" "No";
BA_DEF_DEF_  "GenSigSendType" "Cyclic";
BA_DEF_DEF_  "GenSigStartValue" 0;
BA_DEF_DEF_  "GenSigTimeoutTime_ALL" 0;
BA_DEF_DEF_  "InvalidValue" "";
BA_DEF_DEF_  "GenSigInactiveValue" 0;
BA_DEF_DEF_  "ILUsed" "Yes";
BA_DEF_DEF_  "NmStationAddress" 0;
BA_DEF_DEF_  "Address" 0;
BA_DEF_DEF_  "NmAsrCanMsgReducedTime" 320;
BA_DEF_DEF_  "NmAsrNode" "No";
BA_DEF_DEF_  "NmAsrNodeIdentifier" 0;
BA_DEF_DEF_  "TpSTMin" 20;
BA_DEF_DEF_  "Baudrate" 500000;
BA_DEF_DEF_  "BaudRateCANFD" 2000000;
BA_DEF_DEF_  "VFrameFormat" "StandardCAN_FD";
BA_DEF_DEF_  "CANFD_BRS" "1";
BA_DEF_DEF_  "DBName" "";
BA_DEF_DEF_  "BusType" "";
BA_DEF_DEF_  "Manufacturer" "LaunchDesign";
BA_DEF_DEF_  "NmAsrBaseAddress" 1280;
BA_DEF_DEF_  "NmAsrCanMsgCycleTime" 640;
BA_DEF_DEF_  "NmAsrMessageCount" 128;
BA_DEF_DEF_  "NmAsrRepeatMessageTime" 3200;
BA_DEF_DEF_  "NmAsrTimeoutTime" 2000;
BA_DEF_DEF_  "NmAsrWaitBusSleepTime" 1500;
BA_DEF_DEF_  "NmType" "NmAsr";
BA_DEF_DEF_  "SystemSignalLongSymbol" "";
BA_ "Manufacturer" "VinFast";
BA_ "BusType" "CAN FD";
BA_ "DBName" "BCAN";
BA_ "NmStationAddress" BU_ CVC_B 2;
BA_ "Address" BU_ CVC_B 2;
BA_ "NmAsrNodeIdentifier" BU_ CVC_B 2;
BA_ "NmAsrNode" BU_ CVC_B 1;
BA_ "NmStationAddress" BU_ BCM_FL 1;
BA_ "Address" BU_ BCM_FL 1;
BA_ "NmAsrNodeIdentifier" BU_ BCM_FL 1;
BA_ "NmAsrNode" BU_ BCM_FL 1;
BA_ "NmStationAddress" BU_ BCM_FR 6;
BA_ "Address" BU_ BCM_FR 6;
BA_ "NmAsrNodeIdentifier" BU_ BCM_FR 6;
BA_ "NmAsrNode" BU_ BCM_FR 1;
BA_ "NmStationAddress" BU_ DKCU 76;
BA_ "Address" BU_ DKCU 76;
BA_ "NmAsrNodeIdentifier" BU_ DKCU 76;
BA_ "NmAsrNode" BU_ DKCU 1;
BA_ "NmStationAddress" BU_ BCM_R 7;
BA_ "Address" BU_ BCM_R 7;
BA_ "NmAsrNodeIdentifier" BU_ BCM_R 7;
BA_ "NmAsrNode" BU_ BCM_R 1;
BA_ "GenMsgCycleTime" BO_ 165 100;
BA_ "GenMsgCycleTime" BO_ 169 100;
BA_ "GenMsgCycleTime" BO_ 170 20;
BA_ "GenMsgCycleTime" BO_ 178 100;
BA_ "GenMsgCycleTime" BO_ 180 100;
BA_ "GenMsgCycleTime" BO_ 198 100;
BA_ "GenMsgCycleTime" BO_ 199 100;
BA_ "GenMsgCycleTime" BO_ 252 100;
BA_ "GenMsgCycleTime" BO_ 260 100;
BA_ "GenMsgCycleTime" BO_ 266 100;
BA_ "GenMsgSendType" BO_ 277 1;
BA_ "GenMsgCycleTime" BO_ 280 500;
BA_ "GenMsgCycleTime" BO_ 529 100;
BA_ "GenMsgCycleTimeFast" BO_ 529 10;
BA_ "GenMsgNrOfRepetition" BO_ 529 3;
BA_ "GenMsgCycleTime" BO_ 532 100;
BA_ "GenMsgCycleTime" BO_ 561 20;
BA_ "GenMsgCycleTime" BO_ 805 100;
BA_ "GenMsgSendType" BO_ 1049 1;
BA_ "GenMsgCycleTime" BO_ 1065 100;
BA_ "GenMsgCycleTime" BO_ 1071 100;
BA_ "GenMsgSendType" BO_ 1111 1;
BA_ "GenMsgCycleTime" BO_ 1118 100;
BA_ "GenMsgCycleTime" BO_ 1153 50;
BA_ "GenMsgCycleTime" BO_ 1217 1000;
BA_ "GenMsgSendType" BO_ 1860 1;
BA_ "GenMsgCycleTimeFast" BO_ 1973 50;
BA_ "GenMsgNrOfRepetition" BO_ 1973 2;
BA_ "GenMsgSendType" BO_ 1973 1;
BA_ "GenMsgCycleTime" BO_ 160 100;
BA_ "GenMsgCycleTime" BO_ 171 20;
BA_ "GenMsgCycleTime" BO_ 177 100;
BA_ "GenMsgCycleTime" BO_ 181 100;
BA_ "GenMsgCycleTime" BO_ 194 100;
BA_ "GenMsgCycleTime" BO_ 195 100;
BA_ "GenMsgSendType" BO_ 200 1;
BA_ "GenMsgCycleTime" BO_ 204 100;
BA_ "GenMsgCycleTime" BO_ 251 100;
BA_ "GenMsgCycleTime" BO_ 279 100;
BA_ "GenMsgCycleTime" BO_ 286 100;
BA_ "GenMsgCycleTime" BO_ 530 100;
BA_ "GenMsgCycleTimeFast" BO_ 530 10;
BA_ "GenMsgNrOfRepetition" BO_ 530 3;
BA_ "GenMsgCycleTime" BO_ 534 100;
BA_ "GenMsgCycleTime" BO_ 584 20;
BA_ "GenMsgCycleTime" BO_ 809 1000;
BA_ "GenMsgCycleTime" BO_ 896 1000;
BA_ "GenMsgSendType" BO_ 920 1;
BA_ "GenMsgSendType" BO_ 923 1;
BA_ "GenMsgSendType" BO_ 1051 1;
BA_ "GenMsgCycleTime" BO_ 1072 100;
BA_ "GenMsgCycleTime" BO_ 1076 100;
BA_ "GenMsgCycleTime" BO_ 1151 50;
BA_ "GenMsgCycleTime" BO_ 1155 50;
BA_ "GenMsgCycleTime" BO_ 1158 50;
BA_ "GenMsgSendType" BO_ 1169 1;
BA_ "GenMsgCycleTime" BO_ 1220 1000;
BA_ "GenMsgCycleTime" BO_ 1241 50;
BA_ "GenMsgSendType" BO_ 1859 1;
BA_ "GenMsgCycleTimeFast" BO_ 1972 50;
BA_ "GenMsgNrOfRepetition" BO_ 1972 2;
BA_ "GenMsgSendType" BO_ 1972 1;
BA_ "GenMsgCycleTime" BO_ 133 20;
BA_ "GenMsgCycleTime" BO_ 162 100;
BA_ "GenMsgCycleTime" BO_ 176 100;
BA_ "GenMsgSendType" BO_ 193 1;
BA_ "GenMsgCycleTime" BO_ 196 100;
BA_ "GenMsgCycleTime" BO_ 197 100;
BA_ "GenMsgCycleTime" BO_ 201 10;
BA_ "GenMsgCycleTime" BO_ 202 100;
BA_ "GenMsgCycleTime" BO_ 203 10;
BA_ "GenMsgCycleTime" BO_ 210 100;
BA_ "GenMsgCycleTime" BO_ 217 20;
BA_ "GenMsgCycleTime" BO_ 256 1000;
BA_ "GenMsgCycleTime" BO_ 258 100;
BA_ "GenMsgCycleTime" BO_ 264 50;
BA_ "InvalidValue" SG_ 165 BCM_DSB_WindowBtnPress_FL "7h";
BA_ "InvalidValue" SG_ 165 BCM_DSB_WindowBtnPress_FR "7h";
BA_ "InvalidValue" SG_ 165 BCM_DSB_WindowBtnPress_RL "7h";
BA_ "InvalidValue" SG_ 165 BCM_DSB_WindowBtnPress_RR "7h";
BA_ "InvalidValue" SG_ 165 BCM_DSB_DoorLockBtnPress "3h";
BA_ "InvalidValue" SG_ 169 ALIVE_BCMFL_Temperature "Fh";
BA_ "InvalidValue" SG_ 169 BCMFL_AmbientTemp "FFh";
BA_ "InvalidValue" SG_ 169 BCMFL_CabinHeat_TempSensor "FFh";
BA_ "InvalidValue" SG_ 169 BCMFL_AmbientTempSts "3h";
BA_ "InvalidValue" SG_ 169 BCMFL_CoolantTemp_EDS_In_Sts "3h";
BA_ "InvalidValue" SG_ 169 BCMFL_CoolantTemp_EDS_Out_Sts "3h";
BA_ "InvalidValue" SG_ 169 BCMFL_CoolantTemp_LTR_Out_Sts "3h";
BA_ "InvalidValue" SG_ 169 BCMFL_ACLowSideTemperatureSts "3h";
BA_ "InvalidValue" SG_ 169 BCMFL_ACLowSidePressureSts "3h";
BA_ "InvalidValue" SG_ 169 BCMFL_ACHighSideTemperatureSts "3h";
BA_ "InvalidValue" SG_ 169 BCMFL_ACHighSidePressureSts "3h";
BA_ "InvalidValue" SG_ 169 BCMFL_CoolantTemp_HtrCore_In_Sts "3h";
BA_ "InvalidValue" SG_ 169 BCMFL_Refrigerant_Temp_Sensor_St "3h";
BA_ "SystemSignalLongSymbol" SG_ 169 BCMFL_Refrigerant_Temp_Sensor_St "BCMFL_Refrigerant_Temp_Sensor_Sts";
BA_ "InvalidValue" SG_ 169 BCMFL_PT_Sensor1_Pressure_Sts "3h";
BA_ "InvalidValue" SG_ 169 BCMFL_PT_Sensor2_Pressure_Sts "3h";
BA_ "InvalidValue" SG_ 170 ALIVE_BCMFL_DoorStatus "Fh";
BA_ "InvalidValue" SG_ 170 BonnetLockStatus "3h";
BA_ "InvalidValue" SG_ 170 DriverDoor_Lock_Sts "3h";
BA_ "GenSigStartValue" SG_ 170 DriverDoor_Lock_Sts 3;
BA_ "InvalidValue" SG_ 170 DriverDoor_Ajar_Sts "3h";
BA_ "InvalidValue" SG_ 170 BonnetAjarStatus "3h";
BA_ "InvalidValue" SG_ 170 RLDoor_Lock_Sts "3h";
BA_ "GenSigStartValue" SG_ 170 RLDoor_Lock_Sts 3;
BA_ "InvalidValue" SG_ 170 RLDoor_Ajar_Sts "3h";
BA_ "InvalidValue" SG_ 178 MechanicalLockReq "4h";
BA_ "GenSigStartValue" SG_ 178 MechanicalLockReq 2;
BA_ "InvalidValue" SG_ 178 FootKickOperation_Request "3h";
BA_ "InvalidValue" SG_ 180 ALIVE_BCM_WindowsFL_Status "Fh";
BA_ "InvalidValue" SG_ 180 Window_Position_FL "Fh";
BA_ "InvalidValue" SG_ 180 Window_Position_RL "Fh";
BA_ "SystemSignalLongSymbol" SG_ 198 CRC_BCMFL_ThermalComponents_Stat "CRC_BCMFL_ThermalComponents_Status_1";
BA_ "InvalidValue" SG_ 198 ALIVE_BCMFL_ThermalComponents_St "Fh";
BA_ "SystemSignalLongSymbol" SG_ 198 ALIVE_BCMFL_ThermalComponents_St "ALIVE_BCMFL_ThermalComponents_Status_1";
BA_ "InvalidValue" SG_ 198 BCMFL_CoolantLevel "3h";
BA_ "GenSigStartValue" SG_ 198 BCMFL_CoolantTemp_LTR_Out 40;
BA_ "GenSigStartValue" SG_ 198 BCMFL_CoolantTemp_EDS_In 40;
BA_ "GenSigStartValue" SG_ 198 BCMFL_CoolantTemp_EDS_Out 40;
BA_ "GenSigStartValue" SG_ 198 BCMFL_ACLowSideTemperature 400;
BA_ "GenSigStartValue" SG_ 198 BCMFL_ACHighSideTemperature 400;
BA_ "GenSigStartValue" SG_ 198 BCMFL_CoolantTemp_HtrCore_In 40;
BA_ "InvalidValue" SG_ 198 BCMFL_FEDSPump_Fault "7h";
BA_ "InvalidValue" SG_ 198 BCMFL_BMSPump_Fault "7h";
BA_ "InvalidValue" SG_ 198 BCMFL_SOV_Fault "3h";
BA_ "InvalidValue" SG_ 198 BCMFL_CoolingFan_Fault "7h";
BA_ "InvalidValue" SG_ 198 BCMFL_CoolantLevel2 "3h";
BA_ "InvalidValue" SG_ 198 BCMFL_RearACLowSidePressureSts "3h";
BA_ "InvalidValue" SG_ 198 BCMFL_RearACLowSideTemperatureSt "3h";
BA_ "SystemSignalLongSymbol" SG_ 198 BCMFL_RearACLowSideTemperatureSt "BCMFL_RearACLowSideTemperatureSts";
BA_ "InvalidValue" SG_ 198 BCMFL_REDSPump_Fault "7h";
BA_ "GenSigStartValue" SG_ 198 BCMFL_RearACLowSideTemperature 400;
BA_ "SystemSignalLongSymbol" SG_ 199 CRC_BCMFL_ThermalComponents_0000 "CRC_BCMFL_ThermalComponents_Status_2";
BA_ "InvalidValue" SG_ 199 ALIVE_BCMFL_ThermalComponen_0000 "Fh";
BA_ "SystemSignalLongSymbol" SG_ 199 ALIVE_BCMFL_ThermalComponen_0000 "ALIVE_BCMFL_ThermalComponents_Status_2";
BA_ "InvalidValue" SG_ 252 ALIVE_BCMFL_STAT_Control "Fh";
BA_ "InvalidValue" SG_ 252 BCMFL_STAT_FrontWiperServiceMode "3h";
BA_ "InvalidValue" SG_ 252 BCMFL_FrontWiperStepTimeStatus "FFh";
BA_ "InvalidValue" SG_ 252 BCM_Fr_Rr_WashAndMist_Status "7h";
BA_ "InvalidValue" SG_ 252 BCMFL_InteriorTemperature "FFh";
BA_ "GenSigStartValue" SG_ 252 BCMFL_InteriorTemperature 40;
BA_ "InvalidValue" SG_ 252 WakeupForTopup_Req "3h";
BA_ "InvalidValue" SG_ 252 BCMFL_InteriorTemperatureSts "3h";
BA_ "InvalidValue" SG_ 252 BCM_FL_STAT_RearHeatedWindowMirr "3h";
BA_ "SystemSignalLongSymbol" SG_ 252 BCM_FL_STAT_RearHeatedWindowMirr "BCM_FL_STAT_RearHeatedWindowMirror";
BA_ "InvalidValue" SG_ 252 BCMFL_STAT_Horn "3h";
BA_ "InvalidValue" SG_ 252 BCMFL_PowerOutlet_Sts "3h";
BA_ "InvalidValue" SG_ 260 ALIVE_BCM_FL_Measured_Data "Fh";
BA_ "InvalidValue" SG_ 260 SOH_SUL "FFh";
BA_ "GenSigStartValue" SG_ 260 SOH_SUL 100;
BA_ "InvalidValue" SG_ 260 SOH_SUL_STATE "3h";
BA_ "GenSigStartValue" SG_ 260 SOH_SUL_STATE 3;
BA_ "InvalidValue" SG_ 260 SOC_STATE "3h";
BA_ "GenSigStartValue" SG_ 260 SOC_STATE 3;
BA_ "InvalidValue" SG_ 266 ALIVE_BCM_VOLTAGE "Fh";
BA_ "InvalidValue" SG_ 266 LV_BatteryType "3h";
BA_ "GenSigStartValue" SG_ 266 UBatt 9205;
BA_ "GenSigStartValue" SG_ 266 LV_Batt_Temp_Reserved 40;
BA_ "GenSigStartValue" SG_ 266 LV_Batt_Current_Reserved 49152;
BA_ "InvalidValue" SG_ 277 BCM_ChildLock_Feedback "3h";
BA_ "GenSigSendType" SG_ 277 BCM_ChildLock_Feedback 1;
BA_ "InvalidValue" SG_ 280 ALIVE_BCM_MHU_Ctrl_Fbk "Fh";
BA_ "InvalidValue" SG_ 280 BCM_DrvInhibitStsFbk "3h";
BA_ "InvalidValue" SG_ 529 ALIVE_BCMFL_ExteriorLight_STS "Fh";
BA_ "InvalidValue" SG_ 529 BCM_LowBeam_FL_Sts "3h";
BA_ "GenSigSendType" SG_ 529 BCM_LowBeam_FL_Sts 2;
BA_ "InvalidValue" SG_ 529 BCM_HighBeam_FL_Sts "3h";
BA_ "GenSigSendType" SG_ 529 BCM_HighBeam_FL_Sts 2;
BA_ "InvalidValue" SG_ 529 BCM_TurnIndicator_FL_STS "3h";
BA_ "GenSigSendType" SG_ 529 BCM_TurnIndicator_FL_STS 2;
BA_ "InvalidValue" SG_ 529 BCM_PositionLight_FL_STS "3h";
BA_ "GenSigSendType" SG_ 529 BCM_PositionLight_FL_STS 2;
BA_ "InvalidValue" SG_ 529 BCM_RearFogLamp_FL_STS "3h";
BA_ "GenSigSendType" SG_ 529 BCM_RearFogLamp_FL_STS 2;
BA_ "GenSigSendType" SG_ 529 BCM_HeightSensorSTS_Front 2;
BA_ "GenSigSendType" SG_ 529 BCM_HeightSensorValue_Front 2;
BA_ "InvalidValue" SG_ 529 BCM_MirrorLED_FL_STS "3h";
BA_ "GenSigSendType" SG_ 529 BCM_MirrorLED_FL_STS 2;
BA_ "InvalidValue" SG_ 529 BCM_HazardButton_FL_STS "3h";
BA_ "GenSigSendType" SG_ 529 BCM_HazardButton_FL_STS 2;
BA_ "InvalidValue" SG_ 529 BCM_DaytimeRunningLight_FL_Sts "3h";
BA_ "GenSigSendType" SG_ 529 BCM_DaytimeRunningLight_FL_Sts 2;
BA_ "InvalidValue" SG_ 529 BCM_FrontFogLamp_FL_STS "3h";
BA_ "GenSigSendType" SG_ 529 BCM_FrontFogLamp_FL_STS 2;
BA_ "InvalidValue" SG_ 532 BCM_Mirror_CourtesyLightSts "3h";
BA_ "GenSigStartValue" SG_ 532 BCM_Mirror_CourtesyLightSts 2;
BA_ "InvalidValue" SG_ 532 BCM_FL_BonnetSts "3h";
BA_ "InvalidValue" SG_ 532 BCM_FL_BonnetLightSts "3h";
BA_ "InvalidValue" SG_ 532 BCM_FLFootwellLightSts "3h";
BA_ "InvalidValue" SG_ 532 BCM_FL_FrontDomeLampStatus "3h";
BA_ "InvalidValue" SG_ 532 BCM_FLScuffLightSts "3h";
BA_ "InvalidValue" SG_ 532 BCM_FLProjectorLightSts "3h";
BA_ "InvalidValue" SG_ 561 ALIVE_DoorFLStatus "Fh";
BA_ "InvalidValue" SG_ 561 DOW_DoorAjarStatusRL "3h";
BA_ "InvalidValue" SG_ 561 DOW_DoorAjarStatusFL "3h";
BA_ "GenSigStartValue" SG_ 805 BCMFL_STAT_SteerPosX 50;
BA_ "GenSigStartValue" SG_ 805 BCMFL_STAT_SteerPosY 50;
BA_ "GenSigStartValue" SG_ 805 Steering_Wheel_Telescope_Positio 20;
BA_ "SystemSignalLongSymbol" SG_ 805 Steering_Wheel_Telescope_Positio "Steering_Wheel_Telescope_Position_Status";
BA_ "SystemSignalLongSymbol" SG_ 805 Steering_Wheel_Convenience_Acces "Steering_Wheel_Convenience_Access";
BA_ "GenSigStartValue" SG_ 805 Steering_Wheel_Angle_Status 21;
BA_ "InvalidValue" SG_ 805 BCMFL_STS_SteerAdjust "3h";
BA_ "InvalidValue" SG_ 805 SWHC_SterringWheelHeatFaultReaso "1h";
BA_ "SystemSignalLongSymbol" SG_ 805 SWHC_SterringWheelHeatFaultReaso "SWHC_SterringWheelHeatFaultReason";
BA_ "InvalidValue" SG_ 1049 SHVU_STAT_SeatHeatingFrontL "4h";
BA_ "GenSigSendType" SG_ 1049 SHVU_STAT_SeatHeatingFrontL 1;
BA_ "InvalidValue" SG_ 1049 SHVU_STAT_SeatCoolingFrontL "4h";
BA_ "GenSigSendType" SG_ 1049 SHVU_STAT_SeatCoolingFrontL 1;
BA_ "InvalidValue" SG_ 1049 SHVU_STAT_FrontSeatVentSts "3h";
BA_ "GenSigSendType" SG_ 1049 SHVU_STAT_FrontSeatVentSts 1;
BA_ "InvalidValue" SG_ 1065 BCMFL_SeatRecliner_Sw "3h";
BA_ "InvalidValue" SG_ 1065 BCMFL_SeatTilt_Sw "3h";
BA_ "InvalidValue" SG_ 1065 BCMFL_SeatHeight_Sw "3h";
BA_ "InvalidValue" SG_ 1065 BCMFL_SeatTrack_Sw "3h";
BA_ "GenSigStartValue" SG_ 1065 BCMFL_SeatTrack_Pos 65;
BA_ "GenSigStartValue" SG_ 1065 BCMFL_SeatTilt_Pos 1;
BA_ "GenSigStartValue" SG_ 1065 BCMFL_SeatHeight_Pos 2;
BA_ "GenSigStartValue" SG_ 1065 BCMFL_SeatRecline_Pos 42;
BA_ "InvalidValue" SG_ 1065 BCMFL_SeatMassageLevel_Sts "7h";
BA_ "InvalidValue" SG_ 1065 BCMFL_SeatMassageMode_Sts "7h";
BA_ "InvalidValue" SG_ 1065 BCMFL_SeatControl_Sts "3h";
BA_ "InvalidValue" SG_ 1065 BCMFL_SeatVentilation_Sts "7h";
BA_ "InvalidValue" SG_ 1065 BCMFL_SeatHeating_Sts "7h";
BA_ "InvalidValue" SG_ 1065 BCMFL_FrontPsg_SeatTrack_Pos "3h";
BA_ "InvalidValue" SG_ 1071 BCMFL_STAT_LeftMirrorHeating "3h";
BA_ "InvalidValue" SG_ 1071 BCMFL_STAT_LeftMirrorFold "3h";
BA_ "InvalidValue" SG_ 1071 BCMFL_STAT_MirrorAdjustLeft "3h";
BA_ "GenSigSendType" SG_ 1111 AmbLight_Error_Z3 1;
BA_ "GenSigSendType" SG_ 1111 AmbLight_Linerror_Z3 1;
BA_ "GenSigSendType" SG_ 1111 AmbLight_Error_Z3B 1;
BA_ "GenSigSendType" SG_ 1111 AmbLight_Linerror_Z3B 1;
BA_ "GenSigTimeoutTime_ALL" SG_ 1118 CRC_BCM_Heater_Feedback 1000;
BA_ "InvalidValue" SG_ 1118 ALIVE_BCM_Heater_Feedback "Fh";
BA_ "GenSigTimeoutTime_ALL" SG_ 1118 ALIVE_BCM_Heater_Feedback 1000;
BA_ "InvalidValue" SG_ 1118 BCM_HeaterActivation_Feedback "0h";
BA_ "GenSigTimeoutTime_ALL" SG_ 1118 BCM_HeaterActivation_Feedback 1000;
BA_ "InvalidValue" SG_ 1153 ALIVE_BCM_FL_WarnMsg_FL "Fh";
BA_ "SystemSignalLongSymbol" SG_ 1153 BCM_FL_IDB_Brakelight_Malfunctio "BCM_FL_IDB_Brakelight_Malfunction";
BA_ "SystemSignalLongSymbol" SG_ 1153 BCM_FL_CVC_Brakelight_Malfunctio "BCM_FL_CVC_Brakelight_Malfunction";
BA_ "SystemSignalLongSymbol" SG_ 1153 BCM_FL_ADAS_Turnlight_Malfunctio "BCM_FL_ADAS_Turnlight_Malfunction";
BA_ "InvalidValue" SG_ 1217 ALIVE_APM_FL_WarnMsg "Fh";
BA_ "GenSigSendType" SG_ 1860 BCMFL_DebugSignal01 1;
BA_ "GenSigSendType" SG_ 1860 BCMFL_DebugSignal02 1;
BA_ "GenSigSendType" SG_ 1860 BCMFL_DebugSignal03 1;
BA_ "GenSigSendType" SG_ 1860 BCMFL_DebugSignal04 1;
BA_ "GenSigSendType" SG_ 1860 BCMFL_DebugSignal05 1;
BA_ "GenSigSendType" SG_ 1860 BCMFL_DebugSignal06 1;
BA_ "GenSigSendType" SG_ 1860 BCMFL_DebugSignal07 1;
BA_ "GenSigSendType" SG_ 1860 BCMFL_DebugSignal08 1;
BA_ "GenSigSendType" SG_ 1973 BCMFL_Req_RandomData 2;
BA_ "GenSigSendType" SG_ 1973 BCMFL_Req_MAC 2;
BA_ "InvalidValue" SG_ 160 ALIVE_BCMFR_KeyFOB_Status "Fh";
BA_ "InvalidValue" SG_ 160 KeyFOBAuthenStatus "Fh";
BA_ "InvalidValue" SG_ 160 KeyFOBPosition "Fh";
BA_ "InvalidValue" SG_ 160 FobId "3h";
BA_ "InvalidValue" SG_ 160 BCMFR_KeyIgnoringStatus "3h";
BA_ "InvalidValue" SG_ 160 KeyFOB_Authen_Process "3h";
BA_ "InvalidValue" SG_ 171 ALIVE_BCMFR_DoorStatus "Fh";
BA_ "InvalidValue" SG_ 171 CoDriverDoor_Ajar_Sts "3h";
BA_ "InvalidValue" SG_ 171 RRDoor_Ajar_Sts "3h";
BA_ "InvalidValue" SG_ 171 CoDriverDoor_Lock_Sts "3h";
BA_ "GenSigStartValue" SG_ 171 CoDriverDoor_Lock_Sts 3;
BA_ "InvalidValue" SG_ 171 RRDoor_Lock_Sts "3h";
BA_ "GenSigStartValue" SG_ 171 RRDoor_Lock_Sts 3;
BA_ "InvalidValue" SG_ 177 KeyFOB_Request "Fh";
BA_ "InvalidValue" SG_ 181 ALIVE_BCM_WindowsFR_Status "Fh";
BA_ "InvalidValue" SG_ 181 Window_Position_FR "Fh";
BA_ "InvalidValue" SG_ 181 Window_Position_RR "Fh";
BA_ "GenSigStartValue" SG_ 195 BCMFR_DuctTempRightFace 300;
BA_ "GenSigStartValue" SG_ 195 BCMFR_DuctTempLeftFace 300;
BA_ "GenSigStartValue" SG_ 195 BCMFR_DuctTempRightFoot 300;
BA_ "GenSigStartValue" SG_ 195 BCMFR_DuctTempLeftFoot 300;
BA_ "InvalidValue" SG_ 195 BCMFR_HumiditySts "3h";
BA_ "InvalidValue" SG_ 195 BCMFR_PM25Sts "3h";
BA_ "InvalidValue" SG_ 195 BCMFR_CO2Sts "3h";
BA_ "InvalidValue" SG_ 195 BCMFR_DucTempRightFaceSts "3h";
BA_ "InvalidValue" SG_ 195 BCMFR_DucTempLeftFaceSts "3h";
BA_ "InvalidValue" SG_ 195 BCMFR_DucTempRightFootSts "3h";
BA_ "InvalidValue" SG_ 195 BCMFR_DucTempLeftFootSts "3h";
BA_ "InvalidValue" SG_ 195 BCMFR_RearEvapTempSensorInputSts "3h";
BA_ "GenSigStartValue" SG_ 195 BCMFR_RearVentDuctTemp 300;
BA_ "GenSigStartValue" SG_ 195 BCMFR_RearFootDuctTemp 300;
BA_ "InvalidValue" SG_ 195 BCMFR_RearVentDuctTempSts "3h";
BA_ "InvalidValue" SG_ 195 BCMFR_RearFootDuctTempSts "3h";
BA_ "InvalidValue" SG_ 200 BCMFR_Climate_IonizerSts "3h";
BA_ "GenSigSendType" SG_ 200 BCMFR_Climate_IonizerSts 1;
BA_ "GenSigSendType" SG_ 200 BCMFR_Climate_AirDistFlapPos 1;
BA_ "GenSigSendType" SG_ 200 BCMFR_Climate_RHTempFlapPos 1;
BA_ "GenSigSendType" SG_ 200 BCMFR_Climate_LHTempFlapPos 1;
BA_ "GenSigSendType" SG_ 200 BCMFR_Climate_BlowerRelay 1;
BA_ "GenSigSendType" SG_ 200 BCMFR_Climate_BlowerStatus 1;
BA_ "GenSigSendType" SG_ 200 BCMFR_Climate_LHTempFlapSts 1;
BA_ "GenSigSendType" SG_ 200 BCMFR_Climate_RHTempFlapSts 1;
BA_ "GenSigSendType" SG_ 200 BCMFR_Climate_AirDistFlapSts 1;
BA_ "GenSigSendType" SG_ 200 BCMFR_Climate_AirRecirculationPo 1;
BA_ "GenSigSendType" SG_ 200 BCMFR_Climate_AirDistFlapLHPos 1;
BA_ "GenSigSendType" SG_ 200 BCMFR_Climate_AirDistFlapLHSts 1;
BA_ "GenSigSendType" SG_ 200 BCMFR_Climate_AirRecirSts 1;
BA_ "InvalidValue" SG_ 204 BCMFR_InteriorTempSts "3h";
BA_ "InvalidValue" SG_ 204 BCMFR_PTCTempInletSts "3h";
BA_ "InvalidValue" SG_ 204 BCMFR_PTCTempOutletLeSts "3h";
BA_ "InvalidValue" SG_ 204 BCMFR_PTCTempOutletRiSts "3h";
BA_ "InvalidValue" SG_ 204 BCMFR_EvapTempSensorInputSts "3h";
BA_ "InvalidValue" SG_ 251 RLSFailureFeedback "3h";
BA_ "InvalidValue" SG_ 251 BCMFR_Rear_Wiper_Park_Pos_Status "3h";
BA_ "InvalidValue" SG_ 251 BCMFR_STAT_RearWiperServiceMode "3h";
BA_ "InvalidValue" SG_ 251 CentralLockLightStatus "3h";
BA_ "GenSigStartValue" SG_ 279 BCM_Stat_SwitchLightBrightness 80;
BA_ "InvalidValue" SG_ 286 BCMFR_CL30s_FR_Sts "3h";
BA_ "InvalidValue" SG_ 286 BCMFR_CL30c_FR_Sts "3h";
BA_ "InvalidValue" SG_ 286 BCMFR_CLR_FR_Sts "3h";
BA_ "InvalidValue" SG_ 286 BCMFR_CL15_FR_Sts "3h";
BA_ "InvalidValue" SG_ 286 BCMFR_CL58_FR_Sts "3h";
BA_ "InvalidValue" SG_ 530 ALIVE_BCMFR_ExteriorLight_STS "Fh";
BA_ "InvalidValue" SG_ 530 BCM_SideMarkerSts "3h";
BA_ "InvalidValue" SG_ 530 BCM_TurnIndicator_FR_STS "3h";
BA_ "GenSigSendType" SG_ 530 BCM_TurnIndicator_FR_STS 2;
BA_ "InvalidValue" SG_ 530 BCM_PositionLight_FR_STS "3h";
BA_ "GenSigSendType" SG_ 530 BCM_PositionLight_FR_STS 2;
BA_ "InvalidValue" SG_ 530 BCM_FrontFogLamp_FR_STS "3h";
BA_ "GenSigSendType" SG_ 530 BCM_FrontFogLamp_FR_STS 2;
BA_ "InvalidValue" SG_ 530 BCM_DaytimeRunningLight_FR_Sts "3h";
BA_ "GenSigSendType" SG_ 530 BCM_DaytimeRunningLight_FR_Sts 2;
BA_ "InvalidValue" SG_ 530 BCM_MirrorLED_FR_STS "3h";
BA_ "GenSigSendType" SG_ 530 BCM_MirrorLED_FR_STS 2;
BA_ "InvalidValue" SG_ 530 BCM_LowBeam_FR_Sts "3h";
BA_ "GenSigSendType" SG_ 530 BCM_LowBeam_FR_Sts 2;
BA_ "InvalidValue" SG_ 530 BCM_HighBeam_FR_Sts "3h";
BA_ "GenSigSendType" SG_ 530 BCM_HighBeam_FR_Sts 2;
BA_ "InvalidValue" SG_ 534 BCM_FRDoorCourtesyLightSts_Reser "3h";
BA_ "GenSigStartValue" SG_ 534 BCM_FRDoorCourtesyLightSts_Reser 2;
BA_ "SystemSignalLongSymbol" SG_ 534 BCM_FRDoorCourtesyLightSts_Reser "BCM_FRDoorCourtesyLightSts_Reserved";
BA_ "InvalidValue" SG_ 534 BCM_FRFootwellLightSts "3h";
BA_ "InvalidValue" SG_ 534 BCM_FRScuffLightSts "3h";
BA_ "InvalidValue" SG_ 534 BCM_FRProjectorLightSts "3h";
BA_ "InvalidValue" SG_ 534 BCM_FR_Rear_2nd_DomeLampSts "3h";
BA_ "GenSigStartValue" SG_ 534 BCM_FR_Switch_Light_Brightness_S 50;
BA_ "SystemSignalLongSymbol" SG_ 534 BCM_FR_Switch_Light_Brightness_S "BCM_FR_Switch_Light_Brightness_Status";
BA_ "InvalidValue" SG_ 584 ALIVE_DoorFRStatus "Fh";
BA_ "InvalidValue" SG_ 584 DOW_DoorAjarStatusRR "3h";
BA_ "InvalidValue" SG_ 584 DOW_DoorAjarStatusFR "3h";
BA_ "InvalidValue" SG_ 809 ALIVE_BCM_ODO "Fh";
BA_ "GenSigSendType" SG_ 920 BCM_Immo_Byte_0 1;
BA_ "GenSigSendType" SG_ 920 BCM_Immo_Byte_1 1;
BA_ "GenSigSendType" SG_ 920 BCM_Immo_Byte_2 1;
BA_ "GenSigSendType" SG_ 920 BCM_Immo_Byte_3 1;
BA_ "GenSigSendType" SG_ 920 BCM_Immo_Byte_4 1;
BA_ "GenSigSendType" SG_ 920 BCM_Immo_Byte_5 1;
BA_ "GenSigSendType" SG_ 920 BCM_Immo_Byte_6 1;
BA_ "GenSigSendType" SG_ 920 BCM_Immo_Byte_7 1;
BA_ "GenSigSendType" SG_ 923 BCM_Immo_CVC_B_Byte_0 1;
BA_ "GenSigSendType" SG_ 923 BCM_Immo_CVC_B_Byte_1 1;
BA_ "GenSigSendType" SG_ 923 BCM_Immo_CVC_B_Byte_2 1;
BA_ "GenSigSendType" SG_ 923 BCM_Immo_CVC_B_Byte_3 1;
BA_ "GenSigSendType" SG_ 923 BCM_Immo_CVC_B_Byte_4 1;
BA_ "GenSigSendType" SG_ 923 BCM_Immo_CVC_B_Byte_5 1;
BA_ "GenSigSendType" SG_ 923 BCM_Immo_CVC_B_Byte_6 1;
BA_ "GenSigSendType" SG_ 923 BCM_Immo_CVC_B_Byte_7 1;
BA_ "InvalidValue" SG_ 1051 SHVU_STAT_SeatHeatingFrontR "4h";
BA_ "GenSigSendType" SG_ 1051 SHVU_STAT_SeatHeatingFrontR 1;
BA_ "InvalidValue" SG_ 1051 SHVU_STAT_SeatCoolingFrontR "4h";
BA_ "GenSigSendType" SG_ 1051 SHVU_STAT_SeatCoolingFrontR 1;
BA_ "InvalidValue" SG_ 1051 SHVU_STAT_FrontSeatVentSts "3h";
BA_ "GenSigSendType" SG_ 1051 SHVU_STAT_FrontSeatVentSts 1;
BA_ "InvalidValue" SG_ 1072 BCMFR_STAT_RightMirrorHeating "3h";
BA_ "InvalidValue" SG_ 1072 BCMFR_STAT_RightMirrorFold "3h";
BA_ "InvalidValue" SG_ 1072 BCMFR_STAT_MirrorAdjustRight "3h";
BA_ "InvalidValue" SG_ 1076 BCMFR_SeatMassageLevel_Sts "7h";
BA_ "InvalidValue" SG_ 1076 BCMFR_SeatMassageMode_Sts "7h";
BA_ "InvalidValue" SG_ 1076 BCMFR_SeatTrack_Pos "3h";
BA_ "InvalidValue" SG_ 1076 BCMFR_SeatVentilation_Sts "7h";
BA_ "InvalidValue" SG_ 1076 BCMFR_SeatHeating_Sts "7h";
BA_ "GenSigStartValue" SG_ 1155 TPMS_TireTemp 68;
BA_ "InvalidValue" SG_ 1158 ALIVE_TPMS_TirePressure2 "Fh";
BA_ "GenSigSendType" SG_ 1169 AmbLight_Error_Z1 1;
BA_ "GenSigSendType" SG_ 1169 AmbLight_Linerror_Z1 1;
BA_ "GenSigSendType" SG_ 1169 AmbLight_Error_Z2 1;
BA_ "GenSigSendType" SG_ 1169 AmbLight_Linerror_Z2 1;
BA_ "GenSigSendType" SG_ 1169 AmbLight_Error_Z6 1;
BA_ "GenSigSendType" SG_ 1169 AmbLight_LinError_Z6 1;
BA_ "GenSigSendType" SG_ 1169 AmbLight_Error_Z6B 1;
BA_ "GenSigSendType" SG_ 1169 AmbLight_LinError_Z6B 1;
BA_ "GenSigSendType" SG_ 1169 AmbLight_Error_Z7 1;
BA_ "GenSigSendType" SG_ 1169 AmbLight_LinError_Z7 1;
BA_ "GenSigSendType" SG_ 1169 AmbLight_Error_Z8 1;
BA_ "GenSigSendType" SG_ 1169 AmbLight_LinError_Z8 1;
BA_ "GenSigSendType" SG_ 1169 AmbLight_Error_Z7B 1;
BA_ "GenSigSendType" SG_ 1169 AmbLight_LinError_Z7B 1;
BA_ "GenSigSendType" SG_ 1169 AmbLight_Error_Z8B 1;
BA_ "GenSigSendType" SG_ 1169 AmbLight_LinError_Z8B 1;
BA_ "GenSigSendType" SG_ 1169 AmbLight_Error_Z2B 1;
BA_ "GenSigSendType" SG_ 1169 AmbLight_LinError_Z2B 1;
BA_ "InvalidValue" SG_ 1220 ALIVE_APM_FR_WarnMsg "Fh";
BA_ "InvalidValue" SG_ 1241 ALIVE_BCM_FR_WarnMsg_FR "Fh";
BA_ "SystemSignalLongSymbol" SG_ 1241 BCM_FR_IDB_Brakelight_Malfunctio "BCM_FR_IDB_Brakelight_Malfunction";
BA_ "SystemSignalLongSymbol" SG_ 1241 BCM_FR_CVC_Brakelight_Malfunctio "BCM_FR_CVC_Brakelight_Malfunction";
BA_ "GenSigSendType" SG_ 1859 BCMFR_DebugSignal01 1;
BA_ "GenSigSendType" SG_ 1859 BCMFR_DebugSignal02 1;
BA_ "GenSigSendType" SG_ 1859 BCMFR_DebugSignal03 1;
BA_ "GenSigSendType" SG_ 1859 BCMFR_DebugSignal04 1;
BA_ "GenSigSendType" SG_ 1859 BCMFR_DebugSignal05 1;
BA_ "GenSigSendType" SG_ 1859 BCMFR_DebugSignal06 1;
BA_ "GenSigSendType" SG_ 1859 BCMFR_DebugSignal07 1;
BA_ "GenSigSendType" SG_ 1859 BCMFR_DebugSignal08 1;
BA_ "GenSigSendType" SG_ 1972 BCMFR_Req_RandomData 2;
BA_ "GenSigSendType" SG_ 1972 BCMFR_Req_MAC 2;
BA_ "GenSigTimeoutTime_ALL" SG_ 133 CRC_ACU_CRASH_INFO 200;
BA_ "InvalidValue" SG_ 133 ALIVE_ACU_CRASH_INFO "Fh";
BA_ "GenSigTimeoutTime_ALL" SG_ 133 ALIVE_ACU_CRASH_INFO 200;
BA_ "InvalidValue" SG_ 133 ACU_Crash_Sts "3h";
BA_ "GenSigTimeoutTime_ALL" SG_ 133 ACU_Crash_Sts 200;
BA_ "InvalidValue" SG_ 133 ACU_Airbag_Deployment_Status "3h";
BA_ "GenSigTimeoutTime_ALL" SG_ 133 ACU_Airbag_Deployment_Status 200;
BA_ "InvalidValue" SG_ 133 ACU_Crash_Intensity "7h";
BA_ "GenSigTimeoutTime_ALL" SG_ 133 ACU_Crash_Intensity 200;
BA_ "InvalidValue" SG_ 133 ACU_Front_Crash "3h";
BA_ "GenSigTimeoutTime_ALL" SG_ 133 ACU_Front_Crash 200;
BA_ "InvalidValue" SG_ 133 ACU_DriverSide_Crash "3h";
BA_ "GenSigTimeoutTime_ALL" SG_ 133 ACU_DriverSide_Crash 200;
BA_ "InvalidValue" SG_ 133 ACU_PassSide_Crash "3h";
BA_ "GenSigTimeoutTime_ALL" SG_ 133 ACU_PassSide_Crash 200;
BA_ "InvalidValue" SG_ 133 ACU_Rear_Crash "3h";
BA_ "GenSigTimeoutTime_ALL" SG_ 133 ACU_Rear_Crash 200;
BA_ "InvalidValue" SG_ 133 ACU_Rollover_Crash "3h";
BA_ "GenSigTimeoutTime_ALL" SG_ 133 ACU_Rollover_Crash 200;
BA_ "InvalidValue" SG_ 162 WLS_WindowBtnPress_FL "7h";
BA_ "InvalidValue" SG_ 162 WLS_WindowBtnPress_FR "7h";
BA_ "InvalidValue" SG_ 162 WLS_WindowBtnPress_RL "7h";
BA_ "InvalidValue" SG_ 162 WLS_WindowBtnPress_RR "7h";
BA_ "InvalidValue" SG_ 162 WLS_DoorLockbtnPress "3h";
BA_ "InvalidValue" SG_ 176 CVC_Window_Control_FL "Fh";
BA_ "InvalidValue" SG_ 176 CVC_Window_Control_FR "Fh";
BA_ "InvalidValue" SG_ 176 CVC_Window_Control_RL "Fh";
BA_ "InvalidValue" SG_ 176 CVC_Window_Control_RR "Fh";
BA_ "InvalidValue" SG_ 176 CVC_Windows_Control_Global "Fh";
BA_ "InvalidValue" SG_ 176 CVC_Window_Control_Learning "6h";
BA_ "InvalidValue" SG_ 193 Ionizer_Set "3h";
BA_ "GenSigSendType" SG_ 193 Ionizer_Set 1;
BA_ "GenSigSendType" SG_ 193 RecirculationFlap_Set 1;
BA_ "GenSigSendType" SG_ 193 AirDistributionMode_Set 1;
BA_ "GenSigSendType" SG_ 193 RHTempFlap_Set 1;
BA_ "GenSigSendType" SG_ 193 LHTempFlap_Set 1;
BA_ "InvalidValue" SG_ 193 FrontBlowerRelay_Set "3h";
BA_ "GenSigSendType" SG_ 193 FrontBlowerRelay_Set 1;
BA_ "GenSigSendType" SG_ 193 CVC_EvapTempSet 1;
BA_ "GenSigSendType" SG_ 193 AirDistributionModeLH_Set 1;
BA_ "GenSigSendType" SG_ 193 AirDistributionModeRH_Set 1;
BA_ "GenSigSendType" SG_ 193 BypassFlap_Set 1;
BA_ "GenSigSendType" SG_ 193 AirDistributionModeRear_Set 1;
BA_ "SystemSignalLongSymbol" SG_ 196 CRC_CVC_ThermalComponent_Control "CRC_CVC_ThermalComponent_Control_1";
BA_ "InvalidValue" SG_ 196 ALIVE_CVC_ThermalComponent_Contr "Fh";
BA_ "SystemSignalLongSymbol" SG_ 196 ALIVE_CVC_ThermalComponent_Contr "ALIVE_CVC_ThermalComponent_Control_1";
BA_ "GenSigSendType" SG_ 196 CVC_CoolingFan_OnOff_Req 1;
BA_ "GenSigSendType" SG_ 196 CVC_FEDSPump_OnOff_Req 1;
BA_ "GenSigSendType" SG_ 196 CVC_BMSPump_OnOff_Req 1;
BA_ "GenSigSendType" SG_ 196 CVC_REDSPump_OnOff_Req 1;
BA_ "GenSigSendType" SG_ 196 CVC_HVMainRelay_OnOff_Req 1;
BA_ "SystemSignalLongSymbol" SG_ 197 CRC_CVC_ThermalComponent_Co_0000 "CRC_CVC_ThermalComponent_Control_2";
BA_ "InvalidValue" SG_ 197 ALIVE_CVC_ThermalComponent__0000 "Fh";
BA_ "SystemSignalLongSymbol" SG_ 197 ALIVE_CVC_ThermalComponent__0000 "ALIVE_CVC_ThermalComponent_Control_2";
BA_ "GenSigSendType" SG_ 197 CVC_BatteryChillerSOV_Req 1;
BA_ "GenSigSendType" SG_ 197 CVC_EvapSOV_Req 1;
BA_ "GenSigSendType" SG_ 197 CVC_CoolingFan_PWM_Req 1;
BA_ "GenSigSendType" SG_ 197 CVC_FEDSPump_PWM_Req 1;
BA_ "GenSigSendType" SG_ 197 CVC_BMSPump_PWM_Req 1;
BA_ "GenSigSendType" SG_ 197 CVC_REDSPump_PWM_Req 1;
BA_ "GenSigSendType" SG_ 197 CVC_WaterPump4_PWM_Req 1;
BA_ "GenSigSendType" SG_ 197 CVC_EvapSOV2_Req 1;
BA_ "GenSigSendType" SG_ 197 RearDuctFlap_Set 1;
BA_ "GenSigSendType" SG_ 197 CVC_RearBlwSpeed_Req 1;
BA_ "GenSigSendType" SG_ 197 CVC_RearBlwRamp_Req 1;
BA_ "GenSigSendType" SG_ 197 CVC_RearBlwSafetySpeed_Req 1;
BA_ "GenSigSendType" SG_ 197 CVC_RearBlwCodeVehicle_Req 1;
BA_ "GenSigSendType" SG_ 197 CVC_RearAPTC_HeatingRequest 1;
BA_ "GenSigSendType" SG_ 197 CVC_RearAPTC_OnOffRequest 1;
BA_ "GenSigSendType" SG_ 197 CVC_RearEXV_Set_Req 1;
BA_ "GenSigSendType" SG_ 197 CVC_RearEXV_Move_Enbl_Req 1;
BA_ "GenSigSendType" SG_ 197 CVC_RearEXV_Init_Req 1;
BA_ "GenSigSendType" SG_ 197 CVC_RearEvapTempSet 1;
BA_ "InvalidValue" SG_ 201 ALIVE_FMCU_Status "Fh";
BA_ "GenSigStartValue" SG_ 201 FMCU_MotorTq 4000;
BA_ "GenSigStartValue" SG_ 201 FMCU_MotorSpd 20000;
BA_ "InvalidValue" SG_ 201 FMCU_StsMCUFault "Fh";
BA_ "InvalidValue" SG_ 201 FMCU_MotorSpdSts "1h";
BA_ "InvalidValue" SG_ 201 FMCU_MotorTqSts "1h";
BA_ "InvalidValue" SG_ 201 FMCU_CVC_CtrlMode "Fh";
BA_ "InvalidValue" SG_ 201 FMCU_CVC_StsMode "Fh";
BA_ "InvalidValue" SG_ 202 ALIVE_CVC_DoorSetting_Feedback "Fh";
BA_ "InvalidValue" SG_ 202 CVC_STAT_UserSettingAutoUnlock "3h";
BA_ "InvalidValue" SG_ 202 CVC_STAT_DoorUnlockOption "3h";
BA_ "InvalidValue" SG_ 203 ALIVE_RMCU_Status "Fh";
BA_ "GenSigStartValue" SG_ 203 RMCU_MotorTq 4000;
BA_ "GenSigStartValue" SG_ 203 RMCU_MotorSpd 20000;
BA_ "InvalidValue" SG_ 203 RMCU_StsMCUFault "Fh";
BA_ "InvalidValue" SG_ 203 RMCU_MotorSpdValid "1h";
BA_ "InvalidValue" SG_ 203 RMCU_MotorTqValid "1h";
BA_ "InvalidValue" SG_ 203 RMCU_CVC_CtrlMode "Fh";
BA_ "InvalidValue" SG_ 203 RMCU_CVC_StsMode "Fh";
BA_ "InvalidValue" SG_ 210 ALIVE_CVC_BCM_Control_Request "Fh";
BA_ "InvalidValue" SG_ 210 DriverSideDoor_Lock_Req "5h";
BA_ "InvalidValue" SG_ 210 CoDriverSideDoor_Lock_Req "5h";
BA_ "InvalidValue" SG_ 210 Bonnet_Lock_Req "4h";
BA_ "InvalidValue" SG_ 210 Tailgate_Lock_Req "4h";
BA_ "InvalidValue" SG_ 210 Fuel_Port_Lock_Req "4h";
BA_ "InvalidValue" SG_ 210 CVC_TPMS_Control_LearningStart "3h";
BA_ "InvalidValue" SG_ 210 KeyFOBSearch_Req "3h";
BA_ "InvalidValue" SG_ 210 CVC_SET_FCAMHeated_Req "3h";
BA_ "InvalidValue" SG_ 210 CentralLockLightRequest "3h";
BA_ "InvalidValue" SG_ 210 CVC_B_PowerOutlet_Req "3h";
BA_ "InvalidValue" SG_ 217 ALIVE_CVC_HV_DrvSys_status "Fh";
BA_ "InvalidValue" SG_ 217 CVC_HVsystem_status "7h";
BA_ "InvalidValue" SG_ 217 CVC_ACPD_Percent_Valid "1h";
BA_ "InvalidValue" SG_ 217 CVC_ACTGearValid "1h";
BA_ "InvalidValue" SG_ 217 CVC_ACT_DriveMode "7h";
BA_ "GenSigStartValue" SG_ 217 CVC_ACT_DriveMode_Valid 1;
BA_ "InvalidValue" SG_ 217 CVC_HV_DRVsystem_status "7h";
BA_ "InvalidValue" SG_ 256 ALIVE_CVC_B_Vehicle_Info "Fh";
BA_ "InvalidValue" SG_ 256 CVC_B_UserProfileId "Fh";
BA_ "InvalidValue" SG_ 258 ALIVE_CVC_LOGICAL_CLAMP "Fh";
BA_ "InvalidValue" SG_ 258 STAT_CrankRelayHW_BCM "3h";
BA_ "InvalidValue" SG_ 258 CVC_Transport_Mode "3h";
BA_ "InvalidValue" SG_ 258 CVC_Vehicle_Special_Mode "7h";
BA_ "InvalidValue" SG_ 258 CVC_Acc_Mode_Req "3h";
BA_ "InvalidValue" SG_ 258 CVC_CL30s_Req "3h";
BA_ "GenSigStartValue" SG_ 258 CVC_CL30s_Req 3;
BA_ "InvalidValue" SG_ 258 CVC_CL30c_Req "3h";
BA_ "GenSigStartValue" SG_ 258 CVC_CL30c_Req 3;
BA_ "InvalidValue" SG_ 258 CVC_CLR_Req "3h";
BA_ "GenSigStartValue" SG_ 258 CVC_CLR_Req 3;
BA_ "InvalidValue" SG_ 258 CVC_CL15_Req "3h";
BA_ "GenSigStartValue" SG_ 258 CVC_CL15_Req 3;
BA_ "InvalidValue" SG_ 258 CVC_CL58_Req "3h";
BA_ "GenSigStartValue" SG_ 258 CVC_CL58_Req 3;
BA_ "InvalidValue" SG_ 264 ALIVE_SS_DriveReq_0x108 "Fh";
BA_ "InvalidValue" SG_ 264 SS_P_Button "3h";
BA_ "InvalidValue" SG_ 264 SS_TargetGearReq "7h";
BA_ "InvalidValue" SG_ 264 SS_ADAS_Req "7h";
BA_ "InvalidValue" SG_ 264 SS_DrvMd_RgnLvl_Req "3h";
BA_ "InvalidValue" SG_ 264 SS_HighBeam_Req "3h";
BA_ "InvalidValue" SG_ 264 SS_Lane_Change_Indicator_Req "7h";
BA_ "InvalidValue" SG_ 264 SS_FR_RR_WashAndMist_Req "7h";
BA_ "InvalidValue" SG_ 264 SS_RR_WiperControl_Req "3h";
BA_ "InvalidValue" SG_ 264 SS_FR_Wipercontrol_Req "4h";
BA_ "InvalidValue" SG_ 264 SS_HardNumLow "Fh";
BA_ "InvalidValue" SG_ 264 SS_HardNumHigh "Fh";
BA_ "InvalidValue" SG_ 264 SS_SoftNumLow "Fh";
BA_ "InvalidValue" SG_ 264 SS_SoftNumHigh "Fh";
VAL_ 165 BCM_DSB_WindowBtnPress_FL 0 "No action" 1 "Pull up 1st stage" 2 "Pull up 2nd stage" 3 "Press down 1st stage" 4 "Press down 2nd stage" 5 "Fault" 6 "Reserved" 7 "Invalid" ;
VAL_ 165 BCM_DSB_WindowBtnPress_FR 0 "No action" 1 "Pull up 1st stage" 2 "Pull up 2nd stage" 3 "Press down 1st stage" 4 "Press down 2nd stage" 5 "Fault" 6 "Reserved" 7 "Invalid" ;
VAL_ 165 BCM_DSB_WindowBtnPress_RL 0 "No action" 1 "Pull up 1st stage" 2 "Pull up 2nd stage" 3 "Press down 1st stage" 4 "Press down 2nd stage" 5 "Fault" 6 "Reserved" 7 "Invalid" ;
VAL_ 165 BCM_DSB_WindowBtnPress_RR 0 "No action" 1 "Pull up 1st stage" 2 "Pull up 2nd stage" 3 "Press down 1st stage" 4 "Press down 2nd stage" 5 "Fault" 6 "Reserved" 7 "Invalid" ;
VAL_ 165 BCM_DSB_DoorLockBtnPress 0 "Not press" 1 "Short press" 2 "Long press" 3 "Invalid" ;
VAL_ 169 BCMFL_AmbientTempSts 0 "Normal" 1 "Short circuit Battery" 2 "Short circuit GND" 3 "Invalid" ;
VAL_ 169 BCMFL_CoolantTemp_EDS_In_Sts 0 "Normal" 1 "Short circuit Battery" 2 "Short circuit GND" 3 "Invalid" ;
VAL_ 169 BCMFL_CoolantTemp_EDS_Out_Sts 0 "Normal" 1 "Short circuit Battery" 2 "Short circuit GND" 3 "Invalid" ;
VAL_ 169 BCMFL_CoolantTemp_LTR_Out_Sts 0 "Normal" 1 "Short circuit Battery" 2 "Short circuit GND" 3 "Invalid" ;
VAL_ 169 BCMFL_ACLowSideTemperatureSts 0 "Normal" 1 "Short circuit Battery" 2 "Short circuit GND" 3 "Invalid" ;
VAL_ 169 BCMFL_ACLowSidePressureSts 0 "Normal" 1 "Short circuit Battery" 2 "Short circuit GND" 3 "Invalid" ;
VAL_ 169 BCMFL_ACHighSideTemperatureSts 0 "Normal" 1 "Short circuit Battery" 2 "Short circuit GND" 3 "Invalid" ;
VAL_ 169 BCMFL_ACHighSidePressureSts 0 "Normal" 1 "Short circuit Battery" 2 "Short circuit GND" 3 "Invalid" ;
VAL_ 169 BCMFL_CoolantTemp_HtrCore_In_Sts 0 "Normal" 1 "Short circuit Battery" 2 "Short circuit GND" 3 "Invalid" ;
VAL_ 169 BCMFL_Refrigerant_Temp_Sensor_St 0 "Normal" 1 "Short circuit Battery" 2 "Short circuit GND" 3 "Invalid" ;
VAL_ 169 BCMFL_PT_Sensor1_Pressure_Sts 0 "Normal" 1 "Short circuit Battery" 2 "Short circuit GND" 3 "Invalid" ;
VAL_ 169 BCMFL_PT_Sensor2_Pressure_Sts 0 "Normal" 1 "Short circuit Battery" 2 "Short circuit GND" 3 "Invalid" ;
VAL_ 170 BonnetLockStatus 0 "Closed" 1 "Opened" 2 "Reserved" 3 "Signal invalid" ;
VAL_ 170 DriverDoor_Lock_Sts 0 "Locked" 1 "Unlocked" 2 "Faults" 3 "Invalid" ;
VAL_ 170 DriverDoor_Ajar_Sts 0 "Closed" 1 "Opened" 2 "Faults" 3 "Invalid" ;
VAL_ 170 BonnetAjarStatus 0 "Closed" 1 "Opened" 2 "Faults" 3 "Invalid" ;
VAL_ 170 RLDoor_Lock_Sts 0 "Lock" 1 "Unlocked" 2 "Faults" 3 "Invalid" ;
VAL_ 170 RLDoor_Ajar_Sts 0 "Closed" 1 "Opened" 2 "Faults" 3 "Invalid" ;
VAL_ 178 MechanicalLockReq 0 "Lock" 1 "Unlock" 2 "No request" 3 "Reserved" 4 "Invalid" ;
VAL_ 178 Driver_PassiveEntryButton_Sts 0 "Not pressed" 1 "Pressed" 2 "PE switch long press" 3 "Extended long press" 4 "Fault (Stuck)" ;
VAL_ 178 FootKickOperation_Request 0 "Idle" 1 "Operation Request" 2 "Invalid" 3 "Invalid" ;
VAL_ 178 TailgateExtButton_Request 0 "No command" 1 "Short press" 2 "Long press" ;
VAL_ 180 BCMFL_WindowsFL_AntiPinch_Warn 0 "No error" 1 "Anti-pinch FL window" 2 "Error" 3 "Invalid" ;
VAL_ 180 BCMFL_WindowFL_Learning_Sts 0 "Invalid" 1 "FL window done" 2 "FL window failure" 3 "FL window learning" ;
VAL_ 180 BCMFL_WindowFL_Suppression_Warn 0 "OFF" 1 "Suppressed" 2 "Not suppressed" ;
VAL_ 180 BCMFL_WindowFL_LockActive 0 "Not Activate" 1 "Activated" ;
VAL_ 180 BCMFL_WindowFL_ThermalProtect 0 "OFF" 1 "Level 1" 2 "Level 2" ;
VAL_ 180 BCMFL_WindowFL_Error 0 "None" 1 "Window Error FL" ;
VAL_ 180 BCMFL_WindowsRL_AntiPinch_Warn 0 "No error" 1 "Anti-pinch RL window" 2 "Error" 3 "Invalid" ;
VAL_ 180 BCMFL_WindowRL_LockActive 0 "Not Activate" 1 "Activated" ;
VAL_ 180 BCMFL_WindowRL_Error 0 "None" 1 "Window Error RL" ;
VAL_ 180 BCMFL_WindowRL_Learning_Sts 0 "Invalid" 1 "RL window done" 2 "RL window failure" 3 "RL window learning" ;
VAL_ 180 BCMFL_WindowRL_Suppression_Warn 0 "OFF" 1 "Suppressed" 2 "Not suppressed" ;
VAL_ 180 BCMFL_WindowRL_ThermalProtect 0 "OFF" 1 "Level 1" 2 "Level 2" ;
VAL_ 180 Window_Position_FL 0 "Unknown" 1 "Closed (top) 0%" 2 "Position2(10%)" 3 "Position3(20%)" 4 "Position4(30%)" 5 "Position5(40%)" 6 "Position6(50%)" 7 "Position7(60%)" 8 "Position8(70%)" 9 "Position9(80%)" 10 "Position10(90%)" 11 "Soft Stop(95%)" 12 "Open (bottom) 100%" 13 "Reserved" 14 "Reserved" 15 "Signal Invalid" ;
VAL_ 180 Window_Position_RL 0 "Unknown" 1 "Closed (top) 0%" 2 "Position2(10%)" 3 "Position3(20%)" 4 "Position4(30%)" 5 "Position5(40%)" 6 "Position6(50%)" 7 "Position7(60%)" 8 "Position8(70%)" 9 "Position9(80%)" 10 "Position10(90%)" 11 "Soft Stop(95%)" 12 "Open (bottom) 100%" 13 "Reserved" 14 "Reserved" 15 "Signal Invalid" ;
VAL_ 180 BCMFL_WindowBtnPress_RL 0 "No action" 1 "Pull up 1st stage" 2 "Pull up 2nd stage" 3 "Press down 1st stage" 4 "Press down 2nd stage" ;
VAL_ 180 BCMFL_WindowBtnPress_FL 0 "No action" 1 "Pull up 1st stage" 2 "Pull up 2nd stage" 3 "Press down 1st stage" 4 "Press down 2nd stage" ;
VAL_ 180 BCMFL_WindowFL_Malfunction_Warn 0 "No Error" 1 "Error" 2 "Reserved" 3 "Invalid" ;
VAL_ 180 BCMFL_WindowRL_Malfunction_Warn 0 "No Error" 1 "Error" 2 "Reserved" 3 "Invalid" ;
VAL_ 198 BCMFL_CoolantLevel 0 "Normal condition" 1 "Low level condition" 2 "Reserved" 3 "Signal Invalid" ;
VAL_ 198 BCMFL_CoolingFan_Status 0 "Invalid" 1 "OFF" 2 "ON" 3 "Fault" ;
VAL_ 198 BCMFL_FEDSPump_Status 0 "Invalid" 1 "OFF" 2 "ON" 3 "Fault" ;
VAL_ 198 BCMFL_BMSPump_Status 0 "Invalid" 1 "OFF" 2 "ON" 3 "Fault" ;
VAL_ 198 BCMFL_REDSPump_Status 0 "Invalid" 1 "OFF" 2 "ON" 3 "Fault" ;
VAL_ 198 BCMFL_HVMainRelay_Status 0 "Invalid" 1 "OFF" 2 "ON" 3 "Fault" ;
VAL_ 198 BCMFL_FEDSPump_Fault 0 "Normal" 1 "Idle fault" 2 "Overcurrent/locked rotor fault" 3 "Overheating fault" 4 "Short circuit" 5 "Short to ground" 6 "Short to battery" 7 "Invalid" ;
VAL_ 198 BCMFL_BMSPump_Fault 0 "Normal" 1 "Idle fault" 2 "Overcurrent/locked rotor fault" 3 "Overheating fault" 4 "Short circuit" 5 "Short to ground" 6 "Short to battery" 7 "Invalid" ;
VAL_ 198 BCMFL_SOV_Fault 0 "Normal" 1 "Open circuit" 2 "Driver chip fault" 3 "Invalid" ;
VAL_ 198 BCMFL_CoolingFan_Fault 0 "Normal" 1 "Fan Blocked" 2 "Short circuit" 3 "Over Temperature" 4 "Reserved" 5 "Reserved" 6 "Reserved" 7 "Reserved" ;
VAL_ 198 BCMFL_CoolantLevel2 0 "Normal condition" 1 "Low level condition" 2 "Reserved" 3 "Invalid" ;
VAL_ 198 BCMFL_RearACLowSidePressureSts 0 "Normal" 1 "Short circuit Battery" 2 "Short circuit GND" 3 "Invalid" ;
VAL_ 198 BCMFL_RearACLowSideTemperatureSt 0 "Normal" 1 "Short circuit Battery" 2 "Short circuit GND" 3 "Invalid" ;
VAL_ 198 BCMFL_REDSPump_Fault 0 "Normal" 1 "Idle fault" 2 "Overcurrent/locked rotor fault" 3 "Overheating fault" 4 "Short circuit" 5 "Short to ground" 6 "Short to battery" 7 "Invalid" ;
VAL_ 199 BCMFL_BatterySOV_Status 0 "Invalid" 1 "OFF" 2 "ON" 3 "Fault" ;
VAL_ 199 BCMFL_EvapSOV_Status 0 "Invalid" 1 "SOV Open" 2 "SOV Close" 3 "Fault" ;
VAL_ 199 BCMFL_CoolantLevelError 0 "Normal" 1 "Fault" ;
VAL_ 199 BCMFL_CoolantLevel2Error 0 "Normal" 1 "Fault" ;
VAL_ 252 BCMFL_WasherPumpSts 0 "OFF" 1 "Front spraying" 2 "Rear spraying" 3 "Fault" ;
VAL_ 252 BCMFL_Wiper_Front_Status 0 "OFF" 1 "Mist" 2 "Intermittent Auto" 3 "Low speed" 4 "High speed" ;
VAL_ 252 BCMFL_STAT_FrontWiperServiceMode 0 "OFF" 1 "ON" 2 "Fault" 3 "Signal Invalid" ;
VAL_ 252 BCMFL_WiperServiceModeSts 0 "OFF" 1 "ON" 2 "Fault" ;
VAL_ 252 BCM_Fr_Rr_WashAndMist_Status 0 "No request" 1 "Front MIST" 2 "Front Wash and Wipe" 3 "Rear MIST" 4 "Rear Wash and Wipe" 5 "Reserved" 6 "Reserved" 7 "Invalid" ;
VAL_ 252 WakeupForTopup_Req 0 "Disable" 1 "Enable" 3 "Invalid" ;
VAL_ 252 BCMFL_InteriorTemperatureSts 0 "Normal" 1 "Short circuit Battery" 2 "Short circuit GND" 3 "Invalid" ;
VAL_ 252 BCM_Front_Wiper_Park_Pos_Status 0 "Front wiper not in Parking position" 1 "Front wiper in Parking position" ;
VAL_ 252 BCM_FL_STAT_RearHeatedWindowMirr 0 "OFF" 1 "ON" 2 "Reserved" 3 "Signal invalid" ;
VAL_ 252 BCMFL_STAT_Horn 0 "OFF" 1 "ON" 2 "Fault (Reserved)" 3 "Signal Invalid" ;
VAL_ 252 BCMFL_PowerOutlet_Sts 0 "OFF" 1 "ON" 2 "ERROR" 3 "Signal Invalid" ;
VAL_ 260 SOH_SUL_STATE 0 "Not learned" 1 "Learned" 2 "Reserved" 3 "Signal invalid" ;
VAL_ 260 SOC_STATE 0 "deviation > 15%" 1 "deviation < 15%" 2 "deviation < 10%" 3 "invalid" ;
VAL_ 260 Resp_Error 0 "No Error" 1 "Error" ;
VAL_ 260 FLAG_INCONSTENCY 0 "No battery inconsistency" 1 "Battery inconsistency" ;
VAL_ 260 EBS_error 0 "No Error" 1 "Error" ;
VAL_ 260 FLAG_DISCONNECT 0 "No battery disconnection" 1 "Battery disconnection" ;
VAL_ 266 LV_BatteryType 0 "Lead Acid Battery" 1 "Lithium Battery" 2 "Reversed" 3 "Invalid" ;
VAL_ 277 BCM_ChildLock_Feedback 0 "OFF" 1 "ON" 2 "Reserved" 3 "Signal Invalid" ;
VAL_ 280 BCM_DrvInhibitStsFbk 0 "No effect" 1 "Inhibited" 2 "UnInhibited" 3 "Signal Invalid" ;
VAL_ 529 BCM_LowBeam_FL_Sts 0 "OFF" 1 "ON" 2 "Reserved" 3 "Signal Invalid" 4 "Fault" ;
VAL_ 529 BCM_HighBeam_FL_Sts 0 "OFF" 1 "ON" 2 "Reserved" 3 "Signal Invalid" 4 "Fault" ;
VAL_ 529 BCM_TurnIndicator_FL_STS 0 "OFF" 1 "ON" 2 "Reserved" 3 "Signal Invalid" 4 "Fault" ;
VAL_ 529 BCM_PositionLight_FL_STS 0 "OFF" 1 "ON" 2 "Reserved" 3 "Signal Invalid" 4 "Fault" ;
VAL_ 529 BCM_RearFogLamp_FL_STS 0 "OFF" 1 "ON" 2 "Reserved" 3 "Signal Invalid" 4 "Fault" ;
VAL_ 529 BCM_HeightSensorSTS_Front 0 "Inactive" 1 "Active" 2 "Reserved" 3 "Error" ;
VAL_ 529 BCM_MirrorLED_FL_STS 0 "OFF" 1 "ON" 2 "Reserved" 3 "Signal Invalid" 4 "Fault" ;
VAL_ 529 BCM_HazardButton_FL_STS 0 "Not Press" 1 "Press" 2 "Reserved" 3 "Signal Invalid" ;
VAL_ 529 BCM_DaytimeRunningLight_FL_Sts 0 "OFF" 1 "ON" 2 "Reserved" 3 "Signal Invalid" 4 "Fault" ;
VAL_ 529 BCM_FrontFogLamp_FL_STS 0 "OFF" 1 "ON" 2 "Reserved" 3 "Signal Invalid" 4 "Fault" ;
VAL_ 532 BCM_Mirror_CourtesyLightSts 0 "OFF" 1 "ON" 2 "No Request" 3 "Signal Invalid" ;
VAL_ 532 BCM_FL_BonnetSts 0 "Closed" 1 "Opened" 2 "Reserved" 3 "Invalid signal" ;
VAL_ 532 BCM_FL_BonnetLightSts 0 "OFF" 1 "ON" 2 "Reserved" 3 "Signal Invalid" ;
VAL_ 532 BCM_FLFootwellLightSts 0 "OFF" 1 "ON" 2 "Reserved" 3 "Signal Invalid" ;
VAL_ 532 BCM_FL_FrontDomeLampStatus 0 "OFF" 1 "ON" 2 "Fault" 3 "Signal Invalid" ;
VAL_ 532 BCM_FLScuffLightSts 0 "OFF" 1 "ON" 2 "Reserved" 3 "Signal Invalid" ;
VAL_ 532 BCM_FLProjectorLightSts 0 "OFF" 1 "ON" 2 "Reserved" 3 "Signal Invalid" ;
VAL_ 561 DOW_DoorAjarStatusRL 0 "Closed" 1 "Opened" 2 "Faults" 3 "Invalid" ;
VAL_ 561 DOW_DoorAjarStatusFL 0 "Closed" 1 "Opened" 2 "Faults" 3 "Invalid" ;
VAL_ 561 CVC_ADAS_BonnetAjarStatus 0 "Closed" 1 "Opened" 2 "Faults" 3 "Invalid" ;
VAL_ 561 CVC_ADAS_TailgateAjarStatus 0 "Closed" 1 "Opened" 2 "Faults" 3 "Invalid" ;
VAL_ 805 Steering_Wheel_Convenience_Acces 0 "ON" 1 "OFF" 2 "Invalid" 3 "Invalid" ;
VAL_ 805 Steering_HeatingControlFdbk 0 "Disable" 1 "Enable" 2 "Error" ;
VAL_ 805 BCMFL_STS_SteerAdjust 0 "OFF" 1 "ON" 2 "Reserved" 3 "Signal Invalid" ;
VAL_ 805 SWHC_SterringWheelHeatFaultReaso 0 "Normal" 1 "resistive heater open circuit" 2 "resistive heater short out" 3 "thermistor open circuit" 4 "thermistor short out" 5 "thermistor overheat" ;
VAL_ 805 Steer_ProfileSave_Tips 0 "no tips" 1 "save successfully" 2 "save fail" ;
VAL_ 805 Steer_ColUpDown_Sts 0 "Inactive" 1 "Active" ;
VAL_ 805 Steer_ElecAdjust_SettingSts 0 "No Request" 1 "Save" 2 "Restore memory location" 3 "Moving" ;
VAL_ 1049 SHVU_STAT_SeatHeatingFrontL 0 "OFF" 1 "Level1" 2 "Level2" 3 "Level3" 4 "Signal invalid" ;
VAL_ 1049 SHVU_STAT_SeatCoolingFrontL 0 "OFF" 1 "Level1" 2 "Level2" 3 "Level3" 4 "Signal invalid" ;
VAL_ 1049 SHVU_STAT_FrontSeatVentSts 0 "Normal Operation" 1 "Failure" 2 "Reserved" 3 "Signal invalid" ;
VAL_ 1065 BCMFL_SeatRecliner_Sw 0 "No action" 1 "Forward request" 2 "Backward request" 3 "Invalid Value" ;
VAL_ 1065 BCMFL_SeatTilt_Sw 0 "No action" 1 "Angle up request" 2 "Angle down request" 3 "Invalid Value" ;
VAL_ 1065 BCMFL_SeatHeight_Sw 0 "No action" 1 "Up request" 2 "Down request" 3 "Invalid Value" ;
VAL_ 1065 BCMFL_SeatTrack_Sw 0 "No action" 1 "Forward request" 2 "Backward request" 3 "Invalid Value" ;
VAL_ 1065 BCMFL_SeatMassageLevel_Sts 0 "OFF" 1 "Initial Value" 2 "Level 1 (Weak)" 3 "Level 2 (General)" 4 "Level 3 (Strong)" 5 "Reserved" 6 "Reserved" 7 "Invalid" ;
VAL_ 1065 BCMFL_SeatMassageMode_Sts 0 "OFF" 1 "Wave mode" 2 "Catpad mode" 3 "Cross mode" 4 "Relieve mode" 5 "Jump mode" 6 "Reserved" 7 "Invalid" ;
VAL_ 1065 BCMFL_SeatControl_Sts 0 "Idle" 1 "Moving by CVC" 2 "Moving by switch" 3 "Invalid Value" ;
VAL_ 1065 BCMFL_SeatVentilation_Sts 0 "OFF" 1 "Level 1" 2 "Level 2" 3 "Level 3" 4 "Fault" 5 "Reserved" 6 "Reserved" 7 "Invalid" ;
VAL_ 1065 BCMFL_SeatHeating_Sts 0 "OFF" 1 "Level 1" 2 "Level 2" 3 "Level 3" 4 "Fault" 5 "Reserved" 6 "Reserved" 7 "Invalid" ;
VAL_ 1065 BCMFL_FrontPsg_SeatTrack_Pos 0 "Front position" 1 "Not front position" 2 "Failure" 3 "invalid Value" ;
VAL_ 1071 BCMFL_STAT_LeftMirrorHeating 0 "OFF" 1 "ON" 2 "Fault" 3 "Signal Invalid" ;
VAL_ 1071 BCMFL_STAT_LeftMirrorFold 0 "Fold" 1 "Unfold" 2 "Fault" 3 "Signal Invalid" ;
VAL_ 1071 BCMFL_STAT_MirrorAdjustLeft 0 "OFF" 1 "ON" 2 "Fault" 3 "Signal Invalid" ;
VAL_ 1111 AmbLight_Error_Z3 0 "No Error" 1 "Error" ;
VAL_ 1111 AmbLight_Linerror_Z3 0 "No Error" 1 "Error" ;
VAL_ 1111 AmbLight_Error_Z3B 0 "No Error" 1 "Error" ;
VAL_ 1111 AmbLight_Linerror_Z3B 0 "No Error" 1 "Error" ;
VAL_ 1118 BCM_HeaterActivation_Feedback 0 "OFF" 1 "ON" ;
VAL_ 1153 BCM_FL_TurnOffPosLightRemindr 0 "None" 1 "Alert" ;
VAL_ 1153 BCM_FL_StopLightDefect 0 "None" 1 "Alert" ;
VAL_ 1153 BCM_FL_LowBeamDefect 0 "None" 1 "Alert" ;
VAL_ 1153 BCM_FL_HighBeamDefect 0 "None" 1 "Alert" ;
VAL_ 1153 BCM_FL_PositionLightDefect 0 "None" 1 "Alert" ;
VAL_ 1153 BCM_FL_CHMLS_Defect 0 "None" 1 "Alert" ;
VAL_ 1153 BCM_FL_LicencePlateLight_Defect 0 "None" 1 "Alert" ;
VAL_ 1153 BCM_FL_FrontFog_Defect 0 "None" 1 "Alert" ;
VAL_ 1153 BCM_FL_RearLeftDoorLockDefect 0 "None" 1 "Alert" ;
VAL_ 1153 BCM_FL_ReverseLightDefect 0 "None" 1 "Alert" ;
VAL_ 1153 BCM_FL_12VBattery_LowLevel 0 "None" 1 "Alert" ;
VAL_ 1153 BCM_FL_12VBattery_Discharging 0 "None" 1 "Alert" ;
VAL_ 1153 BCM_FL_TurnIndicatorDefect 0 "None" 1 "Alert" ;
VAL_ 1153 BCM_FL_IDB_Brakelight_Malfunctio 0 "None" 1 "Alert" ;
VAL_ 1153 BCM_FL_CVC_Brakelight_Malfunctio 0 "None" 1 "Alert" ;
VAL_ 1153 BCM_FL_ADAS_Turnlight_Malfunctio 0 "None" 1 "Alert" ;
VAL_ 1153 BCM_FL_ADAS_Highbeam_Malfunction 0 "None" 1 "Alert" ;
VAL_ 1153 BCM_FL_ADAS_LowBeam_Malfunction 0 "None" 1 "Alert" ;
VAL_ 1153 BCM_FL_CVC_B_Malfunction 0 "None" 1 "Alert" ;
VAL_ 1153 BCM_FL_BCM_Malfunction 0 "None" 1 "Alert" ;
VAL_ 1153 BCM_FL_CrashSignalDefect 0 "None" 1 "Alert" ;
VAL_ 1153 BCM_FL_RearFog_Defect 0 "None" 1 "Alert" ;
VAL_ 1153 BCM_FL_FrontWiperDefect 0 "None" 1 "Alert" ;
VAL_ 1153 BCM_FL_FrontLeftDoorLockDefect 0 "None" 1 "Alert" ;
VAL_ 1153 BCM_FL_RLT_Malfunction 0 "None" 1 "Alert" ;
VAL_ 1153 BCM_FL_BCM_POWER_Malfunction 0 "None" 1 "Alert" ;
VAL_ 1153 BCM_FL_LossCommGearStatus 0 "Normal" 1 "Error" ;
VAL_ 1217 APM_FL_Malfunction 0 "No Error" 1 "Error" ;
VAL_ 1217 APM_FL_ChildWindowLockStS 0 "No Error" 1 "Error" ;
VAL_ 1217 APM_FL_Warning_Flag_3 0 "No Error" 1 "Error" ;
VAL_ 1217 APM_FL_Warning_Flag_4 0 "No Error" 1 "Error" ;
VAL_ 1217 APM_FL_Warning_Flag_5 0 "No Error" 1 "Error" ;
VAL_ 1217 APM_FL_Warning_Flag_6 0 "No Error" 1 "Error" ;
VAL_ 1217 APM_FL_Warning_Flag_7 0 "No Error" 1 "Error" ;
VAL_ 1217 APM_FL_Warning_Flag_8 0 "No Error" 1 "Error" ;
VAL_ 1217 APM_FL_Warning_Flag_9 0 "No Error" 1 "Error" ;
VAL_ 1217 APM_FL_Warning_Flag_10 0 "No Error" 1 "Error" ;
VAL_ 1217 APM_FL_Warning_Flag_11 0 "No Error" 1 "Error" ;
VAL_ 1217 APM_FL_Warning_Flag_12 0 "No Error" 1 "Error" ;
VAL_ 160 KeyFOBAuthenStatus 0 "Init" 1 "Key invalid" 2 "Key search active" 3 "Key valid AR" 4 "Key valid IR" 5 "Key 10sec delay" 6 "Reserved" 7 "Reserved" 8 "Reserved" 9 "Reserved" 10 "Reserved" 11 "Reserved" 12 "Reserved" 13 "Reserved" 14 "Error" 15 "Signal invalid" ;
VAL_ 160 KeyFOBPosition 0 "No key detect" 1 "Key Invalid" 2 "Key outside Driver door" 3 "Key outside CoDriver Door" 4 "Key outside tailgate" 5 "Key inside tailgate" 6 "Key inside immo" 7 "Reserved" 8 "Reserved" 9 "Reserved" 10 "Reserved" 15 "Invalid" ;
VAL_ 160 FobId 0 "Key not available" 1 "FOB_1" 2 "FOB_2" 3 "Signal invalid" ;
VAL_ 160 BCMFR_KeyFob_LowBattery 0 "None" 1 "Alert" ;
VAL_ 160 BCMFR_KeyIgnoringStatus 0 "All FOBs allowed" 1 "KeyFOB ID01 disable" 2 "KeyFOB ID02 disable" 3 "Invalid" ;
VAL_ 160 KeyFOB_Authen_Process 0 "Not Authen" 1 "Authen Passed" 2 "Authen Failed" 3 "Invalid" ;
VAL_ 160 BCM_KeyFob_WindowOpen_Sts 0 "OFF" 1 "ON" ;
VAL_ 171 CoDriverDoor_Ajar_Sts 0 "Closed" 1 "Opened" 2 "Faults" 3 "Invalid" ;
VAL_ 171 RRDoor_Ajar_Sts 0 "Closed" 1 "Opened" 2 "Faults" 3 "Invalid" ;
VAL_ 171 CoDriverDoor_Lock_Sts 0 "Locked" 1 "Unlocked" 2 "Faults" 3 "Invalid" ;
VAL_ 171 RRDoor_Lock_Sts 0 "Lock" 1 "Unlocked" 2 "Faults" 3 "Invalid" ;
VAL_ 177 KeyFOB_Request 0 "No command" 1 "Lock" 2 "Unlock" 3 "Tailgate unlock long press" 4 "Tailgate unlock" 5 "Long press lock" 6 "Long press unlock" 7 "Panic alarm long press" 8 "Panic alarm press" 15 "Invalid" ;
VAL_ 177 CoDriver_PassiveEntryButton_Sts 0 "Not pressed" 1 "Pressed" 2 "PE switch long press" 3 "Extended long press" 4 "Fault (Stuck)" ;
VAL_ 181 BCMFR_WindowsFR_AntiPinch_Warn 0 "No error" 1 "Anti-pinch FR window" 2 "Error" 3 "Invalid" ;
VAL_ 181 BCMFR_WindowFR_Learning_Sts 0 "Invalid" 1 "FL window done" 2 "FL window failure" 3 "FL window learning" ;
VAL_ 181 BCMFR_WindowFR_Suppression_Warn 0 "OFF" 1 "Suppressed" 2 "Not suppressed" ;
VAL_ 181 BCMFR_WindowFR_LockActive 0 "Not Activate" 1 "Activated" ;
VAL_ 181 BCMFR_WindowFR_ThermalProtect 0 "OFF" 1 "Level 1" 2 "Level 2" ;
VAL_ 181 BCMFR_WindowFR_Error 0 "None" 1 "Window Error FL" ;
VAL_ 181 BCMFR_WindowsRR_AntiPinch_Warn 0 "No error" 1 "Anti-pinch RR window" 2 "Error" 3 "Invalid" ;
VAL_ 181 BCMFR_WindowRR_LockActive 0 "Not Activate" 1 "Activated" ;
VAL_ 181 BCMFR_WindowRR_Error 0 "None" 1 "Window Error RR" ;
VAL_ 181 BCMFR_WindowRR_Learning_Sts 0 "Invalid" 1 "RR window done" 2 "RR window failure" 3 "RR window learning" ;
VAL_ 181 BCMFR_WindowRR_Suppression_Warn 0 "OFF" 1 "Suppressed" 2 "Not suppressed" ;
VAL_ 181 BCMFR_WindowRR_ThermalProtect 0 "OFF" 1 "Level 1" 2 "Level 2" ;
VAL_ 181 BCMFR_WindowBtnPress_FrontPass 0 "No action" 1 "Pull up 1st stage" 2 "Pull up 2nd stage" 3 "Press down 1st stage" 4 "Press down 2nd stage" ;
VAL_ 181 Window_Position_FR 0 "Unknown" 1 "Closed (top) 0%" 2 "Position2(10%)" 3 "Position3(20%)" 4 "Position4(30%)" 5 "Position5(40%)" 6 "Position6(50%)" 7 "Position7(60%)" 8 "Position8(70%)" 9 "Position9(80%)" 10 "Position10(90%)" 11 "Soft Stop(95%)" 12 "Open (bottom) 100%" 13 "Reserved" 14 "Reserved" 15 "Signal Invalid" ;
VAL_ 181 Window_Position_RR 0 "Unknown" 1 "Closed (top) 0%" 2 "Position2(10%)" 3 "Position3(20%)" 4 "Position4(30%)" 5 "Position5(40%)" 6 "Position6(50%)" 7 "Position7(60%)" 8 "Position8(70%)" 9 "Position9(80%)" 10 "Position10(90%)" 11 "Soft Stop(95%)" 12 "Open (bottom) 100%" 13 "Reserved" 14 "Reserved" 15 "Signal Invalid" ;
VAL_ 181 BCMFR_WindowBtnPress_RR 0 "No action" 1 "Pull up 1st stage" 2 "Pull up 2nd stage" 3 "Press down 1st stage" 4 "Press down 2nd stage" ;
VAL_ 181 BCMFR_WindowFR_Malfunction_Warn 0 "No Error" 1 "Error" 2 "Reserved" 3 "Invalid" ;
VAL_ 181 BCMFR_WindowRR_Malfunction_Warn 0 "No Error" 1 "Error" 2 "Reserved" 3 "Invalid" ;
VAL_ 195 BCMFR_HumiditySts 0 "Normal" 1 "Fault" 2 "Reserved" 3 "Invalid" ;
VAL_ 195 BCMFR_PM25Sts 0 "Normal" 1 "Fault" 2 "Reserved" 3 "Invalid" ;
VAL_ 195 BCMFR_CO2Sts 0 "Normal" 1 "Fault" 2 "Reserved" 3 "Invalid" ;
VAL_ 195 BCMFR_DucTempRightFaceSts 0 "Normal" 1 "Short circuit Battery" 2 "Short circuit GND" 3 "Invalid" ;
VAL_ 195 BCMFR_DucTempLeftFaceSts 0 "Normal" 1 "Short circuit Battery" 2 "Short circuit GND" 3 "Invalid" ;
VAL_ 195 BCMFR_DucTempRightFootSts 0 "Normal" 1 "Short circuit Battery" 2 "Short circuit GND" 3 "Invalid" ;
VAL_ 195 BCMFR_DucTempLeftFootSts 0 "Normal" 1 "Short circuit Battery" 2 "Short circuit GND" 3 "Invalid" ;
VAL_ 195 BCMFR_RearEvapTempSensorInputSts 0 "Normal" 1 "Short circuit Battery" 2 "Short circuit GND" 3 "Invalid" ;
VAL_ 195 BCMFR_RearVentDuctTempSts 0 "Normal" 1 "Short circuit Battery" 2 "Short circuit GND" 3 "Invalid" ;
VAL_ 195 BCMFR_RearFootDuctTempSts 0 "Normal" 1 "Short circuit Battery" 2 "Short circuit GND" 3 "Invalid" ;
VAL_ 200 BCMFR_Climate_IonizerSts 0 "OFF" 1 "ON" 2 "Reserved" 3 "Invalid" ;
VAL_ 200 BCMFR_Climate_BlowerRelay 0 "Invalid" 1 "OFF" 2 "ON" 3 "Fault" ;
VAL_ 200 BCMFR_Climate_BlowerStatus 0 "Normal" 1 "Fault" ;
VAL_ 200 BCMFR_Climate_LHTempFlapSts 0 "Normal" 1 "Fault" ;
VAL_ 200 BCMFR_Climate_RHTempFlapSts 0 "Normal" 1 "Fault" ;
VAL_ 200 BCMFR_Climate_AirDistFlapSts 0 "Normal" 1 "Fault" ;
VAL_ 200 BCMFR_Climate_AirDistFlapLHSts 0 "Normal" 1 "Fault" ;
VAL_ 200 BCMFR_Climate_AirRecirSts 0 "Normal" 1 "Fault" ;
VAL_ 204 BCMFR_InteriorTempSts 0 "Normal" 1 "Short circuit Battery" 2 "Short circuit GND" 3 "Invalid" ;
VAL_ 204 BCMFR_PTCTempInletSts 0 "Normal" 1 "Short circuit Battery" 2 "Short circuit GND" 3 "Invalid" ;
VAL_ 204 BCMFR_PTCTempOutletLeSts 0 "Normal" 1 "Short circuit Battery" 2 "Short circuit GND" 3 "Invalid" ;
VAL_ 204 BCMFR_PTCTempOutletRiSts 0 "Normal" 1 "Short circuit Battery" 2 "Short circuit GND" 3 "Invalid" ;
VAL_ 204 BCMFR_EvapTempSensorInputSts 0 "Normal" 1 "Short circuit Battery" 2 "Short circuit GND" 3 "Invalid" ;
VAL_ 251 RLSFailureFeedback 0 "No error" 1 "Rain sensor error" 2 "Reserved" 3 "Signal Invalid" ;
VAL_ 251 BCMFR_RS_L_WiperSpeed 0 "OFF" 1 "Low speed" 2 "Low speed continuous" 3 "High speed continuos" ;
VAL_ 251 BCMFR_WasherFluidLevelSensorData 0 "Normal" 1 "Warning" 2 "Reserved" 3 "Reserved" ;
VAL_ 251 BCMFR_WasherPumpSts 0 "OFF" 1 "Front spraying" 2 "Rear spraying" 3 "Fault" ;
VAL_ 251 BCMFR_Rear_Wiper_Park_Pos_Status 0 "Rear wiper not in Parking position" 1 "Rear wiper in Parking position" 2 "Reserved" 3 "Reserved" ;
VAL_ 251 BCMFR_STAT_RearWiperServiceMode 0 "OFF" 1 "ON" 2 "Fault" 3 "Signal Invalid" ;
VAL_ 251 BCMFR_STAT_RearWiperWorkingSts 0 "OFF" 1 "ON" 2 "MIST" 3 "Wash and Wipe" 4 "Fault" ;
VAL_ 251 BCMFR_RearWiperWorkingSts 0 "OFF" 1 "ON" 2 "Fault" ;
VAL_ 251 BCM_AlcoholockSwitch 0 "Not active" 1 "Active" 2 "Reserved" 3 "Signal invalid" ;
VAL_ 251 CentralLockLightStatus 0 "OFF" 1 "ON" 2 "Reserved" 3 "Reserved" ;
VAL_ 286 BCMFR_CL30s_FR_Sts 0 "OFF" 1 "ON" 2 "Fault" 3 "Invalid" ;
VAL_ 286 BCMFR_CL30c_FR_Sts 0 "OFF" 1 "ON" 2 "Fault" 3 "Invalid" ;
VAL_ 286 BCMFR_CLR_FR_Sts 0 "OFF" 1 "ON" 2 "Fault" 3 "Invalid" ;
VAL_ 286 BCMFR_CL15_FR_Sts 0 "OFF" 1 "ON" 2 "Fault" 3 "Invalid" ;
VAL_ 286 BCMFR_CL58_FR_Sts 0 "OFF" 1 "ON" 2 "Fault" 3 "Invalid" ;
VAL_ 530 BCM_SideMarkerSts 0 "OFF" 1 "ON" 2 "Reserved" 3 "Invalid" ;
VAL_ 530 BCM_TurnIndicator_FR_STS 0 "OFF" 1 "ON" 2 "Reserved" 3 "Signal Invalid" 4 "Fault" ;
VAL_ 530 BCM_PositionLight_FR_STS 0 "OFF" 1 "ON" 2 "Reserved" 3 "Signal Invalid" 4 "Fault" ;
VAL_ 530 BCM_FrontFogLamp_FR_STS 0 "OFF" 1 "ON" 2 "Reserved" 3 "Signal Invalid" 4 "Fault" ;
VAL_ 530 BCM_DaytimeRunningLight_FR_Sts 0 "OFF" 1 "ON" 2 "Reserved" 3 "Signal Invalid" 4 "Fault" ;
VAL_ 530 BCM_MirrorLED_FR_STS 0 "OFF" 1 "ON" 2 "Reserved" 3 "Signal Invalid" 4 "Fault" ;
VAL_ 530 BCM_LowBeam_FR_Sts 0 "OFF" 1 "ON" 2 "Reserved" 3 "Signal Invalid" 4 "Fault" ;
VAL_ 530 BCM_HighBeam_FR_Sts 0 "OFF" 1 "ON" 2 "Reserved" 3 "Signal Invalid" 4 "Fault" ;
VAL_ 534 BCM_FRDoorCourtesyLightSts_Reser 0 "OFF" 1 "ON" 2 "No Request" 3 "Signal Invalid" ;
VAL_ 534 BCM_FRFootwellLightSts 0 "OFF" 1 "ON" 2 "Reserved" 3 "Signal Invalid" ;
VAL_ 534 BCM_FRScuffLightSts 0 "OFF" 1 "ON" 2 "Reserved" 3 "Signal Invalid" ;
VAL_ 534 BCM_FRProjectorLightSts 0 "OFF" 1 "ON" 2 "Reserved" 3 "Signal Invalid" ;
VAL_ 534 BCM_FR_Rear_2nd_DomeLampSts 0 "OFF" 1 "ON" 2 "Fault" 3 "Signal Invalid" ;
VAL_ 584 DOW_DoorAjarStatusRR 0 "Closed" 1 "Opened" 2 "Faults" 3 "Invalid" ;
VAL_ 584 DOW_DoorAjarStatusFR 0 "Closed" 1 "Opened" 2 "Faults" 3 "Invalid" ;
VAL_ 1051 SHVU_STAT_SeatHeatingFrontR 0 "OFF" 1 "Level1" 2 "Level2" 3 "Level3" 4 "Signal invalid" ;
VAL_ 1051 SHVU_STAT_SeatCoolingFrontR 0 "OFF" 1 "Level1" 2 "Level2" 3 "Level3" 4 "Signal invalid" ;
VAL_ 1051 SHVU_STAT_FrontSeatVentSts 0 "Normal Operation" 1 "Failure" 2 "Reserved" 3 "Signal invalid" ;
VAL_ 1072 BCMFR_STAT_RightMirrorHeating 0 "OFF" 1 "ON" 2 "Fault" 3 "Signal Invalid" ;
VAL_ 1072 BCMFR_STAT_RightMirrorFold 0 "Fold" 1 "Unfold" 2 "Fault" 3 "Signal Invalid" ;
VAL_ 1072 BCMFR_STAT_MirrorAdjustRight 0 "OFF" 1 "ON" 2 "Fault" 3 "Signal Invalid" ;
VAL_ 1076 BCMFR_SeatMassageLevel_Sts 0 "OFF" 1 "Initial Value" 2 "Level 1 (Weak)" 3 "Level 2 (General)" 4 "Level 3 (Strong)" 5 "Reserved" 6 "Reserved" 7 "Invalid" ;
VAL_ 1076 BCMFR_SeatMassageMode_Sts 0 "OFF" 1 "Wave mode" 2 "Catpad mode" 3 "Cross mode" 4 "Relieve mode" 5 "Jump mode" 6 "Reserved" 7 "Invalid" ;
VAL_ 1076 BCMFR_SeatTrack_Pos 0 "Front position" 1 "Not front position" 2 "Failure" 3 "Invalid Value" ;
VAL_ 1076 BCMFR_SeatVentilation_Sts 0 "OFF" 1 "Level 1" 2 "Level 2" 3 "Level 3" 4 "Fault" 5 "Reserved" 6 "Reserved" 7 "Invalid" ;
VAL_ 1076 BCMFR_SeatHeating_Sts 0 "OFF" 1 "Level 1" 2 "Level 2" 3 "Level 3" 4 "Fault" 5 "Reserved" 6 "Reserved" 7 "Invalid" ;
VAL_ 1151 TPMS_RRTireSignalLost 0 "No action" 1 "Alert" ;
VAL_ 1151 TPMS_RLTireSignalLost 0 "No action" 1 "Alert" ;
VAL_ 1151 TPMS_FRTireSignalLost 0 "No action" 1 "Alert" ;
VAL_ 1151 TPMS_FLTireSignalLost 0 "No action" 1 "Alert" ;
VAL_ 1155 TPMS_FLTirePressAlarm 0 "No warning" 1 "High pressure warning" 2 "Low pressure warning" 3 "Quick leakage" 4 "Lost Sensor" 5 "Sensor battery low" 6 "Sensor failure" 7 "High temperature" ;
VAL_ 1155 TPMS_FRTirePressAlarm 0 "No warning" 1 "High pressure warning" 2 "Low pressure warning" 3 "Quick leakage" 4 "Lost Sensor" 5 "Sensor battery low" 6 "Sensor failure" 7 "High temperature" ;
VAL_ 1155 TPMS_RLTirePressAlarm 0 "No warning" 1 "High pressure warning" 2 "Low pressure warning" 3 "Quick leakage" 4 "Lost Sensor" 5 "Sensor battery low" 6 "Sensor failure" 7 "High temperature" ;
VAL_ 1155 TPMS_RRTirePressAlarm 0 "No warning" 1 "High pressure warning" 2 "Low pressure warning" 3 "Quick leakage" 4 "Lost Sensor" 5 "Sensor battery low" 6 "Sensor failure" 7 "High temperature" ;
VAL_ 1155 TPMS_TirePosition 0 "No any sensor" 1 "Left Front tire" 2 "Right Front tire" 3 "Right Rear tire" 4 "Left Rear tire" 5 "reseved" 6 "reseved" 7 "reserved" ;
VAL_ 1155 TPMS_ready2learning 0 "Invalid" 1 "Ready" ;
VAL_ 1155 TPMS_TireTempAlarm 0 "No warning" 1 "High Temperature Warning" ;
VAL_ 1155 TPMS_LearningStatus 0 "Invalid" 1 "Left Front tire done" 2 "Right Front tire done" 3 "Right Rear tire done" 4 "Left Rear tire done" 5 "All completed" 6 "Failure" 7 "reserved" ;
VAL_ 1158 TPMS_FLTirePressAlarm2 0 "No warning" 1 "High pressure warning" 2 "Low pressure warning" 3 "Quick leakage" 4 "Lost Sensor" 5 "Sensor battery low" 6 "Sensor failure" 7 "Reserved" ;
VAL_ 1158 TPMS_FRTirePressAlarm2 0 "No warning" 1 "High pressure warning" 2 "Low pressure warning" 3 "Quick leakage" 4 "Lost Sensor" 5 "Sensor battery low" 6 "Sensor failure" 7 "Reserved" ;
VAL_ 1158 TPMS_RLTirePressAlarm2 0 "No warning" 1 "High pressure warning" 2 "Low pressure warning" 3 "Quick leakage" 4 "Lost Sensor" 5 "Sensor battery low" 6 "Sensor failure" 7 "Reserved" ;
VAL_ 1158 TPMS_RRTirePressAlarm2 0 "No warning" 1 "High pressure warning" 2 "Low pressure warning" 3 "Quick leakage" 4 "Lost Sensor" 5 "Sensor battery low" 6 "Sensor failure" 7 "Reserved" ;
VAL_ 1169 AmbLight_Error_Z1 0 "No Error" 1 "Error" ;
VAL_ 1169 AmbLight_Linerror_Z1 0 "No Error" 1 "Error" ;
VAL_ 1169 AmbLight_Error_Z2 0 "No Error" 1 "Error" ;
VAL_ 1169 AmbLight_Linerror_Z2 0 "No Error" 1 "Error" ;
VAL_ 1169 AmbLight_Error_Z6 0 "No Error" 1 "Error" ;
VAL_ 1169 AmbLight_LinError_Z6 0 "No Error" 1 "Error" ;
VAL_ 1169 AmbLight_Error_Z6B 0 "No Error" 1 "Error" ;
VAL_ 1169 AmbLight_LinError_Z6B 0 "No Error" 1 "Error" ;
VAL_ 1169 AmbLight_Error_Z7 0 "No Error" 1 "Error" ;
VAL_ 1169 AmbLight_LinError_Z7 0 "No Error" 1 "Error" ;
VAL_ 1169 AmbLight_Error_Z8 0 "No Error" 1 "Error" ;
VAL_ 1169 AmbLight_LinError_Z8 0 "No Error" 1 "Error" ;
VAL_ 1169 AmbLight_Error_Z7B 0 "No Error" 1 "Error" ;
VAL_ 1169 AmbLight_LinError_Z7B 0 "No Error" 1 "Error" ;
VAL_ 1169 AmbLight_Error_Z8B 0 "No Error" 1 "Error" ;
VAL_ 1169 AmbLight_LinError_Z8B 0 "No Error" 1 "Error" ;
VAL_ 1169 AmbLight_Error_Z2B 0 "No Error" 1 "Error" ;
VAL_ 1169 AmbLight_LinError_Z2B 0 "No Error" 1 "Error" ;
VAL_ 1220 APM_FR_Malfunction 0 "No Error" 1 "Error" ;
VAL_ 1220 APM_FR_ChildWindowLockStS 0 "No Error" 1 "Error" ;
VAL_ 1220 APM_FR_Warning_Flag_3 0 "No Error" 1 "Error" ;
VAL_ 1220 APM_FR_Warning_Flag_4 0 "No Error" 1 "Error" ;
VAL_ 1220 APM_FR_Warning_Flag_5 0 "No Error" 1 "Error" ;
VAL_ 1220 APM_FR_Warning_Flag_6 0 "No Error" 1 "Error" ;
VAL_ 1220 APM_FR_Warning_Flag_7 0 "No Error" 1 "Error" ;
VAL_ 1220 APM_FR_Warning_Flag_8 0 "No Error" 1 "Error" ;
VAL_ 1220 APM_FR_Warning_Flag_9 0 "No Error" 1 "Error" ;
VAL_ 1220 APM_FR_Warning_Flag_10 0 "No Error" 1 "Error" ;
VAL_ 1220 APM_FR_Warning_Flag_11 0 "No Error" 1 "Error" ;
VAL_ 1220 APM_FR_Warning_Flag_12 0 "No Error" 1 "Error" ;
VAL_ 1241 BCM_FR_NoValidKey_1 0 "None" 1 "Alert" ;
VAL_ 1241 BCM_FR_NoValidKey_2 0 "None" 1 "Alert" ;
VAL_ 1241 BCM_FR_TurnOffPosLightRemindr 0 "None" 1 "Alert" ;
VAL_ 1241 BCM_FR_KeyFob_LowBattery 0 "None" 1 "Alert" ;
VAL_ 1241 BCM_FR_StopLightDefect 0 "None" 1 "Alert" ;
VAL_ 1241 BCM_FR_LowBeamDefect 0 "None" 1 "Alert" ;
VAL_ 1241 BCM_FR_HighBeamDefect 0 "None" 1 "Alert" ;
VAL_ 1241 BCM_FR_PositionLightDefect 0 "None" 1 "Alert" ;
VAL_ 1241 BCM_FR_CHMLS_Defect 0 "None" 1 "Alert" ;
VAL_ 1241 BCM_FR_LicencePlateLight_Defect 0 "None" 1 "Alert" ;
VAL_ 1241 BCM_FR_FrontFog_Defect 0 "None" 1 "Alert" ;
VAL_ 1241 BCM_FR_RearFog_Defect 0 "None" 1 "Alert" ;
VAL_ 1241 BCM_FR_ReverseLightDefect 0 "None" 1 "Alert" ;
VAL_ 1241 BCM_FR_ForgetKeyFOBInCar 0 "None" 1 "Alert" ;
VAL_ 1241 BCM_FR_TurnIndicatorDefect 0 "None" 1 "Alert" ;
VAL_ 1241 BCM_FR_dTPMS_Malfunc 0 "None" 1 "Alert" ;
VAL_ 1241 BCM_FR_dTPMS_Malfunc_LostSensor 0 "None" 1 "Alert" ;
VAL_ 1241 BCM_FR_dTPMS_LowPressure 0 "None" 1 "Alert" ;
VAL_ 1241 BCM_FR_dTPMS_RapidLeak 0 "None" 1 "Alert" ;
VAL_ 1241 BCM_FR_dTPMS_HighTemperature 0 "None" 1 "Alert" ;
VAL_ 1241 BCM_FR_dTPMS_HighPressure 0 "None" 1 "Alert" ;
VAL_ 1241 BCM_FR_dTPMS_LowBattery 0 "None" 1 "Alert" ;
VAL_ 1241 BCM_Keyfob_Leftcar 0 "None" 1 "Alert" ;
VAL_ 1241 BCM_FR_IDB_Brakelight_Malfunctio 0 "None" 1 "Alert" ;
VAL_ 1241 BCM_FR_CVC_Brakelight_Malfunctio 0 "None" 1 "Alert" ;
VAL_ 1241 BCM_FR_Turnlight_Malfunction 0 "None" 1 "Alert" ;
VAL_ 1241 BCM_FR_Highbeam_Malfunction 0 "None" 1 "Alert" ;
VAL_ 1241 BCM_FR_LowBeam_Malfunction 0 "None" 1 "Alert" ;
VAL_ 1241 BCM_FR_Malfunction 0 "None" 1 "Alert" ;
VAL_ 1241 BCM_FR_BCM_Malfunction 0 "None" 1 "Alert" ;
VAL_ 1241 BCM_FR_SCM_Malfunction 0 "None" 1 "Alert" ;
VAL_ 1241 BCM_FR_CrashSignalDefect 0 "None" 1 "Alert" ;
VAL_ 1241 BCM_FR_FrontWiperDefect 0 "None" 1 "Alert" ;
VAL_ 1241 BCM_FR_Front_RightDoorLockDefect 0 "None" 1 "Alert" ;
VAL_ 1241 BCM_FR_LossCommGearStatus 0 "Normal" 1 "Error" ;
VAL_ 1241 BCM_FR_RLT_Malfunction 0 "None" 1 "Alert" ;
VAL_ 1241 BCM_FR_BCM_POWER_Malfunction 0 "None" 1 "Alert" ;
VAL_ 1241 BCM_FR_RRDoorLockDefect 0 "None" 1 "Alert" ;
VAL_ 133 ACU_Crash_Sts 0 "No_Event" 1 "Crash_Detected" ;
VAL_ 133 ACU_Airbag_Deployment_Status 0 "No_Airbag_Deployment" 1 "Airbag_Deployment" ;
VAL_ 133 ACU_Crash_Intensity 0 "No_Crash" 1 "Crash_Intensity_1" 2 "Crash_Intensity_2" 3 "Crash_Intensity_3" ;
VAL_ 133 ACU_Front_Crash 0 "No_Event" 1 "Front_Crash_Detected" ;
VAL_ 133 ACU_DriverSide_Crash 0 "No_Event" 1 "Driverside_Crash_Detected" ;
VAL_ 133 ACU_PassSide_Crash 0 "No_Event" 1 "PasSide_Crash_Detected" ;
VAL_ 133 ACU_Rear_Crash 0 "No_Event" 1 "Rear_Crash_Detected" ;
VAL_ 133 ACU_Rollover_Crash 0 "No_Event" 1 "Rollover_Crash_Detected" ;
VAL_ 162 WLS_SwitchStuck_State_RR 0 "Normal" 1 "Switch Stuck" ;
VAL_ 162 WLS_SwitchStuck_State_RL 0 "Normal" 1 "Switch Stuck" ;
VAL_ 162 WLS_SwitchStuck_State_FR 0 "Normal" 1 "Switch Stuck" ;
VAL_ 162 WLS_SwitchStuck_State_FL 0 "Normal" 1 "Switch Stuck" ;
VAL_ 162 WLS_WindowBtnPress_FL 0 "No action" 1 "Pull up 1st stage" 2 "Pull up 2nd stage" 3 "Press down 1st stage" 4 "Press down 2nd stage" 5 "Fault" 7 "Invalid" ;
VAL_ 162 WLS_WindowBtnPress_FR 0 "No action" 1 "Pull up 1st stage" 2 "Pull up 2nd stage" 3 "Press down 1st stage" 4 "Press down 2nd stage" 5 "Fault" 7 "Invalid" ;
VAL_ 162 WLS_WindowBtnPress_RL 0 "No action" 1 "Pull up 1st stage" 2 "Pull up 2nd stage" 3 "Press down 1st stage" 4 "Press down 2nd stage" 5 "Fault" 7 "Invalid" ;
VAL_ 162 WLS_WindowBtnPress_RR 0 "No action" 1 "Pull up 1st stage" 2 "Pull up 2nd stage" 3 "Press down 1st stage" 4 "Press down 2nd stage" 5 "Fault" 7 "Invalid" ;
VAL_ 162 WLS_DoorLockbtnPress 0 "No press" 1 "Short Press" 2 "Long Press" 3 "Invalid" ;
VAL_ 176 CVC_Window_Control_FL 0 "No action" 1 "Manual open" 2 "Automatic open" 3 "Manual close" 4 "Automatic close" 5 "Slightly open" 6 "Lock window" 7 "Unlock window" 15 "Signal Invalid" ;
VAL_ 176 CVC_Window_Control_FR 0 "No action" 1 "Manual open" 2 "Automatic open" 3 "Manual close" 4 "Automatic close" 5 "Slightly open" 6 "Lock window" 7 "Unlock window" 15 "Signal Invalid" ;
VAL_ 176 CVC_Window_Control_RL 0 "No action" 1 "Manual open" 2 "Automatic open" 3 "Manual close" 4 "Automatic close" 5 "Slightly open" 6 "Lock window" 7 "Unlock window" 15 "Signal Invalid" ;
VAL_ 176 CVC_Window_Control_RR 0 "No action" 1 "Manual open" 2 "Automatic open" 3 "Manual close" 4 "Automatic close" 5 "Slightly open" 6 "Lock window" 7 "Unlock window" 15 "Signal Invalid" ;
VAL_ 176 CVC_Windows_Control_Global 0 "No action" 1 "Manual open" 2 "Automatic open" 3 "Manual close" 4 "Automatic close" 5 "Slightly open" 6 "Lock window" 7 "Unlock window" 15 "Signal Invalid" ;
VAL_ 176 CVC_Window_Control_Learning 0 "None" 1 "Window Learning FL" 2 "Window Learning FR" 3 "Window Learning RL" 4 "Window Learning RR" 5 "All windows learning" 6 "Invalid" ;
VAL_ 193 Ionizer_Set 0 "OFF" 1 "ON" 2 "Reserved" 3 "Invalid" ;
VAL_ 193 FrontBlowerRelay_Set 0 "No request" 1 "OFF" 2 "ON" 3 "Invalid" ;
VAL_ 196 CVC_CoolingFan_OnOff_Req 0 "Invalid" 1 "OFF" 2 "ON" ;
VAL_ 196 CVC_FEDSPump_OnOff_Req 0 "Invalid" 1 "OFF" 2 "ON" ;
VAL_ 196 CVC_BMSPump_OnOff_Req 0 "Invalid" 1 "OFF" 2 "ON" ;
VAL_ 196 CVC_REDSPump_OnOff_Req 0 "Invalid" 1 "OFF" 2 "ON" ;
VAL_ 196 CVC_HVMainRelay_OnOff_Req 0 "Invalid" 1 "OFF" 2 "ON" ;
VAL_ 197 CVC_BatteryChillerSOV_Req 0 "Invalid" 1 "OFF" 2 "ON" ;
VAL_ 197 CVC_EvapSOV_Req 0 "Invalid" 1 "SOV Open" 2 "SOV Close" ;
VAL_ 197 CVC_EvapSOV2_Req 0 "Invalid" 1 "SOV Open" 2 "SOV Close" ;
VAL_ 197 CVC_RearBlwCodeVehicle_Req 0 "Limit value1" 1 "Limit value2" ;
VAL_ 197 CVC_RearAPTC_OnOffRequest 0 "No request" 1 "OFF" 2 "ON" 3 "Invalid" ;
VAL_ 197 CVC_RearEXV_Move_Enbl_Req 0 "Ignore Commanded Position" 1 " Move to Commanded Position" ;
VAL_ 197 CVC_RearEXV_Init_Req 0 "No Request" 1 "start Init-Sequence" 2 "DCDC_ON" 3 "not defined" 4 "not defined" 5 "not defined" 6 "not defined" 7 "not defined" ;
VAL_ 201 FMCU_StsMCUFault 0 "No Fault" 1 "Fault level 1" 2 "Fault level 2" 3 "Fault level 3" 4 "Fault level 4" 5 "Fault level 5" 6 "Fault level 6" ;
VAL_ 201 FMCU_MotorSpdSts 0 "Valid" 1 "Invalid" ;
VAL_ 201 FMCU_MotorTqSts 0 "Valid" 1 "Invalid" ;
VAL_ 201 FMCU_CVC_CtrlMode 0 "Inactive" 1 "Torque control mode" 2 "Speed Control mode" 3 "Limphome" 4 "crawling" ;
VAL_ 201 FMCU_CVC_StsMode 0 "Init" 1 "LvStandby 12V" 5 "Standby" 6 "Torq" 7 "Speed" 9 "ActiveDischarge" 10 "Fault" 11 "PowerOff" 12 "AfterRun" ;
VAL_ 202 CVC_STAT_UserSettingAutoUnlock 0 "OFF" 1 "ON" 2 "Fault (Reserved)" 3 "Signal Invalid" ;
VAL_ 202 CVC_STAT_DoorSpdSensingLock 0 "OFF" 1 "10KMH" 2 "15KMH" 3 "20KMH" 4 "25KMH" 5 "Reserved" 6 "Faults" ;
VAL_ 202 CVC_STAT_RemoteLockFeedback 0 "Light" 1 "Horn" 2 "Light & Horn" 3 "OFF" 4 "Signal Invalid" ;
VAL_ 202 CVC_STAT_DoorUnlockOption 0 "Driver Door" 1 "All Doors" 2 "Fault" 3 "Invalid" ;
VAL_ 203 RMCU_StsMCUFault 0 "No Fault" 1 "Fault level 1" 2 "Fault level 2" 3 "Fault level 3" 4 "Fault level 4" 5 "Fault level 5" 6 "Fault level 6" ;
VAL_ 203 RMCU_MotorSpdValid 0 "Valid" 1 "Invalid" ;
VAL_ 203 RMCU_MotorTqValid 0 "Valid" 1 "Invalid" ;
VAL_ 203 RMCU_CVC_CtrlMode 0 "Inactive" 1 "Torque control mode" 2 "Speed Control mode" 3 "Limphome" 4 "crawling" ;
VAL_ 203 RMCU_CVC_StsMode 0 "Init" 1 "LvStandby 12V" 5 "Standby" 6 "Torq" 7 "Speed" 9 "ActiveDischarge" 10 "Fault" 11 "PowerOff" 12 "AfterRun" ;
VAL_ 210 DriverSideDoor_Lock_Req 0 "No request" 1 "Lock Fr/Rr Driver side doors" 2 "Unlock Fr/Rr Driver side doors" 3 "Unlock Driver door only" 4 "Reserved" 5 "Invalid" ;
VAL_ 210 CoDriverSideDoor_Lock_Req 0 "No request" 1 "Lock Fr/Rr CoDriver side doors" 2 "Unlock Fr/Rr CoDriver side doors" 3 "Reserved" 4 "Reserved" 5 "Invalid" ;
VAL_ 210 Bonnet_Lock_Req 0 "No request" 1 "Lock" 2 "Unlock" 3 "Reserved" 4 "Invalid" ;
VAL_ 210 Tailgate_Lock_Req 0 "No request" 1 "Lock" 2 "Unlock" 3 "Stop Movement" 4 "Invalid" ;
VAL_ 210 Fuel_Port_Lock_Req 0 "No request" 1 "Lock" 2 "Unlock" 3 "Reserved" 4 "Invalid" ;
VAL_ 210 CVC_TPMS_Control_LearningStart 0 "No action" 1 "Start" 2 "Stop" 3 "Signal Invalid" ;
VAL_ 210 KeyFOBSearch_Req 0 "No Request" 1 "Search request by all antennas" 2 "Search request by Immo antenna" 3 "Invalid" ;
VAL_ 210 HornRequest 0 "No Action" 1 "ON" 2 "OFF" ;
VAL_ 210 CVC_SET_FCAMHeated_Req 0 "No request" 1 "ON" 2 "OFF" 3 "Signal Invalid" ;
VAL_ 210 CVC_SteeringWheel_Req 0 "OFF" 1 "ON" 2 "Reserved" 3 "Reserved" ;
VAL_ 210 CentralLockLightRequest 0 "No request" 1 "OFF" 2 "ON" 3 "Invalid" ;
VAL_ 210 CVC_B_PowerOutlet_Req 0 "OFF" 1 "ON" 2 "Reserved" 3 "Signal invalid" ;
VAL_ 217 CVC_HVsystem_status 0 "Not ready" 1 "HV On" 2 "ReadyToDrive" 3 "Charging" 4 "Error" 5 "Reserved" 6 "Reserved" 7 "Reserved" ;
VAL_ 217 CVC_ACPD_Percent_Valid 0 "Valid" 1 "Invalid" ;
VAL_ 217 CVC_ACTGear 0 "P" 1 "R" 2 "N" 3 "D" 4 "Reserved" 5 "Reserved" 6 "Reserved" 7 "Fault" ;
VAL_ 217 CVC_ACTGearValid 0 "Valid" 1 "Invalid" ;
VAL_ 217 CVC_ACT_DriveMode 0 "Normal mode" 1 "ECO mode" 2 "Sport mode" 3 "Reserved" 4 "Reserved" 5 "Reserved" 6 "Reserved" 7 "Invalid" ;
VAL_ 217 CVC_ACT_DriveMode_Valid 0 "Valid" 1 "Invalid" ;
VAL_ 217 CVC_HV_DRVsystem_status 0 "Not available" 1 "Normal" 2 "Degration" 3 "Limphome" 4 "Error" 5 "Reserved" 6 "Reserved" 7 "Reserved" ;
VAL_ 217 CVC_Recu_BrakeLight_ON_Req 0 "Brake light OFF" 1 "Brake light ON" 2 "Reserved" 3 "Signal not available" ;
VAL_ 256 CVC_B_UserProfileId 0 "User 1 - Guess mode" 1 "User 2 - Valet mode" 2 "User 3" 3 "User 4" 4 "User 5" 5 "User 6" 6 "User 7" 7 "User 8" 8 "User 9" 9 "User 10" 15 "Invalid Value" ;
VAL_ 256 CVC_B_Connectivity_Status 0 "Init" 1 "No Connection" 2 "LTE Internet Connection" 3 "WIFI Internet Establish" 4 "WIFI + LTE Connection" 5 "Reserved" 6 "Reserved" 7 "Reserved" ;
VAL_ 258 STAT_CrankRelayHW_BCM 0 "OFF" 1 "ON" 2 "Reserved" 3 "Signal invalid" ;
VAL_ 258 CVC_Transport_Mode 0 "OFF" 1 "ON" 2 "Reserved" 3 "Invalid" ;
VAL_ 258 CVC_Vehicle_Special_Mode 0 "None" 1 "Camp mode" 2 "Pet mode" 3 "Showroom mode" 4 "Tow mode" 5 "Reserved" 6 "Reserved" 7 "Signal invalid" ;
VAL_ 258 CVC_Acc_Mode_Req 0 "No request" 1 "ACC state request" 2 "Reserved" 3 "Signal invalid" ;
VAL_ 258 CVC_CL30s_Req 0 "OFF" 1 "ON" 2 "Reserved" 3 "Invalid" ;
VAL_ 258 CVC_CL30c_Req 0 "OFF" 1 "ON" 2 "Reserved" 3 "Invalid" ;
VAL_ 258 CVC_CLR_Req 0 "OFF" 1 "ON" 2 "Reserved" 3 "Invalid" ;
VAL_ 258 CVC_CL15_Req 0 "OFF" 1 "ON" 2 "Reserved" 3 "Invalid" ;
VAL_ 258 Warning_Clamp_Incompatible 0 "None" 1 "Alert" 2 "Reserved" 3 "Reserved" ;
VAL_ 258 CVC_CL58_Req 0 "OFF" 1 "ON" 2 "Reserved" 3 "Invalid" ;
VAL_ 264 SS_P_Button 0 "Not Pressed" 1 "Pressed" 2 "Reserved" 3 "Invalid" ;
VAL_ 264 SS_TargetGearReq 0 "No Request" 1 "N1" 2 "N2" 3 "R" 4 "D" 5 "Reserved" 6 "Reserved" 7 "Invalid" ;
VAL_ 264 SS_ADAS_Req 0 "No Request" 1 "Action 1 request" 2 "Action 2 request" 3 "Action 3 request" 4 "Action 4 request" 5 "Reserved" 6 "Reserved" 7 "Invalid" ;
VAL_ 264 SS_DrvMd_RgnLvl_Req 0 "No Request" 1 "Revole UP" 2 "Revole DOWN" 3 "Revole Invalid" ;
VAL_ 264 SS_Fault 0 "normal" 1 "Shifter failure" 2 "CAN communication fail" 3 "Position sensor failure" 4 "Supply voltage failure" 5 "P button fault" 6 "Received Date from BCM is invalid" 7 "MCU FAULT" 8 "Reserved" 9 "Reserved" 10 "Reserved" 11 "Reserved" 12 "Reserved" 13 "Reserved" 14 "Reserved" 15 "Reserved" ;
VAL_ 264 SS_HighBeam_Req 0 "No Request" 1 "Manual High beam Request" 2 "Flashing high beam" 3 "Invalid" ;
VAL_ 264 SS_Lane_Change_Indicator_Req 0 "OFF" 1 "Left lane change" 2 "Right lane change" 3 "Left On" 4 "Right On" 5 "Reserved" 6 "Reserved" 7 "Invalid" ;
VAL_ 264 SS_FR_RR_WashAndMist_Req 0 "No request" 1 "Rotate Upward Short Hold" 2 "Rotate Upward Long Hold" 3 "Rotate Downward Short Hold" 4 "Rotate Downward Long Hold" 5 "Reserved" 6 "Reserved" 7 "Invalid" ;
VAL_ 264 SS_RR_WiperControl_Req 0 " No action" 1 "Button push" 2 "Reserved" 3 "Invalid" ;
VAL_ 264 SS_FR_Wipercontrol_Req 0 "OFF" 1 "Mode 1" 2 "Mode 2" 3 "Mode 3" 4 "Invalid" ;
